VERSION ""

NS_ :

BS_:

BU_:  Inverter  Battery  Charger  Host

BO_ 2483290116 BATT_modStatus_4: 8 Battery
 SG_ BATT_modNumModsDataValid_4 : 60|4@1+ (1,0) [0|15] "" Battery,Host
 SG_ BATT_modNumModsOnNetwork_4 : 52|4@1+ (1,0) [0|15] "" Battery,Host
 SG_ BATT_modNumModsOnHvBus_4 : 56|4@1+ (1,0) [0|15] "" Battery,Host
 SG_ BATT_modNumModsConfigured_4 : 48|4@1+ (1,0) [0|15] "" Battery,Host
 SG_ BATT_ArbitrationComplete_4 : 15|1@1+ (1,0) [0|1] "" Battery,Host
 SG_ BATT_modStateRequested_4 : 46|2@1+ (1,0) [0|3] "" Battery,Host
 SG_ BATT_modDataValid_4 : 7|1@1+ (1,0) [0|1] "" Battery,Host
 SG_ BATT_prechargeState_4 : 43|3@1+ (1,0) [0|7] "" Battery,Host
 SG_ BATT_fetPchgCommand_4 : 42|1@1+ (1,0) [0|1] "" Battery,Host
 SG_ BATT_fetDsgCommand_4 : 40|1@1+ (1,0) [0|1] "" Battery,Host
 SG_ BATT_fetChgCommand_4 : 41|1@1+ (1,0) [0|1] "" Battery,Host
 SG_ BATT_fetDsgStatus_4 : 36|4@1+ (1,0) [0|15] "" Battery,Host
 SG_ BATT_fetChgStatus_4 : 32|4@1+ (1,0) [0|15] "" Battery,Host
 SG_ BATT_timeRampdown_4 : 24|6@1+ (1,0) [0|63] "seconds" Battery,Host
 SG_ BATT_inhRegen_4 : 31|1@1+ (1,0) [0|1] "" Battery,Host
 SG_ BATT_inhFullPower_4 : 23|1@1+ (1,0) [0|1] "" Battery,Host
 SG_ BATT_inhDriveEntry_4 : 22|1@1+ (1,0) [0|1] "" Battery,Host
 SG_ BATT_inhDrive_4 : 21|1@1+ (1,0) [0|1] "" Battery,Host
 SG_ BATT_inhContPower_4 : 30|1@1+ (1,0) [0|1] "" Battery,Host
 SG_ BATT_inhChargeEntry_4 : 19|1@1+ (1,0) [0|1] "" Battery,Host
 SG_ BATT_inhCharge_4 : 20|1@1+ (1,0) [0|1] "" Battery,Host
 SG_ BATT_modPackState_4 : 8|4@1+ (1,0) [0|15] "" Battery,Host
 SG_ BATT_modPchgChargeID_4 : 12|3@1+ (1,0) [0|7] "" Battery,Host
 SG_ BATT_modChildState_4 : 3|4@1+ (1,0) [0|15] "" Battery,Host
 SG_ BATT_modPchgDriveID_4 : 16|3@1+ (1,0) [0|7] "" Battery,Host
 SG_ BATT_modParentState_4 : 0|3@1+ (1,0) [0|4] "" Battery,Host

BO_ 2483290117 BATT_modStatus_5: 8 Battery
 SG_ BATT_modNumModsDataValid_5 : 60|4@1+ (1,0) [0|15] "" Battery,Host
 SG_ BATT_modNumModsOnNetwork_5 : 52|4@1+ (1,0) [0|15] "" Battery,Host
 SG_ BATT_modNumModsOnHvBus_5 : 56|4@1+ (1,0) [0|15] "" Battery,Host
 SG_ BATT_modNumModsConfigured_5 : 48|4@1+ (1,0) [0|15] "" Battery,Host
 SG_ BATT_ArbitrationComplete_5 : 15|1@1+ (1,0) [0|1] "" Battery,Host
 SG_ BATT_modStateRequested_5 : 46|2@1+ (1,0) [0|3] "" Battery,Host
 SG_ BATT_modDataValid_5 : 7|1@1+ (1,0) [0|1] "" Battery,Host
 SG_ BATT_prechargeState_5 : 43|3@1+ (1,0) [0|7] "" Battery,Host
 SG_ BATT_fetPchgCommand_5 : 42|1@1+ (1,0) [0|1] "" Battery,Host
 SG_ BATT_fetDsgCommand_5 : 40|1@1+ (1,0) [0|1] "" Battery,Host
 SG_ BATT_fetChgCommand_5 : 41|1@1+ (1,0) [0|1] "" Battery,Host
 SG_ BATT_fetDsgStatus_5 : 36|4@1+ (1,0) [0|15] "" Battery,Host
 SG_ BATT_fetChgStatus_5 : 32|4@1+ (1,0) [0|15] "" Battery,Host
 SG_ BATT_timeRampdown_5 : 24|6@1+ (1,0) [0|63] "seconds" Battery,Host
 SG_ BATT_inhRegen_5 : 31|1@1+ (1,0) [0|1] "" Battery,Host
 SG_ BATT_inhFullPower_5 : 23|1@1+ (1,0) [0|1] "" Battery,Host
 SG_ BATT_inhDriveEntry_5 : 22|1@1+ (1,0) [0|1] "" Battery,Host
 SG_ BATT_inhDrive_5 : 21|1@1+ (1,0) [0|1] "" Battery,Host
 SG_ BATT_inhContPower_5 : 30|1@1+ (1,0) [0|1] "" Battery,Host
 SG_ BATT_inhChargeEntry_5 : 19|1@1+ (1,0) [0|1] "" Battery,Host
 SG_ BATT_inhCharge_5 : 20|1@1+ (1,0) [0|1] "" Battery,Host
 SG_ BATT_modPackState_5 : 8|4@1+ (1,0) [0|15] "" Battery,Host
 SG_ BATT_modPchgChargeID_5 : 12|3@1+ (1,0) [0|7] "" Battery,Host
 SG_ BATT_modChildState_5 : 3|4@1+ (1,0) [0|15] "" Battery,Host
 SG_ BATT_modPchgDriveID_5 : 16|3@1+ (1,0) [0|7] "" Battery,Host
 SG_ BATT_modParentState_5 : 0|3@1+ (1,0) [0|4] "" Battery,Host

BO_ 2483290118 BATT_modStatus_6: 8 Battery
 SG_ BATT_modNumModsDataValid_6 : 60|4@1+ (1,0) [0|15] "" Battery,Host
 SG_ BATT_modNumModsOnNetwork_6 : 52|4@1+ (1,0) [0|15] "" Battery,Host
 SG_ BATT_modNumModsOnHvBus_6 : 56|4@1+ (1,0) [0|15] "" Battery,Host
 SG_ BATT_modNumModsConfigured_6 : 48|4@1+ (1,0) [0|15] "" Battery,Host
 SG_ BATT_ArbitrationComplete_6 : 15|1@1+ (1,0) [0|1] "" Battery,Host
 SG_ BATT_modStateRequested_6 : 46|2@1+ (1,0) [0|3] "" Battery,Host
 SG_ BATT_modDataValid_6 : 7|1@1+ (1,0) [0|1] "" Battery,Host
 SG_ BATT_prechargeState_6 : 43|3@1+ (1,0) [0|7] "" Battery,Host
 SG_ BATT_fetPchgCommand_6 : 42|1@1+ (1,0) [0|1] "" Battery,Host
 SG_ BATT_fetDsgCommand_6 : 40|1@1+ (1,0) [0|1] "" Battery,Host
 SG_ BATT_fetChgCommand_6 : 41|1@1+ (1,0) [0|1] "" Battery,Host
 SG_ BATT_fetDsgStatus_6 : 36|4@1+ (1,0) [0|15] "" Battery,Host
 SG_ BATT_fetChgStatus_6 : 32|4@1+ (1,0) [0|15] "" Battery,Host
 SG_ BATT_timeRampdown_6 : 24|6@1+ (1,0) [0|63] "seconds" Battery,Host
 SG_ BATT_inhRegen_6 : 31|1@1+ (1,0) [0|1] "" Battery,Host
 SG_ BATT_inhFullPower_6 : 23|1@1+ (1,0) [0|1] "" Battery,Host
 SG_ BATT_inhDriveEntry_6 : 22|1@1+ (1,0) [0|1] "" Battery,Host
 SG_ BATT_inhDrive_6 : 21|1@1+ (1,0) [0|1] "" Battery,Host
 SG_ BATT_inhContPower_6 : 30|1@1+ (1,0) [0|1] "" Battery,Host
 SG_ BATT_inhChargeEntry_6 : 19|1@1+ (1,0) [0|1] "" Battery,Host
 SG_ BATT_inhCharge_6 : 20|1@1+ (1,0) [0|1] "" Battery,Host
 SG_ BATT_modPackState_6 : 8|4@1+ (1,0) [0|15] "" Battery,Host
 SG_ BATT_modPchgChargeID_6 : 12|3@1+ (1,0) [0|7] "" Battery,Host
 SG_ BATT_modChildState_6 : 3|4@1+ (1,0) [0|15] "" Battery,Host
 SG_ BATT_modPchgDriveID_6 : 16|3@1+ (1,0) [0|7] "" Battery,Host
 SG_ BATT_modParentState_6 : 0|3@1+ (1,0) [0|4] "" Battery,Host

BO_ 2483290119 BATT_modStatus_7: 8 Battery
 SG_ BATT_modNumModsDataValid_7 : 60|4@1+ (1,0) [0|15] "" Battery,Host
 SG_ BATT_modNumModsOnNetwork_7 : 52|4@1+ (1,0) [0|15] "" Battery,Host
 SG_ BATT_modNumModsOnHvBus_7 : 56|4@1+ (1,0) [0|15] "" Battery,Host
 SG_ BATT_modNumModsConfigured_7 : 48|4@1+ (1,0) [0|15] "" Battery,Host
 SG_ BATT_ArbitrationComplete_7 : 15|1@1+ (1,0) [0|1] "" Battery,Host
 SG_ BATT_modStateRequested_7 : 46|2@1+ (1,0) [0|3] "" Battery,Host
 SG_ BATT_modDataValid_7 : 7|1@1+ (1,0) [0|1] "" Battery,Host
 SG_ BATT_prechargeState_7 : 43|3@1+ (1,0) [0|7] "" Battery,Host
 SG_ BATT_fetPchgCommand_7 : 42|1@1+ (1,0) [0|1] "" Battery,Host
 SG_ BATT_fetDsgCommand_7 : 40|1@1+ (1,0) [0|1] "" Battery,Host
 SG_ BATT_fetChgCommand_7 : 41|1@1+ (1,0) [0|1] "" Battery,Host
 SG_ BATT_fetDsgStatus_7 : 36|4@1+ (1,0) [0|15] "" Battery,Host
 SG_ BATT_fetChgStatus_7 : 32|4@1+ (1,0) [0|15] "" Battery,Host
 SG_ BATT_timeRampdown_7 : 24|6@1+ (1,0) [0|63] "seconds" Battery,Host
 SG_ BATT_inhRegen_7 : 31|1@1+ (1,0) [0|1] "" Battery,Host
 SG_ BATT_inhFullPower_7 : 23|1@1+ (1,0) [0|1] "" Battery,Host
 SG_ BATT_inhDriveEntry_7 : 22|1@1+ (1,0) [0|1] "" Battery,Host
 SG_ BATT_inhDrive_7 : 21|1@1+ (1,0) [0|1] "" Battery,Host
 SG_ BATT_inhContPower_7 : 30|1@1+ (1,0) [0|1] "" Battery,Host
 SG_ BATT_inhChargeEntry_7 : 19|1@1+ (1,0) [0|1] "" Battery,Host
 SG_ BATT_inhCharge_7 : 20|1@1+ (1,0) [0|1] "" Battery,Host
 SG_ BATT_modPackState_7 : 8|4@1+ (1,0) [0|15] "" Battery,Host
 SG_ BATT_modPchgChargeID_7 : 12|3@1+ (1,0) [0|7] "" Battery,Host
 SG_ BATT_modChildState_7 : 3|4@1+ (1,0) [0|15] "" Battery,Host
 SG_ BATT_modPchgDriveID_7 : 16|3@1+ (1,0) [0|7] "" Battery,Host
 SG_ BATT_modParentState_7 : 0|3@1+ (1,0) [0|4] "" Battery,Host

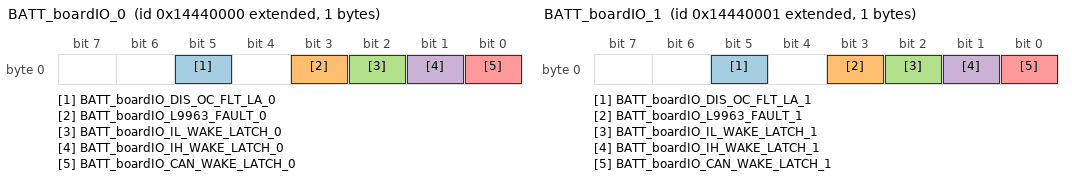
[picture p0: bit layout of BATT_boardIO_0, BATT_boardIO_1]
BO_ 2487484416 BATT_boardIO_0: 1 Battery
 SG_ BATT_boardIO_DIS_OC_FLT_LA_0 : 5|1@1+ (1,0) [0|1] "" Host
 SG_ BATT_boardIO_L9963_FAULT_0 : 3|1@1+ (1,0) [0|1] "" Host
 SG_ BATT_boardIO_IL_WAKE_LATCH_0 : 2|1@1+ (1,0) [0|1] "" Host
 SG_ BATT_boardIO_IH_WAKE_LATCH_0 : 1|1@1+ (1,0) [0|1] "" Host
 SG_ BATT_boardIO_CAN_WAKE_LATCH_0 : 0|1@1+ (1,0) [0|1] "" Host

BO_ 2487484417 BATT_boardIO_1: 1 Battery
 SG_ BATT_boardIO_DIS_OC_FLT_LA_1 : 5|1@1+ (1,0) [0|1] "" Host
 SG_ BATT_boardIO_L9963_FAULT_1 : 3|1@1+ (1,0) [0|1] "" Host
 SG_ BATT_boardIO_IL_WAKE_LATCH_1 : 2|1@1+ (1,0) [0|1] "" Host
 SG_ BATT_boardIO_IH_WAKE_LATCH_1 : 1|1@1+ (1,0) [0|1] "" Host
 SG_ BATT_boardIO_CAN_WAKE_LATCH_1 : 0|1@1+ (1,0) [0|1] "" Host

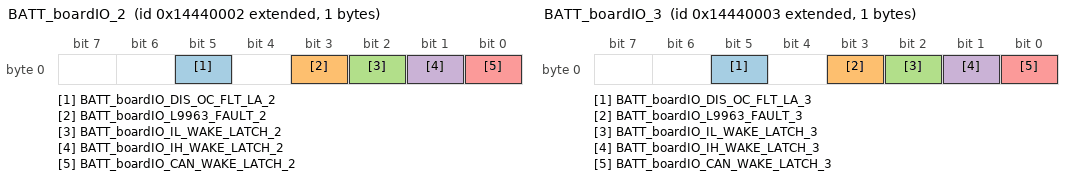
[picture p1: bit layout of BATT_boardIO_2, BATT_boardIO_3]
BO_ 2487484418 BATT_boardIO_2: 1 Battery
 SG_ BATT_boardIO_DIS_OC_FLT_LA_2 : 5|1@1+ (1,0) [0|1] "" Host
 SG_ BATT_boardIO_L9963_FAULT_2 : 3|1@1+ (1,0) [0|1] "" Host
 SG_ BATT_boardIO_IL_WAKE_LATCH_2 : 2|1@1+ (1,0) [0|1] "" Host
 SG_ BATT_boardIO_IH_WAKE_LATCH_2 : 1|1@1+ (1,0) [0|1] "" Host
 SG_ BATT_boardIO_CAN_WAKE_LATCH_2 : 0|1@1+ (1,0) [0|1] "" Host

BO_ 2487484419 BATT_boardIO_3: 1 Battery
 SG_ BATT_boardIO_DIS_OC_FLT_LA_3 : 5|1@1+ (1,0) [0|1] "" Host
 SG_ BATT_boardIO_L9963_FAULT_3 : 3|1@1+ (1,0) [0|1] "" Host
 SG_ BATT_boardIO_IL_WAKE_LATCH_3 : 2|1@1+ (1,0) [0|1] "" Host
 SG_ BATT_boardIO_IH_WAKE_LATCH_3 : 1|1@1+ (1,0) [0|1] "" Host
 SG_ BATT_boardIO_CAN_WAKE_LATCH_3 : 0|1@1+ (1,0) [0|1] "" Host

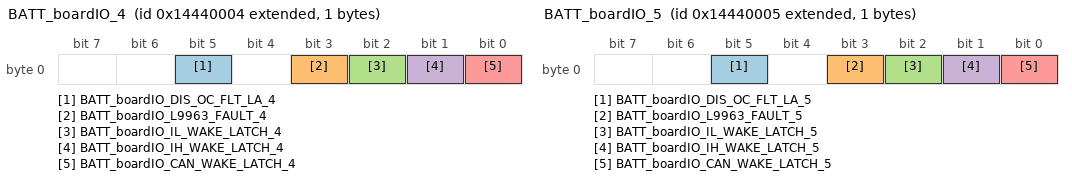
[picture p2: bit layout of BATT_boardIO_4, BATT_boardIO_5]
BO_ 2487484420 BATT_boardIO_4: 1 Battery
 SG_ BATT_boardIO_DIS_OC_FLT_LA_4 : 5|1@1+ (1,0) [0|1] "" Host
 SG_ BATT_boardIO_L9963_FAULT_4 : 3|1@1+ (1,0) [0|1] "" Host
 SG_ BATT_boardIO_IL_WAKE_LATCH_4 : 2|1@1+ (1,0) [0|1] "" Host
 SG_ BATT_boardIO_IH_WAKE_LATCH_4 : 1|1@1+ (1,0) [0|1] "" Host
 SG_ BATT_boardIO_CAN_WAKE_LATCH_4 : 0|1@1+ (1,0) [0|1] "" Host

BO_ 2487484421 BATT_boardIO_5: 1 Battery
 SG_ BATT_boardIO_DIS_OC_FLT_LA_5 : 5|1@1+ (1,0) [0|1] "" Host
 SG_ BATT_boardIO_L9963_FAULT_5 : 3|1@1+ (1,0) [0|1] "" Host
 SG_ BATT_boardIO_IL_WAKE_LATCH_5 : 2|1@1+ (1,0) [0|1] "" Host
 SG_ BATT_boardIO_IH_WAKE_LATCH_5 : 1|1@1+ (1,0) [0|1] "" Host
 SG_ BATT_boardIO_CAN_WAKE_LATCH_5 : 0|1@1+ (1,0) [0|1] "" Host

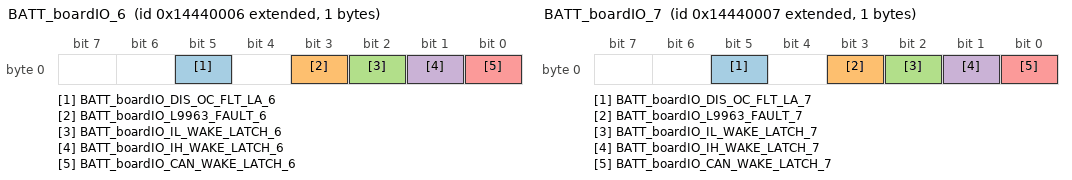
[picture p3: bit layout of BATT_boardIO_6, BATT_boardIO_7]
BO_ 2487484422 BATT_boardIO_6: 1 Battery
 SG_ BATT_boardIO_DIS_OC_FLT_LA_6 : 5|1@1+ (1,0) [0|1] "" Host
 SG_ BATT_boardIO_L9963_FAULT_6 : 3|1@1+ (1,0) [0|1] "" Host
 SG_ BATT_boardIO_IL_WAKE_LATCH_6 : 2|1@1+ (1,0) [0|1] "" Host
 SG_ BATT_boardIO_IH_WAKE_LATCH_6 : 1|1@1+ (1,0) [0|1] "" Host
 SG_ BATT_boardIO_CAN_WAKE_LATCH_6 : 0|1@1+ (1,0) [0|1] "" Host

BO_ 2487484423 BATT_boardIO_7: 1 Battery
 SG_ BATT_boardIO_DIS_OC_FLT_LA_7 : 5|1@1+ (1,0) [0|1] "" Host
 SG_ BATT_boardIO_L9963_FAULT_7 : 3|1@1+ (1,0) [0|1] "" Host
 SG_ BATT_boardIO_IL_WAKE_LATCH_7 : 2|1@1+ (1,0) [0|1] "" Host
 SG_ BATT_boardIO_IH_WAKE_LATCH_7 : 1|1@1+ (1,0) [0|1] "" Host
 SG_ BATT_boardIO_CAN_WAKE_LATCH_7 : 0|1@1+ (1,0) [0|1] "" Host

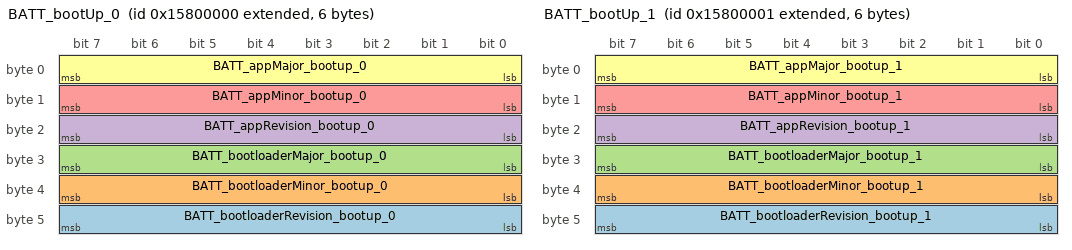
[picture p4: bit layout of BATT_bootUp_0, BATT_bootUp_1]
BO_ 2508193792 BATT_bootUp_0: 6 Battery
 SG_ BATT_bootloaderRevision_bootup_0 : 40|8@1+ (1,0) [0|255] "" Host
 SG_ BATT_bootloaderMinor_bootup_0 : 32|8@1+ (1,0) [0|255] "" Host
 SG_ BATT_bootloaderMajor_bootup_0 : 24|8@1+ (1,0) [0|255] "" Host
 SG_ BATT_appRevision_bootup_0 : 16|8@1+ (1,0) [0|255] "" Host
 SG_ BATT_appMinor_bootup_0 : 8|8@1+ (1,0) [0|255] "" Host
 SG_ BATT_appMajor_bootup_0 : 0|8@1+ (1,0) [0|255] "" Host

BO_ 2508193793 BATT_bootUp_1: 6 Battery
 SG_ BATT_bootloaderRevision_bootup_1 : 40|8@1+ (1,0) [0|255] "" Host
 SG_ BATT_bootloaderMinor_bootup_1 : 32|8@1+ (1,0) [0|255] "" Host
 SG_ BATT_bootloaderMajor_bootup_1 : 24|8@1+ (1,0) [0|255] "" Host
 SG_ BATT_appRevision_bootup_1 : 16|8@1+ (1,0) [0|255] "" Host
 SG_ BATT_appMinor_bootup_1 : 8|8@1+ (1,0) [0|255] "" Host
 SG_ BATT_appMajor_bootup_1 : 0|8@1+ (1,0) [0|255] "" Host

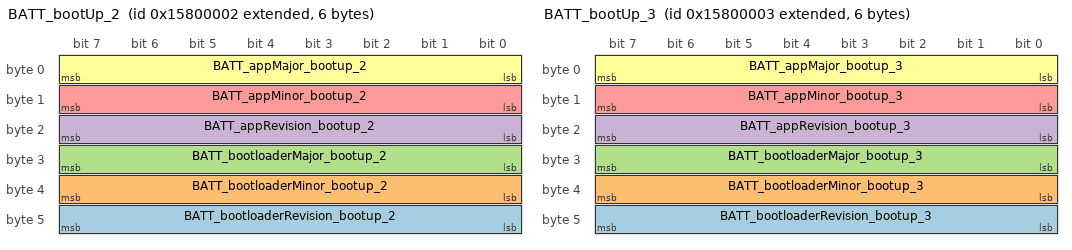
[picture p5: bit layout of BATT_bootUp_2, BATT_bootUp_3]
BO_ 2508193794 BATT_bootUp_2: 6 Battery
 SG_ BATT_bootloaderRevision_bootup_2 : 40|8@1+ (1,0) [0|255] "" Host
 SG_ BATT_bootloaderMinor_bootup_2 : 32|8@1+ (1,0) [0|255] "" Host
 SG_ BATT_bootloaderMajor_bootup_2 : 24|8@1+ (1,0) [0|255] "" Host
 SG_ BATT_appRevision_bootup_2 : 16|8@1+ (1,0) [0|255] "" Host
 SG_ BATT_appMinor_bootup_2 : 8|8@1+ (1,0) [0|255] "" Host
 SG_ BATT_appMajor_bootup_2 : 0|8@1+ (1,0) [0|255] "" Host

BO_ 2508193795 BATT_bootUp_3: 6 Battery
 SG_ BATT_bootloaderRevision_bootup_3 : 40|8@1+ (1,0) [0|255] "" Host
 SG_ BATT_bootloaderMinor_bootup_3 : 32|8@1+ (1,0) [0|255] "" Host
 SG_ BATT_bootloaderMajor_bootup_3 : 24|8@1+ (1,0) [0|255] "" Host
 SG_ BATT_appRevision_bootup_3 : 16|8@1+ (1,0) [0|255] "" Host
 SG_ BATT_appMinor_bootup_3 : 8|8@1+ (1,0) [0|255] "" Host
 SG_ BATT_appMajor_bootup_3 : 0|8@1+ (1,0) [0|255] "" Host

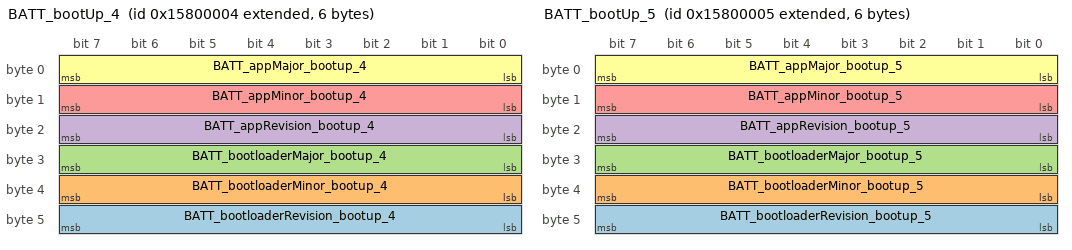
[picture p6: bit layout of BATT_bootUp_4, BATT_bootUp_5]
BO_ 2508193796 BATT_bootUp_4: 6 Battery
 SG_ BATT_bootloaderRevision_bootup_4 : 40|8@1+ (1,0) [0|255] "" Host
 SG_ BATT_bootloaderMinor_bootup_4 : 32|8@1+ (1,0) [0|255] "" Host
 SG_ BATT_bootloaderMajor_bootup_4 : 24|8@1+ (1,0) [0|255] "" Host
 SG_ BATT_appRevision_bootup_4 : 16|8@1+ (1,0) [0|255] "" Host
 SG_ BATT_appMinor_bootup_4 : 8|8@1+ (1,0) [0|255] "" Host
 SG_ BATT_appMajor_bootup_4 : 0|8@1+ (1,0) [0|255] "" Host

BO_ 2508193797 BATT_bootUp_5: 6 Battery
 SG_ BATT_bootloaderRevision_bootup_5 : 40|8@1+ (1,0) [0|255] "" Host
 SG_ BATT_bootloaderMinor_bootup_5 : 32|8@1+ (1,0) [0|255] "" Host
 SG_ BATT_bootloaderMajor_bootup_5 : 24|8@1+ (1,0) [0|255] "" Host
 SG_ BATT_appRevision_bootup_5 : 16|8@1+ (1,0) [0|255] "" Host
 SG_ BATT_appMinor_bootup_5 : 8|8@1+ (1,0) [0|255] "" Host
 SG_ BATT_appMajor_bootup_5 : 0|8@1+ (1,0) [0|255] "" Host

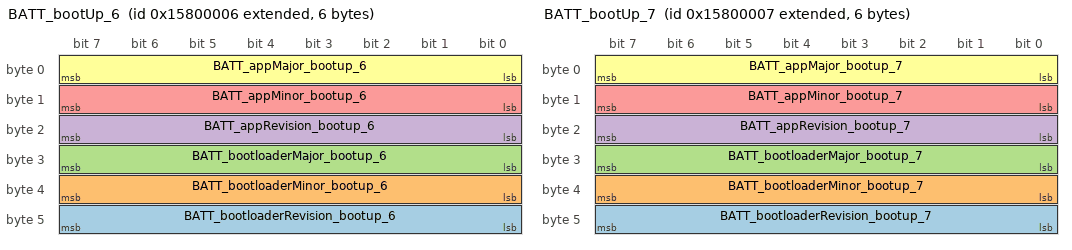
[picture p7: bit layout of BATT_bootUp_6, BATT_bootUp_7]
BO_ 2508193798 BATT_bootUp_6: 6 Battery
 SG_ BATT_bootloaderRevision_bootup_6 : 40|8@1+ (1,0) [0|255] "" Host
 SG_ BATT_bootloaderMinor_bootup_6 : 32|8@1+ (1,0) [0|255] "" Host
 SG_ BATT_bootloaderMajor_bootup_6 : 24|8@1+ (1,0) [0|255] "" Host
 SG_ BATT_appRevision_bootup_6 : 16|8@1+ (1,0) [0|255] "" Host
 SG_ BATT_appMinor_bootup_6 : 8|8@1+ (1,0) [0|255] "" Host
 SG_ BATT_appMajor_bootup_6 : 0|8@1+ (1,0) [0|255] "" Host

BO_ 2508193799 BATT_bootUp_7: 6 Battery
 SG_ BATT_bootloaderRevision_bootup_7 : 40|8@1+ (1,0) [0|255] "" Host
 SG_ BATT_bootloaderMinor_bootup_7 : 32|8@1+ (1,0) [0|255] "" Host
 SG_ BATT_bootloaderMajor_bootup_7 : 24|8@1+ (1,0) [0|255] "" Host
 SG_ BATT_appRevision_bootup_7 : 16|8@1+ (1,0) [0|255] "" Host
 SG_ BATT_appMinor_bootup_7 : 8|8@1+ (1,0) [0|255] "" Host
 SG_ BATT_appMajor_bootup_7 : 0|8@1+ (1,0) [0|255] "" Host

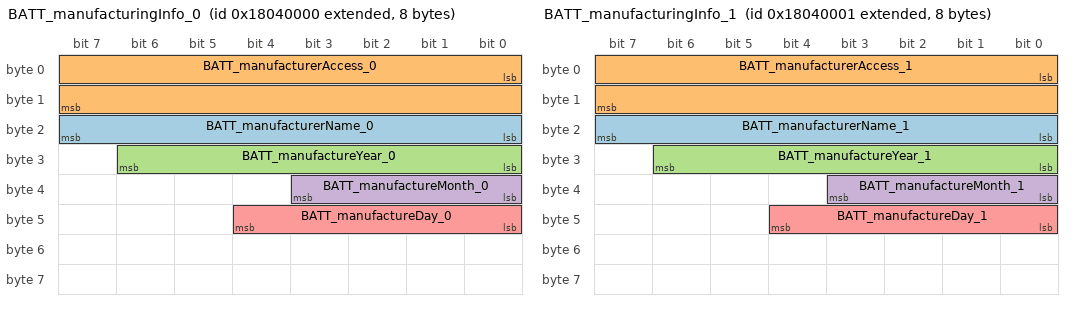
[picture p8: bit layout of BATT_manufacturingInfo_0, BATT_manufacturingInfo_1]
BO_ 2550398976 BATT_manufacturingInfo_0: 8 Battery
 SG_ BATT_manufacturerName_0 : 16|8@1+ (1,0) [0|255] "STRING" Host
 SG_ BATT_manufacturerAccess_0 : 0|16@1+ (1,0) [0|65535] "" Host
 SG_ BATT_manufactureYear_0 : 24|7@1+ (1,0) [0|127] "" Host
 SG_ BATT_manufactureMonth_0 : 32|4@1+ (1,0) [1|12] "" Host
 SG_ BATT_manufactureDay_0 : 40|5@1+ (1,0) [1|31] "" Host

BO_ 2550398977 BATT_manufacturingInfo_1: 8 Battery
 SG_ BATT_manufacturerName_1 : 16|8@1+ (1,0) [0|255] "STRING" Host
 SG_ BATT_manufacturerAccess_1 : 0|16@1+ (1,0) [0|65535] "" Host
 SG_ BATT_manufactureYear_1 : 24|7@1+ (1,0) [0|127] "" Host
 SG_ BATT_manufactureMonth_1 : 32|4@1+ (1,0) [1|12] "" Host
 SG_ BATT_manufactureDay_1 : 40|5@1+ (1,0) [1|31] "" Host

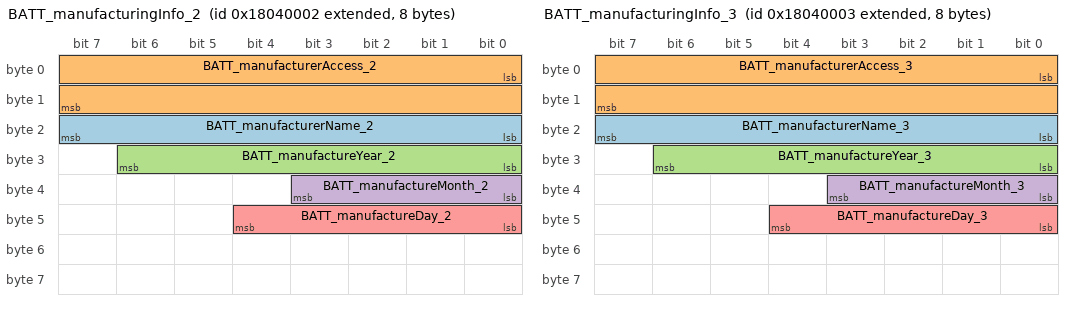
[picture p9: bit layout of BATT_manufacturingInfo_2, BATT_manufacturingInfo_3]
BO_ 2550398978 BATT_manufacturingInfo_2: 8 Battery
 SG_ BATT_manufacturerName_2 : 16|8@1+ (1,0) [0|255] "STRING" Host
 SG_ BATT_manufacturerAccess_2 : 0|16@1+ (1,0) [0|65535] "" Host
 SG_ BATT_manufactureYear_2 : 24|7@1+ (1,0) [0|127] "" Host
 SG_ BATT_manufactureMonth_2 : 32|4@1+ (1,0) [1|12] "" Host
 SG_ BATT_manufactureDay_2 : 40|5@1+ (1,0) [1|31] "" Host

BO_ 2550398979 BATT_manufacturingInfo_3: 8 Battery
 SG_ BATT_manufacturerName_3 : 16|8@1+ (1,0) [0|255] "STRING" Host
 SG_ BATT_manufacturerAccess_3 : 0|16@1+ (1,0) [0|65535] "" Host
 SG_ BATT_manufactureYear_3 : 24|7@1+ (1,0) [0|127] "" Host
 SG_ BATT_manufactureMonth_3 : 32|4@1+ (1,0) [1|12] "" Host
 SG_ BATT_manufactureDay_3 : 40|5@1+ (1,0) [1|31] "" Host

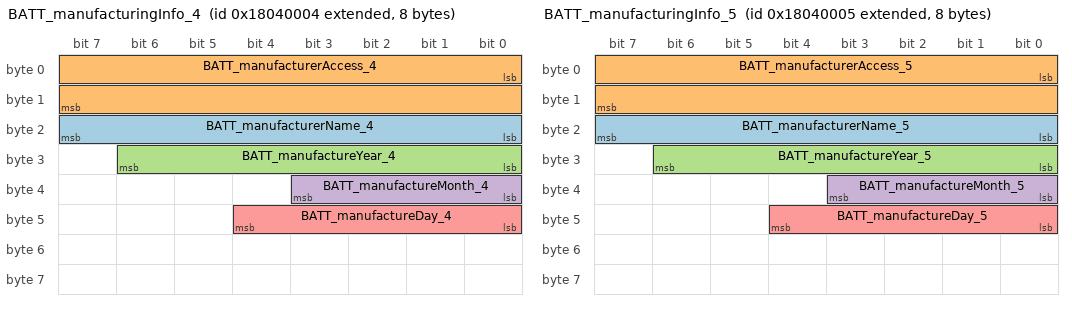
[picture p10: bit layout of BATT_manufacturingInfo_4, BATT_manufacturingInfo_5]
BO_ 2550398980 BATT_manufacturingInfo_4: 8 Battery
 SG_ BATT_manufacturerName_4 : 16|8@1+ (1,0) [0|255] "STRING" Host
 SG_ BATT_manufacturerAccess_4 : 0|16@1+ (1,0) [0|65535] "" Host
 SG_ BATT_manufactureYear_4 : 24|7@1+ (1,0) [0|127] "" Host
 SG_ BATT_manufactureMonth_4 : 32|4@1+ (1,0) [1|12] "" Host
 SG_ BATT_manufactureDay_4 : 40|5@1+ (1,0) [1|31] "" Host

BO_ 2550398981 BATT_manufacturingInfo_5: 8 Battery
 SG_ BATT_manufacturerName_5 : 16|8@1+ (1,0) [0|255] "STRING" Host
 SG_ BATT_manufacturerAccess_5 : 0|16@1+ (1,0) [0|65535] "" Host
 SG_ BATT_manufactureYear_5 : 24|7@1+ (1,0) [0|127] "" Host
 SG_ BATT_manufactureMonth_5 : 32|4@1+ (1,0) [1|12] "" Host
 SG_ BATT_manufactureDay_5 : 40|5@1+ (1,0) [1|31] "" Host

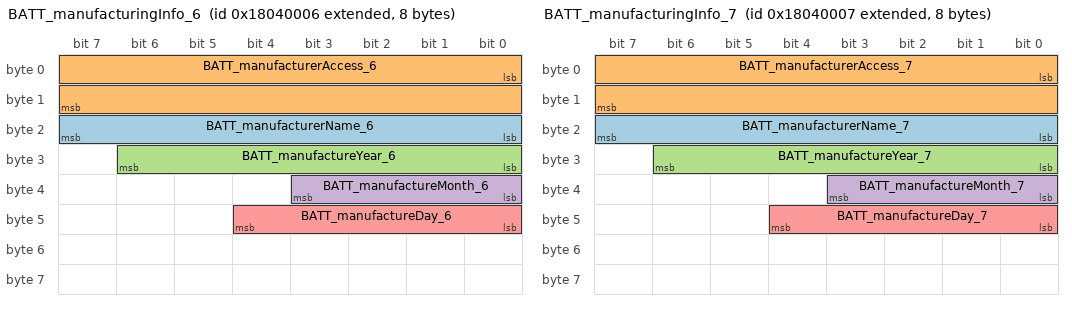
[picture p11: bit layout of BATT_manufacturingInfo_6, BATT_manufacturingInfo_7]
BO_ 2550398982 BATT_manufacturingInfo_6: 8 Battery
 SG_ BATT_manufacturerName_6 : 16|8@1+ (1,0) [0|255] "STRING" Host
 SG_ BATT_manufacturerAccess_6 : 0|16@1+ (1,0) [0|65535] "" Host
 SG_ BATT_manufactureYear_6 : 24|7@1+ (1,0) [0|127] "" Host
 SG_ BATT_manufactureMonth_6 : 32|4@1+ (1,0) [1|12] "" Host
 SG_ BATT_manufactureDay_6 : 40|5@1+ (1,0) [1|31] "" Host

BO_ 2550398983 BATT_manufacturingInfo_7: 8 Battery
 SG_ BATT_manufacturerName_7 : 16|8@1+ (1,0) [0|255] "STRING" Host
 SG_ BATT_manufacturerAccess_7 : 0|16@1+ (1,0) [0|65535] "" Host
 SG_ BATT_manufactureYear_7 : 24|7@1+ (1,0) [0|127] "" Host
 SG_ BATT_manufactureMonth_7 : 32|4@1+ (1,0) [1|12] "" Host
 SG_ BATT_manufactureDay_7 : 40|5@1+ (1,0) [1|31] "" Host

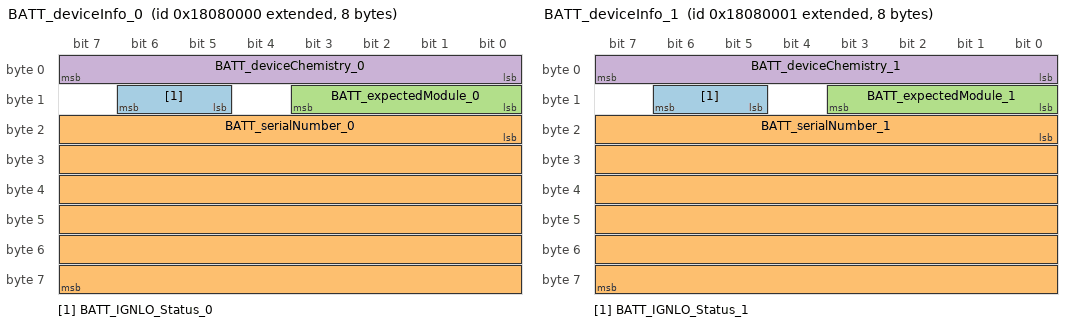
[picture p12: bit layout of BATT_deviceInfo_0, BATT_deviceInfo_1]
BO_ 2550661120 BATT_deviceInfo_0: 8 Battery
 SG_ BATT_IGNLO_Status_0 : 13|2@1+ (1,0) [0|3] "" Battery,Host
 SG_ BATT_serialNumber_0 : 16|48@1+ (1,0) [0|281474976710655] "" Battery,Host
 SG_ BATT_expectedModule_0 : 8|4@1+ (1,0) [0|15] "" Battery,Host
 SG_ BATT_deviceChemistry_0 : 0|8@1+ (1,0) [0|255] "" Battery,Host

BO_ 2550661121 BATT_deviceInfo_1: 8 Battery
 SG_ BATT_IGNLO_Status_1 : 13|2@1+ (1,0) [0|3] "" Battery,Host
 SG_ BATT_serialNumber_1 : 16|48@1+ (1,0) [0|281474976710655] "" Battery,Host
 SG_ BATT_expectedModule_1 : 8|4@1+ (1,0) [0|15] "" Battery,Host
 SG_ BATT_deviceChemistry_1 : 0|8@1+ (1,0) [0|255] "" Battery,Host

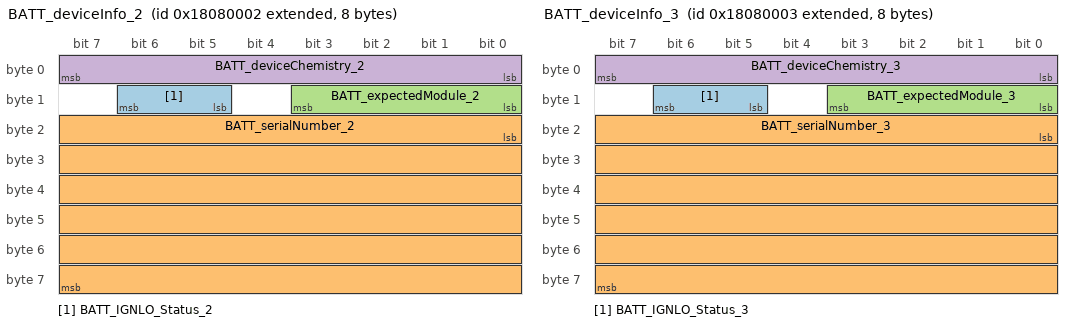
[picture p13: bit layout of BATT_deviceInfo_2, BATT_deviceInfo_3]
BO_ 2550661122 BATT_deviceInfo_2: 8 Battery
 SG_ BATT_IGNLO_Status_2 : 13|2@1+ (1,0) [0|3] "" Battery,Host
 SG_ BATT_serialNumber_2 : 16|48@1+ (1,0) [0|281474976710655] "" Battery,Host
 SG_ BATT_expectedModule_2 : 8|4@1+ (1,0) [0|15] "" Battery,Host
 SG_ BATT_deviceChemistry_2 : 0|8@1+ (1,0) [0|255] "" Battery,Host

BO_ 2550661123 BATT_deviceInfo_3: 8 Battery
 SG_ BATT_IGNLO_Status_3 : 13|2@1+ (1,0) [0|3] "" Battery,Host
 SG_ BATT_serialNumber_3 : 16|48@1+ (1,0) [0|281474976710655] "" Battery,Host
 SG_ BATT_expectedModule_3 : 8|4@1+ (1,0) [0|15] "" Battery,Host
 SG_ BATT_deviceChemistry_3 : 0|8@1+ (1,0) [0|255] "" Battery,Host

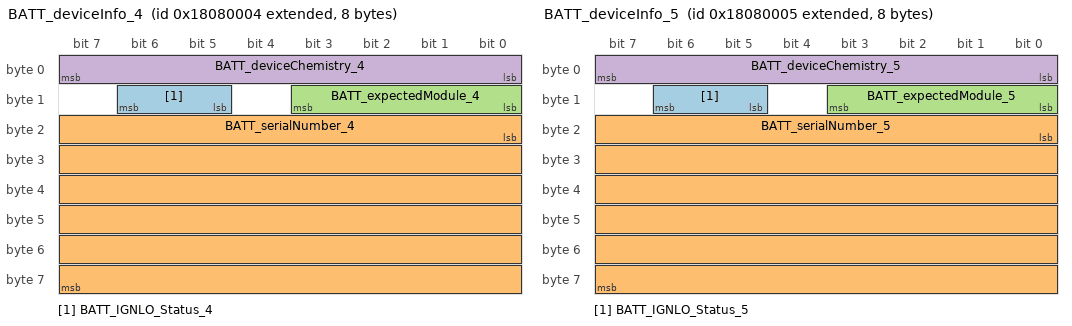
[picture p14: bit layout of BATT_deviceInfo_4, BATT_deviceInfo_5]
BO_ 2550661124 BATT_deviceInfo_4: 8 Battery
 SG_ BATT_IGNLO_Status_4 : 13|2@1+ (1,0) [0|3] "" Battery,Host
 SG_ BATT_serialNumber_4 : 16|48@1+ (1,0) [0|281474976710655] "" Battery,Host
 SG_ BATT_expectedModule_4 : 8|4@1+ (1,0) [0|15] "" Battery,Host
 SG_ BATT_deviceChemistry_4 : 0|8@1+ (1,0) [0|255] "" Battery,Host

BO_ 2550661125 BATT_deviceInfo_5: 8 Battery
 SG_ BATT_IGNLO_Status_5 : 13|2@1+ (1,0) [0|3] "" Battery,Host
 SG_ BATT_serialNumber_5 : 16|48@1+ (1,0) [0|281474976710655] "" Battery,Host
 SG_ BATT_expectedModule_5 : 8|4@1+ (1,0) [0|15] "" Battery,Host
 SG_ BATT_deviceChemistry_5 : 0|8@1+ (1,0) [0|255] "" Battery,Host

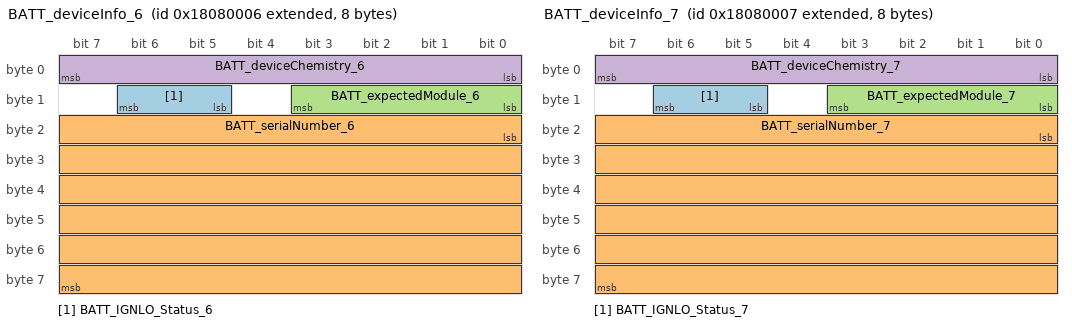
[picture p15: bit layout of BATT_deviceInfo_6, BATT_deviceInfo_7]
BO_ 2550661126 BATT_deviceInfo_6: 8 Battery
 SG_ BATT_IGNLO_Status_6 : 13|2@1+ (1,0) [0|3] "" Battery,Host
 SG_ BATT_serialNumber_6 : 16|48@1+ (1,0) [0|281474976710655] "" Battery,Host
 SG_ BATT_expectedModule_6 : 8|4@1+ (1,0) [0|15] "" Battery,Host
 SG_ BATT_deviceChemistry_6 : 0|8@1+ (1,0) [0|255] "" Battery,Host

BO_ 2550661127 BATT_deviceInfo_7: 8 Battery
 SG_ BATT_IGNLO_Status_7 : 13|2@1+ (1,0) [0|3] "" Battery,Host
 SG_ BATT_serialNumber_7 : 16|48@1+ (1,0) [0|281474976710655] "" Battery,Host
 SG_ BATT_expectedModule_7 : 8|4@1+ (1,0) [0|15] "" Battery,Host
 SG_ BATT_deviceChemistry_7 : 0|8@1+ (1,0) [0|255] "" Battery,Host

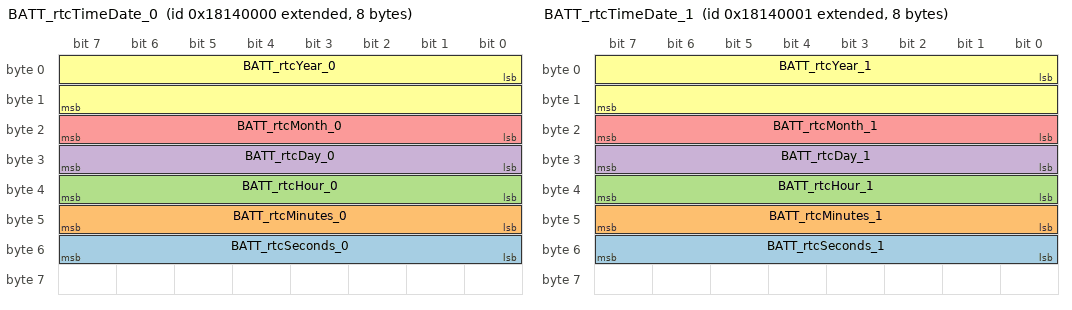
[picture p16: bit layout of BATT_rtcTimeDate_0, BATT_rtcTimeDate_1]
BO_ 2551447552 BATT_rtcTimeDate_0: 8 Battery
 SG_ BATT_rtcSeconds_0 : 48|8@1+ (1,0) [0|59] "" Host
 SG_ BATT_rtcMinutes_0 : 40|8@1+ (1,0) [0|59] "" Host
 SG_ BATT_rtcHour_0 : 32|8@1+ (1,0) [0|23] "" Host
 SG_ BATT_rtcDay_0 : 24|8@1+ (1,0) [1|31] "" Host
 SG_ BATT_rtcMonth_0 : 16|8@1+ (1,0) [1|12] "" Host
 SG_ BATT_rtcYear_0 : 0|16@1+ (1,0) [2016|2099] "" Host

BO_ 2551447553 BATT_rtcTimeDate_1: 8 Battery
 SG_ BATT_rtcSeconds_1 : 48|8@1+ (1,0) [0|59] "" Host
 SG_ BATT_rtcMinutes_1 : 40|8@1+ (1,0) [0|59] "" Host
 SG_ BATT_rtcHour_1 : 32|8@1+ (1,0) [0|23] "" Host
 SG_ BATT_rtcDay_1 : 24|8@1+ (1,0) [1|31] "" Host
 SG_ BATT_rtcMonth_1 : 16|8@1+ (1,0) [1|12] "" Host
 SG_ BATT_rtcYear_1 : 0|16@1+ (1,0) [2016|2099] "" Host

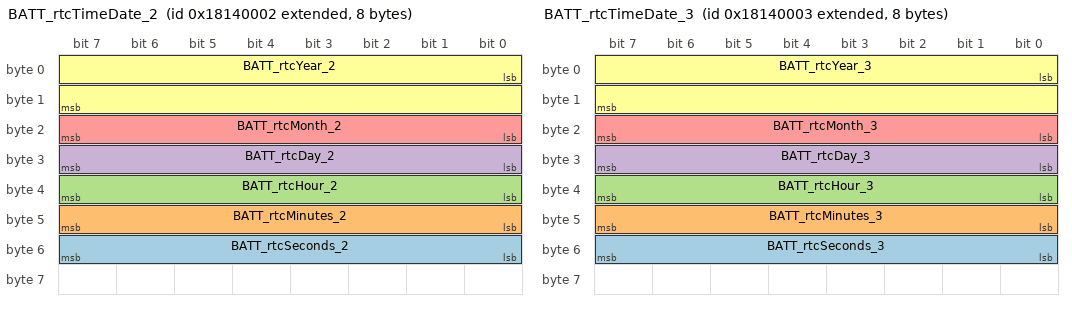
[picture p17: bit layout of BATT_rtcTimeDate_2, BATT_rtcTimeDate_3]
BO_ 2551447554 BATT_rtcTimeDate_2: 8 Battery
 SG_ BATT_rtcSeconds_2 : 48|8@1+ (1,0) [0|59] "" Host
 SG_ BATT_rtcMinutes_2 : 40|8@1+ (1,0) [0|59] "" Host
 SG_ BATT_rtcHour_2 : 32|8@1+ (1,0) [0|23] "" Host
 SG_ BATT_rtcDay_2 : 24|8@1+ (1,0) [1|31] "" Host
 SG_ BATT_rtcMonth_2 : 16|8@1+ (1,0) [1|12] "" Host
 SG_ BATT_rtcYear_2 : 0|16@1+ (1,0) [2016|2099] "" Host

BO_ 2551447555 BATT_rtcTimeDate_3: 8 Battery
 SG_ BATT_rtcSeconds_3 : 48|8@1+ (1,0) [0|59] "" Host
 SG_ BATT_rtcMinutes_3 : 40|8@1+ (1,0) [0|59] "" Host
 SG_ BATT_rtcHour_3 : 32|8@1+ (1,0) [0|23] "" Host
 SG_ BATT_rtcDay_3 : 24|8@1+ (1,0) [1|31] "" Host
 SG_ BATT_rtcMonth_3 : 16|8@1+ (1,0) [1|12] "" Host
 SG_ BATT_rtcYear_3 : 0|16@1+ (1,0) [2016|2099] "" Host

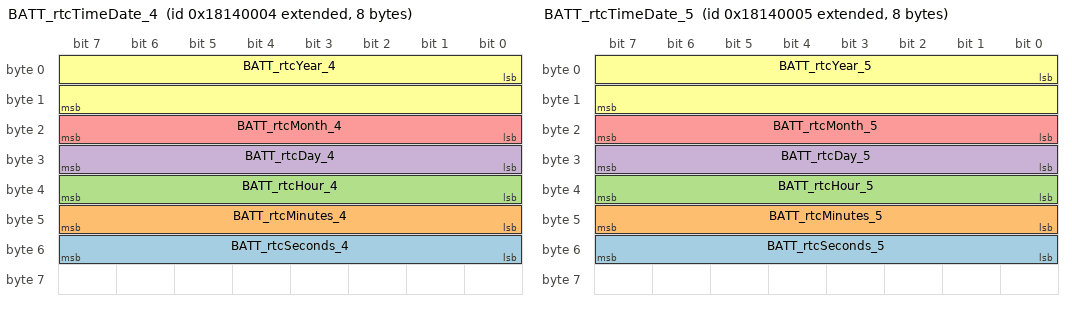
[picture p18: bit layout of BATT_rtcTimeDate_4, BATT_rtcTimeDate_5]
BO_ 2551447556 BATT_rtcTimeDate_4: 8 Battery
 SG_ BATT_rtcSeconds_4 : 48|8@1+ (1,0) [0|59] "" Host
 SG_ BATT_rtcMinutes_4 : 40|8@1+ (1,0) [0|59] "" Host
 SG_ BATT_rtcHour_4 : 32|8@1+ (1,0) [0|23] "" Host
 SG_ BATT_rtcDay_4 : 24|8@1+ (1,0) [1|31] "" Host
 SG_ BATT_rtcMonth_4 : 16|8@1+ (1,0) [1|12] "" Host
 SG_ BATT_rtcYear_4 : 0|16@1+ (1,0) [2016|2099] "" Host

BO_ 2551447557 BATT_rtcTimeDate_5: 8 Battery
 SG_ BATT_rtcSeconds_5 : 48|8@1+ (1,0) [0|59] "" Host
 SG_ BATT_rtcMinutes_5 : 40|8@1+ (1,0) [0|59] "" Host
 SG_ BATT_rtcHour_5 : 32|8@1+ (1,0) [0|23] "" Host
 SG_ BATT_rtcDay_5 : 24|8@1+ (1,0) [1|31] "" Host
 SG_ BATT_rtcMonth_5 : 16|8@1+ (1,0) [1|12] "" Host
 SG_ BATT_rtcYear_5 : 0|16@1+ (1,0) [2016|2099] "" Host

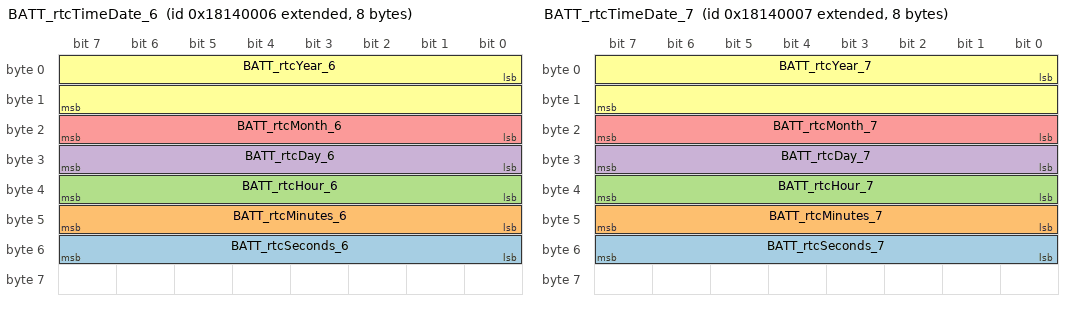
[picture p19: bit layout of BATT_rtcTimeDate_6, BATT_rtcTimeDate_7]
BO_ 2551447558 BATT_rtcTimeDate_6: 8 Battery
 SG_ BATT_rtcSeconds_6 : 48|8@1+ (1,0) [0|59] "" Host
 SG_ BATT_rtcMinutes_6 : 40|8@1+ (1,0) [0|59] "" Host
 SG_ BATT_rtcHour_6 : 32|8@1+ (1,0) [0|23] "" Host
 SG_ BATT_rtcDay_6 : 24|8@1+ (1,0) [1|31] "" Host
 SG_ BATT_rtcMonth_6 : 16|8@1+ (1,0) [1|12] "" Host
 SG_ BATT_rtcYear_6 : 0|16@1+ (1,0) [2016|2099] "" Host

BO_ 2551447559 BATT_rtcTimeDate_7: 8 Battery
 SG_ BATT_rtcSeconds_7 : 48|8@1+ (1,0) [0|59] "" Host
 SG_ BATT_rtcMinutes_7 : 40|8@1+ (1,0) [0|59] "" Host
 SG_ BATT_rtcHour_7 : 32|8@1+ (1,0) [0|23] "" Host
 SG_ BATT_rtcDay_7 : 24|8@1+ (1,0) [1|31] "" Host
 SG_ BATT_rtcMonth_7 : 16|8@1+ (1,0) [1|12] "" Host
 SG_ BATT_rtcYear_7 : 0|16@1+ (1,0) [2016|2099] "" Host

BO_ 2571108352 BATT_eventMatrix_A_0: 8 Battery
 SG_ BATT_packModIdFault_0 : 8|1@1+ (1,0) [0|1] "" Host
 SG_ BATT_packModExitedFromBus_0 : 16|1@1+ (1,0) [0|1] "" Host
 SG_ BATT_packFetChgWelded_0 : 35|1@1+ (1,0) [0|1] "" Host
 SG_ BATT_packFetDsgWelded_0 : 36|1@1+ (1,0) [0|1] "" Host
 SG_ BATT_fetDsgShortedAux_0 : 63|1@1+ (1,0) [0|1] "" Host
 SG_ BATT_fetChgShortedAux_0 : 25|1@1+ (1,0) [0|1] "" Host
 SG_ BATT_prechargeFetFail_0 : 39|1@1+ (1,0) [0|1] "" Host
 SG_ BATT_abnormalResetReason_0 : 31|1@1+ (1,0) [0|1] "" Host
 SG_ BATT_prechargeTooSlow_0 : 49|1@1+ (1,0) [0|1] "" Host
 SG_ BATT_prechargeTooFast_0 : 50|1@1+ (1,0) [0|1] "" Host
 SG_ BATT_prechargeTimeout_0 : 51|1@1+ (1,0) [0|1] "" Host
 SG_ BATT_fetChgShorted_0 : 23|1@1+ (1,0) [0|1] "" Host
 SG_ BATT_fetChgFailToClose_0 : 22|1@1+ (1,0) [0|1] "" Host
 SG_ BATT_packModSelectFault_0 : 21|1@1+ (1,0) [0|1] "" Host
 SG_ BATT_packModConnectFault_0 : 20|1@1+ (1,0) [0|1] "" Host
 SG_ BATT_packModMIA_0 : 19|1@1+ (1,0) [0|1] "" Host
 SG_ BATT_packModImbalance_0 : 18|1@1+ (1,0) [0|1] "" Host
 SG_ BATT_afeFault_0 : 17|1@1+ (1,0) [0|1] "" Host
 SG_ BATT_chargerMIA_0 : 60|1@1+ (1,0) [0|1] "" Host
 SG_ BATT_chargerError_0 : 59|1@1+ (1,0) [0|1] "" Host
 SG_ BATT_vBrickUnderWar_0 : 58|1@1+ (1,0) [0|1] "" Host
 SG_ BATT_vBrickUnderSev_0 : 57|1@1+ (1,0) [0|1] "" Host
 SG_ BATT_vBrickUnderMod_0 : 56|1@1+ (1,0) [0|1] "" Host
 SG_ BATT_vBrickOverWar_0 : 55|1@1+ (1,0) [0|1] "" Host
 SG_ BATT_vBrickOverSev_0 : 54|1@1+ (1,0) [0|1] "" Host
 SG_ BATT_vBrickOverMod_0 : 53|1@1+ (1,0) [0|1] "" Host
 SG_ BATT_vBrickImbalance_0 : 52|1@1+ (1,0) [0|1] "" Host
 SG_ BATT_loggerAlmostFull_0 : 61|1@1+ (1,0) [0|1] "" Host
 SG_ BATT_tempModuleUnderWar_0 : 48|1@1+ (1,0) [0|1] "" Host
 SG_ BATT_tempModuleUnderSev_0 : 47|1@1+ (1,0) [0|1] "" Host
 SG_ BATT_tempModuleUnderMod_0 : 46|1@1+ (1,0) [0|1] "" Host
 SG_ BATT_tempModuleOverWar_0 : 45|1@1+ (1,0) [0|1] "" Host
 SG_ BATT_tempModuleOverSev_0 : 44|1@1+ (1,0) [0|1] "" Host
 SG_ BATT_tempModuleOverMod_0 : 43|1@1+ (1,0) [0|1] "" Host
 SG_ BATT_tempBrickImbalance_0 : 42|1@1+ (1,0) [0|1] "" Host
 SG_ BATT_taskLockupError_0 : 41|1@1+ (1,0) [0|1] "" Host
 SG_ BATT_tempAmbientOverWar_0 : 40|1@1+ (1,0) [0|1] "" Host
 SG_ BATT_tempAmbientOverSev_0 : 38|1@1+ (1,0) [0|1] "" Host
 SG_ BATT_tempAmbientOverMod_0 : 37|1@1+ (1,0) [0|1] "" Host
 SG_ BATT_sensePackVoltError_0 : 34|1@1+ (1,0) [0|1] "" Host
 SG_ BATT_senseLoadVoltError_0 : 33|1@1+ (1,0) [0|1] "" Host
 SG_ BATT_loggerFull_0 : 62|1@1+ (1,0) [0|1] "" Host
 SG_ BATT_senseCurrentError_0 : 32|1@1+ (1,0) [0|1] "" Host
 SG_ BATT_senseBrickTempError_0 : 30|1@1+ (1,0) [0|1] "" Host
 SG_ BATT_resPackHigh_0 : 29|1@1+ (1,0) [0|1] "" Host
 SG_ BATT_ramOverUtilError_0 : 28|1@1+ (1,0) [0|1] "" Host
 SG_ BATT_powerPackInsufficient_0 : 27|1@1+ (1,0) [0|1] "" Host
 SG_ BATT_packCellSoftShort_0 : 26|1@1+ (1,0) [0|1] "" Host
 SG_ BATT_iOverHardware_0 : 24|1@1+ (1,0) [0|1] "" Host
 SG_ BATT_fetOverTemp_0 : 15|1@1+ (1,0) [0|1] "" Host
 SG_ BATT_iOverDischarge_0 : 14|1@1+ (1,0) [0|1] "" Host
 SG_ BATT_iOverCharge_0 : 13|1@1+ (1,0) [0|1] "" Host
 SG_ BATT_inverterDriveMIA_0 : 12|1@1+ (1,0) [0|1] "" Host
 SG_ BATT_iUnderCharge_0 : 11|1@1+ (1,0) [0|1] "" Host
 SG_ BATT_hostMIA_0 : 10|1@1+ (1,0) [0|1] "" Host
 SG_ BATT_fetDsgShorted_0 : 7|1@1+ (1,0) [0|1] "" Host
 SG_ BATT_fetDsgFailToClose_0 : 6|1@1+ (1,0) [0|1] "" Host
 SG_ BATT_capLow_0 : 5|1@1+ (1,0) [0|1] "" Host
 SG_ BATT_brickOverDischarge_0 : 4|1@1+ (1,0) [0|1] "" Host
 SG_ BATT_brickOverCharge_0 : 3|1@1+ (1,0) [0|1] "" Host
 SG_ BATT_bmsProcessorError_0 : 2|1@1+ (1,0) [0|1] "" Host
 SG_ BATT_bmsMemoryError_0 : 1|1@1+ (1,0) [0|1] "" Host
 SG_ BATT_afeError_0 : 0|1@1+ (1,0) [0|1] "" Host

BO_ 2571108353 BATT_eventMatrix_A_1: 8 Battery
 SG_ BATT_packModIdFault_1 : 8|1@1+ (1,0) [0|1] "" Host
 SG_ BATT_packModExitedFromBus_1 : 16|1@1+ (1,0) [0|1] "" Host
 SG_ BATT_packFetChgWelded_1 : 35|1@1+ (1,0) [0|1] "" Host
 SG_ BATT_packFetDsgWelded_1 : 36|1@1+ (1,0) [0|1] "" Host
 SG_ BATT_fetDsgShortedAux_1 : 63|1@1+ (1,0) [0|1] "" Host
 SG_ BATT_fetChgShortedAux_1 : 25|1@1+ (1,0) [0|1] "" Host
 SG_ BATT_prechargeFetFail_1 : 39|1@1+ (1,0) [0|1] "" Host
 SG_ BATT_abnormalResetReason_1 : 31|1@1+ (1,0) [0|1] "" Host
 SG_ BATT_prechargeTooSlow_1 : 49|1@1+ (1,0) [0|1] "" Host
 SG_ BATT_prechargeTooFast_1 : 50|1@1+ (1,0) [0|1] "" Host
 SG_ BATT_prechargeTimeout_1 : 51|1@1+ (1,0) [0|1] "" Host
 SG_ BATT_fetChgShorted_1 : 23|1@1+ (1,0) [0|1] "" Host
 SG_ BATT_fetChgFailToClose_1 : 22|1@1+ (1,0) [0|1] "" Host
 SG_ BATT_packModSelectFault_1 : 21|1@1+ (1,0) [0|1] "" Host
 SG_ BATT_packModConnectFault_1 : 20|1@1+ (1,0) [0|1] "" Host
 SG_ BATT_packModMIA_1 : 19|1@1+ (1,0) [0|1] "" Host
 SG_ BATT_packModImbalance_1 : 18|1@1+ (1,0) [0|1] "" Host
 SG_ BATT_afeFault_1 : 17|1@1+ (1,0) [0|1] "" Host
 SG_ BATT_chargerMIA_1 : 60|1@1+ (1,0) [0|1] "" Host
 SG_ BATT_chargerError_1 : 59|1@1+ (1,0) [0|1] "" Host
 SG_ BATT_vBrickUnderWar_1 : 58|1@1+ (1,0) [0|1] "" Host
 SG_ BATT_vBrickUnderSev_1 : 57|1@1+ (1,0) [0|1] "" Host
 SG_ BATT_vBrickUnderMod_1 : 56|1@1+ (1,0) [0|1] "" Host
 SG_ BATT_vBrickOverWar_1 : 55|1@1+ (1,0) [0|1] "" Host
 SG_ BATT_vBrickOverSev_1 : 54|1@1+ (1,0) [0|1] "" Host
 SG_ BATT_vBrickOverMod_1 : 53|1@1+ (1,0) [0|1] "" Host
 SG_ BATT_vBrickImbalance_1 : 52|1@1+ (1,0) [0|1] "" Host
 SG_ BATT_loggerAlmostFull_1 : 61|1@1+ (1,0) [0|1] "" Host
 SG_ BATT_tempModuleUnderWar_1 : 48|1@1+ (1,0) [0|1] "" Host
 SG_ BATT_tempModuleUnderSev_1 : 47|1@1+ (1,0) [0|1] "" Host
 SG_ BATT_tempModuleUnderMod_1 : 46|1@1+ (1,0) [0|1] "" Host
 SG_ BATT_tempModuleOverWar_1 : 45|1@1+ (1,0) [0|1] "" Host
 SG_ BATT_tempModuleOverSev_1 : 44|1@1+ (1,0) [0|1] "" Host
 SG_ BATT_tempModuleOverMod_1 : 43|1@1+ (1,0) [0|1] "" Host
 SG_ BATT_tempBrickImbalance_1 : 42|1@1+ (1,0) [0|1] "" Host
 SG_ BATT_taskLockupError_1 : 41|1@1+ (1,0) [0|1] "" Host
 SG_ BATT_tempAmbientOverWar_1 : 40|1@1+ (1,0) [0|1] "" Host
 SG_ BATT_tempAmbientOverSev_1 : 38|1@1+ (1,0) [0|1] "" Host
 SG_ BATT_tempAmbientOverMod_1 : 37|1@1+ (1,0) [0|1] "" Host
 SG_ BATT_sensePackVoltError_1 : 34|1@1+ (1,0) [0|1] "" Host
 SG_ BATT_senseLoadVoltError_1 : 33|1@1+ (1,0) [0|1] "" Host
 SG_ BATT_loggerFull_1 : 62|1@1+ (1,0) [0|1] "" Host
 SG_ BATT_senseCurrentError_1 : 32|1@1+ (1,0) [0|1] "" Host
 SG_ BATT_senseBrickTempError_1 : 30|1@1+ (1,0) [0|1] "" Host
 SG_ BATT_resPackHigh_1 : 29|1@1+ (1,0) [0|1] "" Host
 SG_ BATT_ramOverUtilError_1 : 28|1@1+ (1,0) [0|1] "" Host
 SG_ BATT_powerPackInsufficient_1 : 27|1@1+ (1,0) [0|1] "" Host
 SG_ BATT_packCellSoftShort_1 : 26|1@1+ (1,0) [0|1] "" Host
 SG_ BATT_iOverHardware_1 : 24|1@1+ (1,0) [0|1] "" Host
 SG_ BATT_fetOverTemp_1 : 15|1@1+ (1,0) [0|1] "" Host
 SG_ BATT_iOverDischarge_1 : 14|1@1+ (1,0) [0|1] "" Host
 SG_ BATT_iOverCharge_1 : 13|1@1+ (1,0) [0|1] "" Host
 SG_ BATT_inverterDriveMIA_1 : 12|1@1+ (1,0) [0|1] "" Host
 SG_ BATT_iUnderCharge_1 : 11|1@1+ (1,0) [0|1] "" Host
 SG_ BATT_hostMIA_1 : 10|1@1+ (1,0) [0|1] "" Host
 SG_ BATT_fetDsgShorted_1 : 7|1@1+ (1,0) [0|1] "" Host
 SG_ BATT_fetDsgFailToClose_1 : 6|1@1+ (1,0) [0|1] "" Host
 SG_ BATT_capLow_1 : 5|1@1+ (1,0) [0|1] "" Host
 SG_ BATT_brickOverDischarge_1 : 4|1@1+ (1,0) [0|1] "" Host
 SG_ BATT_brickOverCharge_1 : 3|1@1+ (1,0) [0|1] "" Host
 SG_ BATT_bmsProcessorError_1 : 2|1@1+ (1,0) [0|1] "" Host
 SG_ BATT_bmsMemoryError_1 : 1|1@1+ (1,0) [0|1] "" Host
 SG_ BATT_afeError_1 : 0|1@1+ (1,0) [0|1] "" Host

BO_ 2571108354 BATT_eventMatrix_A_2: 8 Battery
 SG_ BATT_packModIdFault_2 : 8|1@1+ (1,0) [0|1] "" Host
 SG_ BATT_packModExitedFromBus_2 : 16|1@1+ (1,0) [0|1] "" Host
 SG_ BATT_packFetChgWelded_2 : 35|1@1+ (1,0) [0|1] "" Host
 SG_ BATT_packFetDsgWelded_2 : 36|1@1+ (1,0) [0|1] "" Host
 SG_ BATT_fetDsgShortedAux_2 : 63|1@1+ (1,0) [0|1] "" Host
 SG_ BATT_fetChgShortedAux_2 : 25|1@1+ (1,0) [0|1] "" Host
 SG_ BATT_prechargeFetFail_2 : 39|1@1+ (1,0) [0|1] "" Host
 SG_ BATT_abnormalResetReason_2 : 31|1@1+ (1,0) [0|1] "" Host
 SG_ BATT_prechargeTooSlow_2 : 49|1@1+ (1,0) [0|1] "" Host
 SG_ BATT_prechargeTooFast_2 : 50|1@1+ (1,0) [0|1] "" Host
 SG_ BATT_prechargeTimeout_2 : 51|1@1+ (1,0) [0|1] "" Host
 SG_ BATT_fetChgShorted_2 : 23|1@1+ (1,0) [0|1] "" Host
 SG_ BATT_fetChgFailToClose_2 : 22|1@1+ (1,0) [0|1] "" Host
 SG_ BATT_packModSelectFault_2 : 21|1@1+ (1,0) [0|1] "" Host
 SG_ BATT_packModConnectFault_2 : 20|1@1+ (1,0) [0|1] "" Host
 SG_ BATT_packModMIA_2 : 19|1@1+ (1,0) [0|1] "" Host
 SG_ BATT_packModImbalance_2 : 18|1@1+ (1,0) [0|1] "" Host
 SG_ BATT_afeFault_2 : 17|1@1+ (1,0) [0|1] "" Host
 SG_ BATT_chargerMIA_2 : 60|1@1+ (1,0) [0|1] "" Host
 SG_ BATT_chargerError_2 : 59|1@1+ (1,0) [0|1] "" Host
 SG_ BATT_vBrickUnderWar_2 : 58|1@1+ (1,0) [0|1] "" Host
 SG_ BATT_vBrickUnderSev_2 : 57|1@1+ (1,0) [0|1] "" Host
 SG_ BATT_vBrickUnderMod_2 : 56|1@1+ (1,0) [0|1] "" Host
 SG_ BATT_vBrickOverWar_2 : 55|1@1+ (1,0) [0|1] "" Host
 SG_ BATT_vBrickOverSev_2 : 54|1@1+ (1,0) [0|1] "" Host
 SG_ BATT_vBrickOverMod_2 : 53|1@1+ (1,0) [0|1] "" Host
 SG_ BATT_vBrickImbalance_2 : 52|1@1+ (1,0) [0|1] "" Host
 SG_ BATT_loggerAlmostFull_2 : 61|1@1+ (1,0) [0|1] "" Host
 SG_ BATT_tempModuleUnderWar_2 : 48|1@1+ (1,0) [0|1] "" Host
 SG_ BATT_tempModuleUnderSev_2 : 47|1@1+ (1,0) [0|1] "" Host
 SG_ BATT_tempModuleUnderMod_2 : 46|1@1+ (1,0) [0|1] "" Host
 SG_ BATT_tempModuleOverWar_2 : 45|1@1+ (1,0) [0|1] "" Host
 SG_ BATT_tempModuleOverSev_2 : 44|1@1+ (1,0) [0|1] "" Host
 SG_ BATT_tempModuleOverMod_2 : 43|1@1+ (1,0) [0|1] "" Host
 SG_ BATT_tempBrickImbalance_2 : 42|1@1+ (1,0) [0|1] "" Host
 SG_ BATT_taskLockupError_2 : 41|1@1+ (1,0) [0|1] "" Host
 SG_ BATT_tempAmbientOverWar_2 : 40|1@1+ (1,0) [0|1] "" Host
 SG_ BATT_tempAmbientOverSev_2 : 38|1@1+ (1,0) [0|1] "" Host
 SG_ BATT_tempAmbientOverMod_2 : 37|1@1+ (1,0) [0|1] "" Host
 SG_ BATT_sensePackVoltError_2 : 34|1@1+ (1,0) [0|1] "" Host
 SG_ BATT_senseLoadVoltError_2 : 33|1@1+ (1,0) [0|1] "" Host
 SG_ BATT_loggerFull_2 : 62|1@1+ (1,0) [0|1] "" Host
 SG_ BATT_senseCurrentError_2 : 32|1@1+ (1,0) [0|1] "" Host
 SG_ BATT_senseBrickTempError_2 : 30|1@1+ (1,0) [0|1] "" Host
 SG_ BATT_resPackHigh_2 : 29|1@1+ (1,0) [0|1] "" Host
 SG_ BATT_ramOverUtilError_2 : 28|1@1+ (1,0) [0|1] "" Host
 SG_ BATT_powerPackInsufficient_2 : 27|1@1+ (1,0) [0|1] "" Host
 SG_ BATT_packCellSoftShort_2 : 26|1@1+ (1,0) [0|1] "" Host
 SG_ BATT_iOverHardware_2 : 24|1@1+ (1,0) [0|1] "" Host
 SG_ BATT_fetOverTemp_2 : 15|1@1+ (1,0) [0|1] "" Host
 SG_ BATT_iOverDischarge_2 : 14|1@1+ (1,0) [0|1] "" Host
 SG_ BATT_iOverCharge_2 : 13|1@1+ (1,0) [0|1] "" Host
 SG_ BATT_inverterDriveMIA_2 : 12|1@1+ (1,0) [0|1] "" Host
 SG_ BATT_iUnderCharge_2 : 11|1@1+ (1,0) [0|1] "" Host
 SG_ BATT_hostMIA_2 : 10|1@1+ (1,0) [0|1] "" Host
 SG_ BATT_fetDsgShorted_2 : 7|1@1+ (1,0) [0|1] "" Host
 SG_ BATT_fetDsgFailToClose_2 : 6|1@1+ (1,0) [0|1] "" Host
 SG_ BATT_capLow_2 : 5|1@1+ (1,0) [0|1] "" Host
 SG_ BATT_brickOverDischarge_2 : 4|1@1+ (1,0) [0|1] "" Host
 SG_ BATT_brickOverCharge_2 : 3|1@1+ (1,0) [0|1] "" Host
 SG_ BATT_bmsProcessorError_2 : 2|1@1+ (1,0) [0|1] "" Host
 SG_ BATT_bmsMemoryError_2 : 1|1@1+ (1,0) [0|1] "" Host
 SG_ BATT_afeError_2 : 0|1@1+ (1,0) [0|1] "" Host

BO_ 2571108355 BATT_eventMatrix_A_3: 8 Battery
 SG_ BATT_packModIdFault_3 : 8|1@1+ (1,0) [0|1] "" Host
 SG_ BATT_packModExitedFromBus_3 : 16|1@1+ (1,0) [0|1] "" Host
 SG_ BATT_packFetChgWelded_3 : 35|1@1+ (1,0) [0|1] "" Host
 SG_ BATT_packFetDsgWelded_3 : 36|1@1+ (1,0) [0|1] "" Host
 SG_ BATT_fetDsgShortedAux_3 : 63|1@1+ (1,0) [0|1] "" Host
 SG_ BATT_fetChgShortedAux_3 : 25|1@1+ (1,0) [0|1] "" Host
 SG_ BATT_prechargeFetFail_3 : 39|1@1+ (1,0) [0|1] "" Host
 SG_ BATT_abnormalResetReason_3 : 31|1@1+ (1,0) [0|1] "" Host
 SG_ BATT_prechargeTooSlow_3 : 49|1@1+ (1,0) [0|1] "" Host
 SG_ BATT_prechargeTooFast_3 : 50|1@1+ (1,0) [0|1] "" Host
 SG_ BATT_prechargeTimeout_3 : 51|1@1+ (1,0) [0|1] "" Host
 SG_ BATT_fetChgShorted_3 : 23|1@1+ (1,0) [0|1] "" Host
 SG_ BATT_fetChgFailToClose_3 : 22|1@1+ (1,0) [0|1] "" Host
 SG_ BATT_packModSelectFault_3 : 21|1@1+ (1,0) [0|1] "" Host
 SG_ BATT_packModConnectFault_3 : 20|1@1+ (1,0) [0|1] "" Host
 SG_ BATT_packModMIA_3 : 19|1@1+ (1,0) [0|1] "" Host
 SG_ BATT_packModImbalance_3 : 18|1@1+ (1,0) [0|1] "" Host
 SG_ BATT_afeFault_3 : 17|1@1+ (1,0) [0|1] "" Host
 SG_ BATT_chargerMIA_3 : 60|1@1+ (1,0) [0|1] "" Host
 SG_ BATT_chargerError_3 : 59|1@1+ (1,0) [0|1] "" Host
 SG_ BATT_vBrickUnderWar_3 : 58|1@1+ (1,0) [0|1] "" Host
 SG_ BATT_vBrickUnderSev_3 : 57|1@1+ (1,0) [0|1] "" Host
 SG_ BATT_vBrickUnderMod_3 : 56|1@1+ (1,0) [0|1] "" Host
 SG_ BATT_vBrickOverWar_3 : 55|1@1+ (1,0) [0|1] "" Host
 SG_ BATT_vBrickOverSev_3 : 54|1@1+ (1,0) [0|1] "" Host
 SG_ BATT_vBrickOverMod_3 : 53|1@1+ (1,0) [0|1] "" Host
 SG_ BATT_vBrickImbalance_3 : 52|1@1+ (1,0) [0|1] "" Host
 SG_ BATT_loggerAlmostFull_3 : 61|1@1+ (1,0) [0|1] "" Host
 SG_ BATT_tempModuleUnderWar_3 : 48|1@1+ (1,0) [0|1] "" Host
 SG_ BATT_tempModuleUnderSev_3 : 47|1@1+ (1,0) [0|1] "" Host
 SG_ BATT_tempModuleUnderMod_3 : 46|1@1+ (1,0) [0|1] "" Host
 SG_ BATT_tempModuleOverWar_3 : 45|1@1+ (1,0) [0|1] "" Host
 SG_ BATT_tempModuleOverSev_3 : 44|1@1+ (1,0) [0|1] "" Host
 SG_ BATT_tempModuleOverMod_3 : 43|1@1+ (1,0) [0|1] "" Host
 SG_ BATT_tempBrickImbalance_3 : 42|1@1+ (1,0) [0|1] "" Host
 SG_ BATT_taskLockupError_3 : 41|1@1+ (1,0) [0|1] "" Host
 SG_ BATT_tempAmbientOverWar_3 : 40|1@1+ (1,0) [0|1] "" Host
 SG_ BATT_tempAmbientOverSev_3 : 38|1@1+ (1,0) [0|1] "" Host
 SG_ BATT_tempAmbientOverMod_3 : 37|1@1+ (1,0) [0|1] "" Host
 SG_ BATT_sensePackVoltError_3 : 34|1@1+ (1,0) [0|1] "" Host
 SG_ BATT_senseLoadVoltError_3 : 33|1@1+ (1,0) [0|1] "" Host
 SG_ BATT_loggerFull_3 : 62|1@1+ (1,0) [0|1] "" Host
 SG_ BATT_senseCurrentError_3 : 32|1@1+ (1,0) [0|1] "" Host
 SG_ BATT_senseBrickTempError_3 : 30|1@1+ (1,0) [0|1] "" Host
 SG_ BATT_resPackHigh_3 : 29|1@1+ (1,0) [0|1] "" Host
 SG_ BATT_ramOverUtilError_3 : 28|1@1+ (1,0) [0|1] "" Host
 SG_ BATT_powerPackInsufficient_3 : 27|1@1+ (1,0) [0|1] "" Host
 SG_ BATT_packCellSoftShort_3 : 26|1@1+ (1,0) [0|1] "" Host
 SG_ BATT_iOverHardware_3 : 24|1@1+ (1,0) [0|1] "" Host
 SG_ BATT_fetOverTemp_3 : 15|1@1+ (1,0) [0|1] "" Host
 SG_ BATT_iOverDischarge_3 : 14|1@1+ (1,0) [0|1] "" Host
 SG_ BATT_iOverCharge_3 : 13|1@1+ (1,0) [0|1] "" Host
 SG_ BATT_inverterDriveMIA_3 : 12|1@1+ (1,0) [0|1] "" Host
 SG_ BATT_iUnderCharge_3 : 11|1@1+ (1,0) [0|1] "" Host
 SG_ BATT_hostMIA_3 : 10|1@1+ (1,0) [0|1] "" Host
 SG_ BATT_fetDsgShorted_3 : 7|1@1+ (1,0) [0|1] "" Host
 SG_ BATT_fetDsgFailToClose_3 : 6|1@1+ (1,0) [0|1] "" Host
 SG_ BATT_capLow_3 : 5|1@1+ (1,0) [0|1] "" Host
 SG_ BATT_brickOverDischarge_3 : 4|1@1+ (1,0) [0|1] "" Host
 SG_ BATT_brickOverCharge_3 : 3|1@1+ (1,0) [0|1] "" Host
 SG_ BATT_bmsProcessorError_3 : 2|1@1+ (1,0) [0|1] "" Host
 SG_ BATT_bmsMemoryError_3 : 1|1@1+ (1,0) [0|1] "" Host
 SG_ BATT_afeError_3 : 0|1@1+ (1,0) [0|1] "" Host

BO_ 2571108356 BATT_eventMatrix_A_4: 8 Battery
 SG_ BATT_packModIdFault_4 : 8|1@1+ (1,0) [0|1] "" Host
 SG_ BATT_packModExitedFromBus_4 : 16|1@1+ (1,0) [0|1] "" Host
 SG_ BATT_packFetChgWelded_4 : 35|1@1+ (1,0) [0|1] "" Host
 SG_ BATT_packFetDsgWelded_4 : 36|1@1+ (1,0) [0|1] "" Host
 SG_ BATT_fetDsgShortedAux_4 : 63|1@1+ (1,0) [0|1] "" Host
 SG_ BATT_fetChgShortedAux_4 : 25|1@1+ (1,0) [0|1] "" Host
 SG_ BATT_prechargeFetFail_4 : 39|1@1+ (1,0) [0|1] "" Host
 SG_ BATT_abnormalResetReason_4 : 31|1@1+ (1,0) [0|1] "" Host
 SG_ BATT_prechargeTooSlow_4 : 49|1@1+ (1,0) [0|1] "" Host
 SG_ BATT_prechargeTooFast_4 : 50|1@1+ (1,0) [0|1] "" Host
 SG_ BATT_prechargeTimeout_4 : 51|1@1+ (1,0) [0|1] "" Host
 SG_ BATT_fetChgShorted_4 : 23|1@1+ (1,0) [0|1] "" Host
 SG_ BATT_fetChgFailToClose_4 : 22|1@1+ (1,0) [0|1] "" Host
 SG_ BATT_packModSelectFault_4 : 21|1@1+ (1,0) [0|1] "" Host
 SG_ BATT_packModConnectFault_4 : 20|1@1+ (1,0) [0|1] "" Host
 SG_ BATT_packModMIA_4 : 19|1@1+ (1,0) [0|1] "" Host
 SG_ BATT_packModImbalance_4 : 18|1@1+ (1,0) [0|1] "" Host
 SG_ BATT_afeFault_4 : 17|1@1+ (1,0) [0|1] "" Host
 SG_ BATT_chargerMIA_4 : 60|1@1+ (1,0) [0|1] "" Host
 SG_ BATT_chargerError_4 : 59|1@1+ (1,0) [0|1] "" Host
 SG_ BATT_vBrickUnderWar_4 : 58|1@1+ (1,0) [0|1] "" Host
 SG_ BATT_vBrickUnderSev_4 : 57|1@1+ (1,0) [0|1] "" Host
 SG_ BATT_vBrickUnderMod_4 : 56|1@1+ (1,0) [0|1] "" Host
 SG_ BATT_vBrickOverWar_4 : 55|1@1+ (1,0) [0|1] "" Host
 SG_ BATT_vBrickOverSev_4 : 54|1@1+ (1,0) [0|1] "" Host
 SG_ BATT_vBrickOverMod_4 : 53|1@1+ (1,0) [0|1] "" Host
 SG_ BATT_vBrickImbalance_4 : 52|1@1+ (1,0) [0|1] "" Host
 SG_ BATT_loggerAlmostFull_4 : 61|1@1+ (1,0) [0|1] "" Host
 SG_ BATT_tempModuleUnderWar_4 : 48|1@1+ (1,0) [0|1] "" Host
 SG_ BATT_tempModuleUnderSev_4 : 47|1@1+ (1,0) [0|1] "" Host
 SG_ BATT_tempModuleUnderMod_4 : 46|1@1+ (1,0) [0|1] "" Host
 SG_ BATT_tempModuleOverWar_4 : 45|1@1+ (1,0) [0|1] "" Host
 SG_ BATT_tempModuleOverSev_4 : 44|1@1+ (1,0) [0|1] "" Host
 SG_ BATT_tempModuleOverMod_4 : 43|1@1+ (1,0) [0|1] "" Host
 SG_ BATT_tempBrickImbalance_4 : 42|1@1+ (1,0) [0|1] "" Host
 SG_ BATT_taskLockupError_4 : 41|1@1+ (1,0) [0|1] "" Host
 SG_ BATT_tempAmbientOverWar_4 : 40|1@1+ (1,0) [0|1] "" Host
 SG_ BATT_tempAmbientOverSev_4 : 38|1@1+ (1,0) [0|1] "" Host
 SG_ BATT_tempAmbientOverMod_4 : 37|1@1+ (1,0) [0|1] "" Host
 SG_ BATT_sensePackVoltError_4 : 34|1@1+ (1,0) [0|1] "" Host
 SG_ BATT_senseLoadVoltError_4 : 33|1@1+ (1,0) [0|1] "" Host
 SG_ BATT_loggerFull_4 : 62|1@1+ (1,0) [0|1] "" Host
 SG_ BATT_senseCurrentError_4 : 32|1@1+ (1,0) [0|1] "" Host
 SG_ BATT_senseBrickTempError_4 : 30|1@1+ (1,0) [0|1] "" Host
 SG_ BATT_resPackHigh_4 : 29|1@1+ (1,0) [0|1] "" Host
 SG_ BATT_ramOverUtilError_4 : 28|1@1+ (1,0) [0|1] "" Host
 SG_ BATT_powerPackInsufficient_4 : 27|1@1+ (1,0) [0|1] "" Host
 SG_ BATT_packCellSoftShort_4 : 26|1@1+ (1,0) [0|1] "" Host
 SG_ BATT_iOverHardware_4 : 24|1@1+ (1,0) [0|1] "" Host
 SG_ BATT_fetOverTemp_4 : 15|1@1+ (1,0) [0|1] "" Host
 SG_ BATT_iOverDischarge_4 : 14|1@1+ (1,0) [0|1] "" Host
 SG_ BATT_iOverCharge_4 : 13|1@1+ (1,0) [0|1] "" Host
 SG_ BATT_inverterDriveMIA_4 : 12|1@1+ (1,0) [0|1] "" Host
 SG_ BATT_iUnderCharge_4 : 11|1@1+ (1,0) [0|1] "" Host
 SG_ BATT_hostMIA_4 : 10|1@1+ (1,0) [0|1] "" Host
 SG_ BATT_fetDsgShorted_4 : 7|1@1+ (1,0) [0|1] "" Host
 SG_ BATT_fetDsgFailToClose_4 : 6|1@1+ (1,0) [0|1] "" Host
 SG_ BATT_capLow_4 : 5|1@1+ (1,0) [0|1] "" Host
 SG_ BATT_brickOverDischarge_4 : 4|1@1+ (1,0) [0|1] "" Host
 SG_ BATT_brickOverCharge_4 : 3|1@1+ (1,0) [0|1] "" Host
 SG_ BATT_bmsProcessorError_4 : 2|1@1+ (1,0) [0|1] "" Host
 SG_ BATT_bmsMemoryError_4 : 1|1@1+ (1,0) [0|1] "" Host
 SG_ BATT_afeError_4 : 0|1@1+ (1,0) [0|1] "" Host

BO_ 2571108357 BATT_eventMatrix_A_5: 8 Battery
 SG_ BATT_packModIdFault_5 : 8|1@1+ (1,0) [0|1] "" Host
 SG_ BATT_packModExitedFromBus_5 : 16|1@1+ (1,0) [0|1] "" Host
 SG_ BATT_packFetChgWelded_5 : 35|1@1+ (1,0) [0|1] "" Host
 SG_ BATT_packFetDsgWelded_5 : 36|1@1+ (1,0) [0|1] "" Host
 SG_ BATT_fetDsgShortedAux_5 : 63|1@1+ (1,0) [0|1] "" Host
 SG_ BATT_fetChgShortedAux_5 : 25|1@1+ (1,0) [0|1] "" Host
 SG_ BATT_prechargeFetFail_5 : 39|1@1+ (1,0) [0|1] "" Host
 SG_ BATT_abnormalResetReason_5 : 31|1@1+ (1,0) [0|1] "" Host
 SG_ BATT_prechargeTooSlow_5 : 49|1@1+ (1,0) [0|1] "" Host
 SG_ BATT_prechargeTooFast_5 : 50|1@1+ (1,0) [0|1] "" Host
 SG_ BATT_prechargeTimeout_5 : 51|1@1+ (1,0) [0|1] "" Host
 SG_ BATT_fetChgShorted_5 : 23|1@1+ (1,0) [0|1] "" Host
 SG_ BATT_fetChgFailToClose_5 : 22|1@1+ (1,0) [0|1] "" Host
 SG_ BATT_packModSelectFault_5 : 21|1@1+ (1,0) [0|1] "" Host
 SG_ BATT_packModConnectFault_5 : 20|1@1+ (1,0) [0|1] "" Host
 SG_ BATT_packModMIA_5 : 19|1@1+ (1,0) [0|1] "" Host
 SG_ BATT_packModImbalance_5 : 18|1@1+ (1,0) [0|1] "" Host
 SG_ BATT_afeFault_5 : 17|1@1+ (1,0) [0|1] "" Host
 SG_ BATT_chargerMIA_5 : 60|1@1+ (1,0) [0|1] "" Host
 SG_ BATT_chargerError_5 : 59|1@1+ (1,0) [0|1] "" Host
 SG_ BATT_vBrickUnderWar_5 : 58|1@1+ (1,0) [0|1] "" Host
 SG_ BATT_vBrickUnderSev_5 : 57|1@1+ (1,0) [0|1] "" Host
 SG_ BATT_vBrickUnderMod_5 : 56|1@1+ (1,0) [0|1] "" Host
 SG_ BATT_vBrickOverWar_5 : 55|1@1+ (1,0) [0|1] "" Host
 SG_ BATT_vBrickOverSev_5 : 54|1@1+ (1,0) [0|1] "" Host
 SG_ BATT_vBrickOverMod_5 : 53|1@1+ (1,0) [0|1] "" Host
 SG_ BATT_vBrickImbalance_5 : 52|1@1+ (1,0) [0|1] "" Host
 SG_ BATT_loggerAlmostFull_5 : 61|1@1+ (1,0) [0|1] "" Host
 SG_ BATT_tempModuleUnderWar_5 : 48|1@1+ (1,0) [0|1] "" Host
 SG_ BATT_tempModuleUnderSev_5 : 47|1@1+ (1,0) [0|1] "" Host
 SG_ BATT_tempModuleUnderMod_5 : 46|1@1+ (1,0) [0|1] "" Host
 SG_ BATT_tempModuleOverWar_5 : 45|1@1+ (1,0) [0|1] "" Host
 SG_ BATT_tempModuleOverSev_5 : 44|1@1+ (1,0) [0|1] "" Host
 SG_ BATT_tempModuleOverMod_5 : 43|1@1+ (1,0) [0|1] "" Host
 SG_ BATT_tempBrickImbalance_5 : 42|1@1+ (1,0) [0|1] "" Host
 SG_ BATT_taskLockupError_5 : 41|1@1+ (1,0) [0|1] "" Host
 SG_ BATT_tempAmbientOverWar_5 : 40|1@1+ (1,0) [0|1] "" Host
 SG_ BATT_tempAmbientOverSev_5 : 38|1@1+ (1,0) [0|1] "" Host
 SG_ BATT_tempAmbientOverMod_5 : 37|1@1+ (1,0) [0|1] "" Host
 SG_ BATT_sensePackVoltError_5 : 34|1@1+ (1,0) [0|1] "" Host
 SG_ BATT_senseLoadVoltError_5 : 33|1@1+ (1,0) [0|1] "" Host
 SG_ BATT_loggerFull_5 : 62|1@1+ (1,0) [0|1] "" Host
 SG_ BATT_senseCurrentError_5 : 32|1@1+ (1,0) [0|1] "" Host
 SG_ BATT_senseBrickTempError_5 : 30|1@1+ (1,0) [0|1] "" Host
 SG_ BATT_resPackHigh_5 : 29|1@1+ (1,0) [0|1] "" Host
 SG_ BATT_ramOverUtilError_5 : 28|1@1+ (1,0) [0|1] "" Host
 SG_ BATT_powerPackInsufficient_5 : 27|1@1+ (1,0) [0|1] "" Host
 SG_ BATT_packCellSoftShort_5 : 26|1@1+ (1,0) [0|1] "" Host
 SG_ BATT_iOverHardware_5 : 24|1@1+ (1,0) [0|1] "" Host
 SG_ BATT_fetOverTemp_5 : 15|1@1+ (1,0) [0|1] "" Host
 SG_ BATT_iOverDischarge_5 : 14|1@1+ (1,0) [0|1] "" Host
 SG_ BATT_iOverCharge_5 : 13|1@1+ (1,0) [0|1] "" Host
 SG_ BATT_inverterDriveMIA_5 : 12|1@1+ (1,0) [0|1] "" Host
 SG_ BATT_iUnderCharge_5 : 11|1@1+ (1,0) [0|1] "" Host
 SG_ BATT_hostMIA_5 : 10|1@1+ (1,0) [0|1] "" Host
 SG_ BATT_fetDsgShorted_5 : 7|1@1+ (1,0) [0|1] "" Host
 SG_ BATT_fetDsgFailToClose_5 : 6|1@1+ (1,0) [0|1] "" Host
 SG_ BATT_capLow_5 : 5|1@1+ (1,0) [0|1] "" Host
 SG_ BATT_brickOverDischarge_5 : 4|1@1+ (1,0) [0|1] "" Host
 SG_ BATT_brickOverCharge_5 : 3|1@1+ (1,0) [0|1] "" Host
 SG_ BATT_bmsProcessorError_5 : 2|1@1+ (1,0) [0|1] "" Host
 SG_ BATT_bmsMemoryError_5 : 1|1@1+ (1,0) [0|1] "" Host
 SG_ BATT_afeError_5 : 0|1@1+ (1,0) [0|1] "" Host

BO_ 2571108358 BATT_eventMatrix_A_6: 8 Battery
 SG_ BATT_packModIdFault_6 : 8|1@1+ (1,0) [0|1] "" Host
 SG_ BATT_packModExitedFromBus_6 : 16|1@1+ (1,0) [0|1] "" Host
 SG_ BATT_packFetChgWelded_6 : 35|1@1+ (1,0) [0|1] "" Host
 SG_ BATT_packFetDsgWelded_6 : 36|1@1+ (1,0) [0|1] "" Host
 SG_ BATT_fetDsgShortedAux_6 : 63|1@1+ (1,0) [0|1] "" Host
 SG_ BATT_fetChgShortedAux_6 : 25|1@1+ (1,0) [0|1] "" Host
 SG_ BATT_prechargeFetFail_6 : 39|1@1+ (1,0) [0|1] "" Host
 SG_ BATT_abnormalResetReason_6 : 31|1@1+ (1,0) [0|1] "" Host
 SG_ BATT_prechargeTooSlow_6 : 49|1@1+ (1,0) [0|1] "" Host
 SG_ BATT_prechargeTooFast_6 : 50|1@1+ (1,0) [0|1] "" Host
 SG_ BATT_prechargeTimeout_6 : 51|1@1+ (1,0) [0|1] "" Host
 SG_ BATT_fetChgShorted_6 : 23|1@1+ (1,0) [0|1] "" Host
 SG_ BATT_fetChgFailToClose_6 : 22|1@1+ (1,0) [0|1] "" Host
 SG_ BATT_packModSelectFault_6 : 21|1@1+ (1,0) [0|1] "" Host
 SG_ BATT_packModConnectFault_6 : 20|1@1+ (1,0) [0|1] "" Host
 SG_ BATT_packModMIA_6 : 19|1@1+ (1,0) [0|1] "" Host
 SG_ BATT_packModImbalance_6 : 18|1@1+ (1,0) [0|1] "" Host
 SG_ BATT_afeFault_6 : 17|1@1+ (1,0) [0|1] "" Host
 SG_ BATT_chargerMIA_6 : 60|1@1+ (1,0) [0|1] "" Host
 SG_ BATT_chargerError_6 : 59|1@1+ (1,0) [0|1] "" Host
 SG_ BATT_vBrickUnderWar_6 : 58|1@1+ (1,0) [0|1] "" Host
 SG_ BATT_vBrickUnderSev_6 : 57|1@1+ (1,0) [0|1] "" Host
 SG_ BATT_vBrickUnderMod_6 : 56|1@1+ (1,0) [0|1] "" Host
 SG_ BATT_vBrickOverWar_6 : 55|1@1+ (1,0) [0|1] "" Host
 SG_ BATT_vBrickOverSev_6 : 54|1@1+ (1,0) [0|1] "" Host
 SG_ BATT_vBrickOverMod_6 : 53|1@1+ (1,0) [0|1] "" Host
 SG_ BATT_vBrickImbalance_6 : 52|1@1+ (1,0) [0|1] "" Host
 SG_ BATT_loggerAlmostFull_6 : 61|1@1+ (1,0) [0|1] "" Host
 SG_ BATT_tempModuleUnderWar_6 : 48|1@1+ (1,0) [0|1] "" Host
 SG_ BATT_tempModuleUnderSev_6 : 47|1@1+ (1,0) [0|1] "" Host
 SG_ BATT_tempModuleUnderMod_6 : 46|1@1+ (1,0) [0|1] "" Host
 SG_ BATT_tempModuleOverWar_6 : 45|1@1+ (1,0) [0|1] "" Host
 SG_ BATT_tempModuleOverSev_6 : 44|1@1+ (1,0) [0|1] "" Host
 SG_ BATT_tempModuleOverMod_6 : 43|1@1+ (1,0) [0|1] "" Host
 SG_ BATT_tempBrickImbalance_6 : 42|1@1+ (1,0) [0|1] "" Host
 SG_ BATT_taskLockupError_6 : 41|1@1+ (1,0) [0|1] "" Host
 SG_ BATT_tempAmbientOverWar_6 : 40|1@1+ (1,0) [0|1] "" Host
 SG_ BATT_tempAmbientOverSev_6 : 38|1@1+ (1,0) [0|1] "" Host
 SG_ BATT_tempAmbientOverMod_6 : 37|1@1+ (1,0) [0|1] "" Host
 SG_ BATT_sensePackVoltError_6 : 34|1@1+ (1,0) [0|1] "" Host
 SG_ BATT_senseLoadVoltError_6 : 33|1@1+ (1,0) [0|1] "" Host
 SG_ BATT_loggerFull_6 : 62|1@1+ (1,0) [0|1] "" Host
 SG_ BATT_senseCurrentError_6 : 32|1@1+ (1,0) [0|1] "" Host
 SG_ BATT_senseBrickTempError_6 : 30|1@1+ (1,0) [0|1] "" Host
 SG_ BATT_resPackHigh_6 : 29|1@1+ (1,0) [0|1] "" Host
 SG_ BATT_ramOverUtilError_6 : 28|1@1+ (1,0) [0|1] "" Host
 SG_ BATT_powerPackInsufficient_6 : 27|1@1+ (1,0) [0|1] "" Host
 SG_ BATT_packCellSoftShort_6 : 26|1@1+ (1,0) [0|1] "" Host
 SG_ BATT_iOverHardware_6 : 24|1@1+ (1,0) [0|1] "" Host
 SG_ BATT_fetOverTemp_6 : 15|1@1+ (1,0) [0|1] "" Host
 SG_ BATT_iOverDischarge_6 : 14|1@1+ (1,0) [0|1] "" Host
 SG_ BATT_iOverCharge_6 : 13|1@1+ (1,0) [0|1] "" Host
 SG_ BATT_inverterDriveMIA_6 : 12|1@1+ (1,0) [0|1] "" Host
 SG_ BATT_iUnderCharge_6 : 11|1@1+ (1,0) [0|1] "" Host
 SG_ BATT_hostMIA_6 : 10|1@1+ (1,0) [0|1] "" Host
 SG_ BATT_fetDsgShorted_6 : 7|1@1+ (1,0) [0|1] "" Host
 SG_ BATT_fetDsgFailToClose_6 : 6|1@1+ (1,0) [0|1] "" Host
 SG_ BATT_capLow_6 : 5|1@1+ (1,0) [0|1] "" Host
 SG_ BATT_brickOverDischarge_6 : 4|1@1+ (1,0) [0|1] "" Host
 SG_ BATT_brickOverCharge_6 : 3|1@1+ (1,0) [0|1] "" Host
 SG_ BATT_bmsProcessorError_6 : 2|1@1+ (1,0) [0|1] "" Host
 SG_ BATT_bmsMemoryError_6 : 1|1@1+ (1,0) [0|1] "" Host
 SG_ BATT_afeError_6 : 0|1@1+ (1,0) [0|1] "" Host

CM_ BO_ 2483290116 "Battery status";
CM_ SG_ 2483290116 BATT_modNumModsDataValid_4 "Number of parallel modules with valid data";
CM_ SG_ 2483290116 BATT_modNumModsOnNetwork_4 "Number of modules on the network";
CM_ SG_ 2483290116 BATT_modNumModsOnHvBus_4 "Number of modules on the HV bus";
CM_ SG_ 2483290116 BATT_modNumModsConfigured_4 "Number of parallel modules configured for the Module";
CM_ SG_ 2483290116 BATT_ArbitrationComplete_4 "1 - Node ID Arbitration Completed (default)
0 - Node ID Arbitration Active";
CM_ SG_ 2483290116 BATT_modStateRequested_4 "Reports the requested battery state ";
CM_ SG_ 2483290116 BATT_modDataValid_4 "Module data valid";
CM_ SG_ 2483290116 BATT_prechargeState_4 "Precharge state";
CM_ SG_ 2483290116 BATT_fetPchgCommand_4 "PCHG FET commanded state";
CM_ SG_ 2483290116 BATT_fetDsgCommand_4 "DSG FETs commanded state";
CM_ SG_ 2483290116 BATT_fetChgCommand_4 "CHG FETs commanded state";
CM_ SG_ 2483290116 BATT_fetDsgStatus_4 "DSG FETs status";
CM_ SG_ 2483290116 BATT_fetChgStatus_4 "CHG FETs status";
CM_ SG_ 2483290116 BATT_timeRampdown_4 "Ramp down time";
CM_ SG_ 2483290116 BATT_inhRegen_4 "Inhibit Regen";
CM_ SG_ 2483290116 BATT_inhFullPower_4 "Inhibit Full Power";
CM_ SG_ 2483290116 BATT_inhDriveEntry_4 "Inhibit Drive Entry";
CM_ SG_ 2483290116 BATT_inhDrive_4 "Inhibit Drive";
CM_ SG_ 2483290116 BATT_inhContPower_4 "Inhibit Continuous Power";
CM_ SG_ 2483290116 BATT_inhChargeEntry_4 "Inhibit Charge Entry";
CM_ SG_ 2483290116 BATT_inhCharge_4 "Inhibit Charge";
CM_ SG_ 2483290116 BATT_modPackState_4 "Module reported pack state";
CM_ SG_ 2483290116 BATT_modPchgChargeID_4 "ID of module calculated to do pre-charge";
CM_ SG_ 2483290116 BATT_modChildState_4 "Reports the current state of the battery";
CM_ SG_ 2483290116 BATT_modPchgDriveID_4 "ID of module calculated to do pre-charge";
CM_ SG_ 2483290116 BATT_modParentState_4 "Reports the current state of the battery";
CM_ BO_ 2483290117 "Battery status";
CM_ SG_ 2483290117 BATT_modNumModsDataValid_5 "Number of parallel modules with valid data";
CM_ SG_ 2483290117 BATT_modNumModsOnNetwork_5 "Number of modules on the network";
CM_ SG_ 2483290117 BATT_modNumModsOnHvBus_5 "Number of modules on the HV bus";
CM_ SG_ 2483290117 BATT_modNumModsConfigured_5 "Number of parallel modules configured for the Module";
CM_ SG_ 2483290117 BATT_ArbitrationComplete_5 "1 - Node ID Arbitration Completed (default)
0 - Node ID Arbitration Active";
CM_ SG_ 2483290117 BATT_modStateRequested_5 "Reports the requested battery state ";
CM_ SG_ 2483290117 BATT_modDataValid_5 "Module data valid";
CM_ SG_ 2483290117 BATT_prechargeState_5 "Precharge state";
CM_ SG_ 2483290117 BATT_fetPchgCommand_5 "PCHG FET commanded state";
CM_ SG_ 2483290117 BATT_fetDsgCommand_5 "DSG FETs commanded state";
CM_ SG_ 2483290117 BATT_fetChgCommand_5 "CHG FETs commanded state";
CM_ SG_ 2483290117 BATT_fetDsgStatus_5 "DSG FETs status";
CM_ SG_ 2483290117 BATT_fetChgStatus_5 "CHG FETs status";
CM_ SG_ 2483290117 BATT_timeRampdown_5 "Ramp down time";
CM_ SG_ 2483290117 BATT_inhRegen_5 "Inhibit Regen";
CM_ SG_ 2483290117 BATT_inhFullPower_5 "Inhibit Full Power";
CM_ SG_ 2483290117 BATT_inhDriveEntry_5 "Inhibit Drive Entry";
CM_ SG_ 2483290117 BATT_inhDrive_5 "Inhibit Drive";
CM_ SG_ 2483290117 BATT_inhContPower_5 "Inhibit Continuous Power";
CM_ SG_ 2483290117 BATT_inhChargeEntry_5 "Inhibit Charge Entry";
CM_ SG_ 2483290117 BATT_inhCharge_5 "Inhibit Charge";
CM_ SG_ 2483290117 BATT_modPackState_5 "Module reported pack state";
CM_ SG_ 2483290117 BATT_modPchgChargeID_5 "ID of module calculated to do pre-charge";
CM_ SG_ 2483290117 BATT_modChildState_5 "Reports the current state of the battery";
CM_ SG_ 2483290117 BATT_modPchgDriveID_5 "ID of module calculated to do pre-charge";
CM_ SG_ 2483290117 BATT_modParentState_5 "Reports the current state of the battery";
CM_ BO_ 2483290118 "Battery status";
CM_ SG_ 2483290118 BATT_modNumModsDataValid_6 "Number of parallel modules with valid data";
CM_ SG_ 2483290118 BATT_modNumModsOnNetwork_6 "Number of modules on the network";
CM_ SG_ 2483290118 BATT_modNumModsOnHvBus_6 "Number of modules on the HV bus";
CM_ SG_ 2483290118 BATT_modNumModsConfigured_6 "Number of parallel modules configured for the Module";
CM_ SG_ 2483290118 BATT_ArbitrationComplete_6 "1 - Node ID Arbitration Completed (default)
0 - Node ID Arbitration Active";
CM_ SG_ 2483290118 BATT_modStateRequested_6 "Reports the requested battery state ";
CM_ SG_ 2483290118 BATT_modDataValid_6 "Module data valid";
CM_ SG_ 2483290118 BATT_prechargeState_6 "Precharge state";
CM_ SG_ 2483290118 BATT_fetPchgCommand_6 "PCHG FET commanded state";
CM_ SG_ 2483290118 BATT_fetDsgCommand_6 "DSG FETs commanded state";
CM_ SG_ 2483290118 BATT_fetChgCommand_6 "CHG FETs commanded state";
CM_ SG_ 2483290118 BATT_fetDsgStatus_6 "DSG FETs status";
CM_ SG_ 2483290118 BATT_fetChgStatus_6 "CHG FETs status";
CM_ SG_ 2483290118 BATT_timeRampdown_6 "Ramp down time";
CM_ SG_ 2483290118 BATT_inhRegen_6 "Inhibit Regen";
CM_ SG_ 2483290118 BATT_inhFullPower_6 "Inhibit Full Power";
CM_ SG_ 2483290118 BATT_inhDriveEntry_6 "Inhibit Drive Entry";
CM_ SG_ 2483290118 BATT_inhDrive_6 "Inhibit Drive";
CM_ SG_ 2483290118 BATT_inhContPower_6 "Inhibit Continuous Power";
CM_ SG_ 2483290118 BATT_inhChargeEntry_6 "Inhibit Charge Entry";
CM_ SG_ 2483290118 BATT_inhCharge_6 "Inhibit Charge";
CM_ SG_ 2483290118 BATT_modPackState_6 "Module reported pack state";
CM_ SG_ 2483290118 BATT_modPchgChargeID_6 "ID of module calculated to do pre-charge";
CM_ SG_ 2483290118 BATT_modChildState_6 "Reports the current state of the battery";
CM_ SG_ 2483290118 BATT_modPchgDriveID_6 "ID of module calculated to do pre-charge";
CM_ SG_ 2483290118 BATT_modParentState_6 "Reports the current state of the battery";
CM_ BO_ 2483290119 "Battery status";
CM_ SG_ 2483290119 BATT_modNumModsDataValid_7 "Number of parallel modules with valid data";
CM_ SG_ 2483290119 BATT_modNumModsOnNetwork_7 "Number of modules on the network";
CM_ SG_ 2483290119 BATT_modNumModsOnHvBus_7 "Number of modules on the HV bus";
CM_ SG_ 2483290119 BATT_modNumModsConfigured_7 "Number of parallel modules configured for the Module";
CM_ SG_ 2483290119 BATT_ArbitrationComplete_7 "1 - Node ID Arbitration Completed (default)
0 - Node ID Arbitration Active";
CM_ SG_ 2483290119 BATT_modStateRequested_7 "Reports the requested battery state ";
CM_ SG_ 2483290119 BATT_modDataValid_7 "Module data valid";
CM_ SG_ 2483290119 BATT_prechargeState_7 "Precharge state";
CM_ SG_ 2483290119 BATT_fetPchgCommand_7 "PCHG FET commanded state";
CM_ SG_ 2483290119 BATT_fetDsgCommand_7 "DSG FETs commanded state";
CM_ SG_ 2483290119 BATT_fetChgCommand_7 "CHG FETs commanded state";
CM_ SG_ 2483290119 BATT_fetDsgStatus_7 "DSG FETs status";
CM_ SG_ 2483290119 BATT_fetChgStatus_7 "CHG FETs status";
CM_ SG_ 2483290119 BATT_timeRampdown_7 "Ramp down time";
CM_ SG_ 2483290119 BATT_inhRegen_7 "Inhibit Regen";
CM_ SG_ 2483290119 BATT_inhFullPower_7 "Inhibit Full Power";
CM_ SG_ 2483290119 BATT_inhDriveEntry_7 "Inhibit Drive Entry";
CM_ SG_ 2483290119 BATT_inhDrive_7 "Inhibit Drive";
CM_ SG_ 2483290119 BATT_inhContPower_7 "Inhibit Continuous Power";
CM_ SG_ 2483290119 BATT_inhChargeEntry_7 "Inhibit Charge Entry";
CM_ SG_ 2483290119 BATT_inhCharge_7 "Inhibit Charge";
CM_ SG_ 2483290119 BATT_modPackState_7 "Module reported pack state";
CM_ SG_ 2483290119 BATT_modPchgChargeID_7 "ID of module calculated to do pre-charge";
CM_ SG_ 2483290119 BATT_modChildState_7 "Reports the current state of the battery";
CM_ SG_ 2483290119 BATT_modPchgDriveID_7 "ID of module calculated to do pre-charge";
CM_ SG_ 2483290119 BATT_modParentState_7 "Reports the current state of the battery";
CM_ SG_ 2487484416 BATT_boardIO_DIS_OC_FLT_LA_0 "DIS_OC_FLT_LA input signal status";
CM_ SG_ 2487484416 BATT_boardIO_L9963_FAULT_0 "L9963_FAULT input signal status";
CM_ SG_ 2487484416 BATT_boardIO_IL_WAKE_LATCH_0 "IL_WAKE_LATCH input signal status";
CM_ SG_ 2487484416 BATT_boardIO_IH_WAKE_LATCH_0 "IH_WAKE_LATCH input signal status";
CM_ SG_ 2487484416 BATT_boardIO_CAN_WAKE_LATCH_0 "CAN_WAKE_LATCH input signal status";
CM_ SG_ 2487484417 BATT_boardIO_DIS_OC_FLT_LA_1 "DIS_OC_FLT_LA input signal status";
CM_ SG_ 2487484417 BATT_boardIO_L9963_FAULT_1 "L9963_FAULT input signal status";
CM_ SG_ 2487484417 BATT_boardIO_IL_WAKE_LATCH_1 "IL_WAKE_LATCH input signal status";
CM_ SG_ 2487484417 BATT_boardIO_IH_WAKE_LATCH_1 "IH_WAKE_LATCH input signal status";
CM_ SG_ 2487484417 BATT_boardIO_CAN_WAKE_LATCH_1 "CAN_WAKE_LATCH input signal status";
CM_ SG_ 2487484418 BATT_boardIO_DIS_OC_FLT_LA_2 "DIS_OC_FLT_LA input signal status";
CM_ SG_ 2487484418 BATT_boardIO_L9963_FAULT_2 "L9963_FAULT input signal status";
CM_ SG_ 2487484418 BATT_boardIO_IL_WAKE_LATCH_2 "IL_WAKE_LATCH input signal status";
CM_ SG_ 2487484418 BATT_boardIO_IH_WAKE_LATCH_2 "IH_WAKE_LATCH input signal status";
CM_ SG_ 2487484418 BATT_boardIO_CAN_WAKE_LATCH_2 "CAN_WAKE_LATCH input signal status";
CM_ SG_ 2487484419 BATT_boardIO_DIS_OC_FLT_LA_3 "DIS_OC_FLT_LA input signal status";
CM_ SG_ 2487484419 BATT_boardIO_L9963_FAULT_3 "L9963_FAULT input signal status";
CM_ SG_ 2487484419 BATT_boardIO_IL_WAKE_LATCH_3 "IL_WAKE_LATCH input signal status";
CM_ SG_ 2487484419 BATT_boardIO_IH_WAKE_LATCH_3 "IH_WAKE_LATCH input signal status";
CM_ SG_ 2487484419 BATT_boardIO_CAN_WAKE_LATCH_3 "CAN_WAKE_LATCH input signal status";
CM_ SG_ 2487484420 BATT_boardIO_DIS_OC_FLT_LA_4 "DIS_OC_FLT_LA input signal status";
CM_ SG_ 2487484420 BATT_boardIO_L9963_FAULT_4 "L9963_FAULT input signal status";
CM_ SG_ 2487484420 BATT_boardIO_IL_WAKE_LATCH_4 "IL_WAKE_LATCH input signal status";
CM_ SG_ 2487484420 BATT_boardIO_IH_WAKE_LATCH_4 "IH_WAKE_LATCH input signal status";
CM_ SG_ 2487484420 BATT_boardIO_CAN_WAKE_LATCH_4 "CAN_WAKE_LATCH input signal status";
CM_ SG_ 2487484421 BATT_boardIO_DIS_OC_FLT_LA_5 "DIS_OC_FLT_LA input signal status";
CM_ SG_ 2487484421 BATT_boardIO_L9963_FAULT_5 "L9963_FAULT input signal status";
CM_ SG_ 2487484421 BATT_boardIO_IL_WAKE_LATCH_5 "IL_WAKE_LATCH input signal status";
CM_ SG_ 2487484421 BATT_boardIO_IH_WAKE_LATCH_5 "IH_WAKE_LATCH input signal status";
CM_ SG_ 2487484421 BATT_boardIO_CAN_WAKE_LATCH_5 "CAN_WAKE_LATCH input signal status";
CM_ SG_ 2487484422 BATT_boardIO_DIS_OC_FLT_LA_6 "DIS_OC_FLT_LA input signal status";
CM_ SG_ 2487484422 BATT_boardIO_L9963_FAULT_6 "L9963_FAULT input signal status";
CM_ SG_ 2487484422 BATT_boardIO_IL_WAKE_LATCH_6 "IL_WAKE_LATCH input signal status";
CM_ SG_ 2487484422 BATT_boardIO_IH_WAKE_LATCH_6 "IH_WAKE_LATCH input signal status";
CM_ SG_ 2487484422 BATT_boardIO_CAN_WAKE_LATCH_6 "CAN_WAKE_LATCH input signal status";
CM_ SG_ 2487484423 BATT_boardIO_DIS_OC_FLT_LA_7 "DIS_OC_FLT_LA input signal status";
CM_ SG_ 2487484423 BATT_boardIO_L9963_FAULT_7 "L9963_FAULT input signal status";
CM_ SG_ 2487484423 BATT_boardIO_IL_WAKE_LATCH_7 "IL_WAKE_LATCH input signal status";
CM_ SG_ 2487484423 BATT_boardIO_IH_WAKE_LATCH_7 "IH_WAKE_LATCH input signal status";
CM_ SG_ 2487484423 BATT_boardIO_CAN_WAKE_LATCH_7 "CAN_WAKE_LATCH input signal status";
CM_ BO_ 2508193792 "Bootloader and BMS application firmware versions";
CM_ SG_ 2508193792 BATT_bootloaderRevision_bootup_0 "Revision bootloader version for BMS";
CM_ SG_ 2508193792 BATT_bootloaderMinor_bootup_0 "Minor bootloader version for BMS";
CM_ SG_ 2508193792 BATT_bootloaderMajor_bootup_0 "Major bootloader version for BMS";
CM_ SG_ 2508193792 BATT_appRevision_bootup_0 "Revision app version for BMS";
CM_ SG_ 2508193792 BATT_appMinor_bootup_0 "Minor app version for BMS";
CM_ SG_ 2508193792 BATT_appMajor_bootup_0 "Major app version for BMS";
CM_ BO_ 2508193793 "Bootloader and BMS application firmware versions";
CM_ SG_ 2508193793 BATT_bootloaderRevision_bootup_1 "Revision bootloader version for BMS";
CM_ SG_ 2508193793 BATT_bootloaderMinor_bootup_1 "Minor bootloader version for BMS";
CM_ SG_ 2508193793 BATT_bootloaderMajor_bootup_1 "Major bootloader version for BMS";
CM_ SG_ 2508193793 BATT_appRevision_bootup_1 "Revision app version for BMS";
CM_ SG_ 2508193793 BATT_appMinor_bootup_1 "Minor app version for BMS";
CM_ SG_ 2508193793 BATT_appMajor_bootup_1 "Major app version for BMS";
CM_ BO_ 2508193794 "Bootloader and BMS application firmware versions";
CM_ SG_ 2508193794 BATT_bootloaderRevision_bootup_2 "Revision bootloader version for BMS";
CM_ SG_ 2508193794 BATT_bootloaderMinor_bootup_2 "Minor bootloader version for BMS";
CM_ SG_ 2508193794 BATT_bootloaderMajor_bootup_2 "Major bootloader version for BMS";
CM_ SG_ 2508193794 BATT_appRevision_bootup_2 "Revision app version for BMS";
CM_ SG_ 2508193794 BATT_appMinor_bootup_2 "Minor app version for BMS";
CM_ SG_ 2508193794 BATT_appMajor_bootup_2 "Major app version for BMS";
CM_ BO_ 2508193795 "Bootloader and BMS application firmware versions";
CM_ SG_ 2508193795 BATT_bootloaderRevision_bootup_3 "Revision bootloader version for BMS";
CM_ SG_ 2508193795 BATT_bootloaderMinor_bootup_3 "Minor bootloader version for BMS";
CM_ SG_ 2508193795 BATT_bootloaderMajor_bootup_3 "Major bootloader version for BMS";
CM_ SG_ 2508193795 BATT_appRevision_bootup_3 "Revision app version for BMS";
CM_ SG_ 2508193795 BATT_appMinor_bootup_3 "Minor app version for BMS";
CM_ SG_ 2508193795 BATT_appMajor_bootup_3 "Major app version for BMS";
CM_ BO_ 2508193796 "Bootloader and BMS application firmware versions";
CM_ SG_ 2508193796 BATT_bootloaderRevision_bootup_4 "Revision bootloader version for BMS";
CM_ SG_ 2508193796 BATT_bootloaderMinor_bootup_4 "Minor bootloader version for BMS";
CM_ SG_ 2508193796 BATT_bootloaderMajor_bootup_4 "Major bootloader version for BMS";
CM_ SG_ 2508193796 BATT_appRevision_bootup_4 "Revision app version for BMS";
CM_ SG_ 2508193796 BATT_appMinor_bootup_4 "Minor app version for BMS";
CM_ SG_ 2508193796 BATT_appMajor_bootup_4 "Major app version for BMS";
CM_ BO_ 2508193797 "Bootloader and BMS application firmware versions";
CM_ SG_ 2508193797 BATT_bootloaderRevision_bootup_5 "Revision bootloader version for BMS";
CM_ SG_ 2508193797 BATT_bootloaderMinor_bootup_5 "Minor bootloader version for BMS";
CM_ SG_ 2508193797 BATT_bootloaderMajor_bootup_5 "Major bootloader version for BMS";
CM_ SG_ 2508193797 BATT_appRevision_bootup_5 "Revision app version for BMS";
CM_ SG_ 2508193797 BATT_appMinor_bootup_5 "Minor app version for BMS";
CM_ SG_ 2508193797 BATT_appMajor_bootup_5 "Major app version for BMS";
CM_ BO_ 2508193798 "Bootloader and BMS application firmware versions";
CM_ SG_ 2508193798 BATT_bootloaderRevision_bootup_6 "Revision bootloader version for BMS";
CM_ SG_ 2508193798 BATT_bootloaderMinor_bootup_6 "Minor bootloader version for BMS";
CM_ SG_ 2508193798 BATT_bootloaderMajor_bootup_6 "Major bootloader version for BMS";
CM_ SG_ 2508193798 BATT_appRevision_bootup_6 "Revision app version for BMS";
CM_ SG_ 2508193798 BATT_appMinor_bootup_6 "Minor app version for BMS";
CM_ SG_ 2508193798 BATT_appMajor_bootup_6 "Major app version for BMS";
CM_ BO_ 2508193799 "Bootloader and BMS application firmware versions";
CM_ SG_ 2508193799 BATT_bootloaderRevision_bootup_7 "Revision bootloader version for BMS";
CM_ SG_ 2508193799 BATT_bootloaderMinor_bootup_7 "Minor bootloader version for BMS";
CM_ SG_ 2508193799 BATT_bootloaderMajor_bootup_7 "Major bootloader version for BMS";
CM_ SG_ 2508193799 BATT_appRevision_bootup_7 "Revision app version for BMS";
CM_ SG_ 2508193799 BATT_appMinor_bootup_7 "Minor app version for BMS";
CM_ SG_ 2508193799 BATT_appMajor_bootup_7 "Major app version for BMS";
CM_ SG_ 2550398976 BATT_manufacturerName_0 "Manufacturer name string. Length prefixed strings will work for strict SMBus and SPI, how to handle for CAN?";
CM_ SG_ 2550398976 BATT_manufacturerAccess_0 "Content determined by the Smart Battery's manufacturer";
CM_ SG_ 2550398976 BATT_manufactureYear_0 "Manufacture year biased by 1980";
CM_ SG_ 2550398976 BATT_manufactureMonth_0 "Manufacture month";
CM_ SG_ 2550398976 BATT_manufactureDay_0 "Manufacture day";
CM_ SG_ 2550398977 BATT_manufacturerName_1 "Manufacturer name string. Length prefixed strings will work for strict SMBus and SPI, how to handle for CAN?";
CM_ SG_ 2550398977 BATT_manufacturerAccess_1 "Content determined by the Smart Battery's manufacturer";
CM_ SG_ 2550398977 BATT_manufactureYear_1 "Manufacture year biased by 1980";
CM_ SG_ 2550398977 BATT_manufactureMonth_1 "Manufacture month";
CM_ SG_ 2550398977 BATT_manufactureDay_1 "Manufacture day";
CM_ SG_ 2550398978 BATT_manufacturerName_2 "Manufacturer name string. Length prefixed strings will work for strict SMBus and SPI, how to handle for CAN?";
CM_ SG_ 2550398978 BATT_manufacturerAccess_2 "Content determined by the Smart Battery's manufacturer";
CM_ SG_ 2550398978 BATT_manufactureYear_2 "Manufacture year biased by 1980";
CM_ SG_ 2550398978 BATT_manufactureMonth_2 "Manufacture month";
CM_ SG_ 2550398978 BATT_manufactureDay_2 "Manufacture day";
CM_ SG_ 2550398979 BATT_manufacturerName_3 "Manufacturer name string. Length prefixed strings will work for strict SMBus and SPI, how to handle for CAN?";
CM_ SG_ 2550398979 BATT_manufacturerAccess_3 "Content determined by the Smart Battery's manufacturer";
CM_ SG_ 2550398979 BATT_manufactureYear_3 "Manufacture year biased by 1980";
CM_ SG_ 2550398979 BATT_manufactureMonth_3 "Manufacture month";
CM_ SG_ 2550398979 BATT_manufactureDay_3 "Manufacture day";
CM_ SG_ 2550398980 BATT_manufacturerName_4 "Manufacturer name string. Length prefixed strings will work for strict SMBus and SPI, how to handle for CAN?";
CM_ SG_ 2550398980 BATT_manufacturerAccess_4 "Content determined by the Smart Battery's manufacturer";
CM_ SG_ 2550398980 BATT_manufactureYear_4 "Manufacture year biased by 1980";
CM_ SG_ 2550398980 BATT_manufactureMonth_4 "Manufacture month";
CM_ SG_ 2550398980 BATT_manufactureDay_4 "Manufacture day";
CM_ SG_ 2550398981 BATT_manufacturerName_5 "Manufacturer name string. Length prefixed strings will work for strict SMBus and SPI, how to handle for CAN?";
CM_ SG_ 2550398981 BATT_manufacturerAccess_5 "Content determined by the Smart Battery's manufacturer";
CM_ SG_ 2550398981 BATT_manufactureYear_5 "Manufacture year biased by 1980";
CM_ SG_ 2550398981 BATT_manufactureMonth_5 "Manufacture month";
CM_ SG_ 2550398981 BATT_manufactureDay_5 "Manufacture day";
CM_ SG_ 2550398982 BATT_manufacturerName_6 "Manufacturer name string. Length prefixed strings will work for strict SMBus and SPI, how to handle for CAN?";
CM_ SG_ 2550398982 BATT_manufacturerAccess_6 "Content determined by the Smart Battery's manufacturer";
CM_ SG_ 2550398982 BATT_manufactureYear_6 "Manufacture year biased by 1980";
CM_ SG_ 2550398982 BATT_manufactureMonth_6 "Manufacture month";
CM_ SG_ 2550398982 BATT_manufactureDay_6 "Manufacture day";
CM_ SG_ 2550398983 BATT_manufacturerName_7 "Manufacturer name string. Length prefixed strings will work for strict SMBus and SPI, how to handle for CAN?";
CM_ SG_ 2550398983 BATT_manufacturerAccess_7 "Content determined by the Smart Battery's manufacturer";
CM_ SG_ 2550398983 BATT_manufactureYear_7 "Manufacture year biased by 1980";
CM_ SG_ 2550398983 BATT_manufactureMonth_7 "Manufacture month";
CM_ SG_ 2550398983 BATT_manufactureDay_7 "Manufacture day";
CM_ SG_ 2550661120 BATT_IGNLO_Status_0 "0 - Unkown
1 - Standby
2 - Drive
3 - Arbitration
";
CM_ SG_ 2550661120 BATT_serialNumber_0 "Unique serial number";
CM_ SG_ 2550661120 BATT_expectedModule_0 "Expected number of modules";
CM_ SG_ 2550661120 BATT_deviceChemistry_0 "Device chemistry.  Note strict SMBus handles this with a character string";
CM_ SG_ 2550661121 BATT_IGNLO_Status_1 "0 - Unkown
1 - Standby
2 - Drive
3 - Arbitration
";
CM_ SG_ 2550661121 BATT_serialNumber_1 "Unique serial number";
CM_ SG_ 2550661121 BATT_expectedModule_1 "Expected number of modules";
CM_ SG_ 2550661121 BATT_deviceChemistry_1 "Device chemistry.  Note strict SMBus handles this with a character string";
CM_ SG_ 2550661122 BATT_IGNLO_Status_2 "0 - Unkown
1 - Standby
2 - Drive
3 - Arbitration
";
CM_ SG_ 2550661122 BATT_serialNumber_2 "Unique serial number";
CM_ SG_ 2550661122 BATT_expectedModule_2 "Expected number of modules";
CM_ SG_ 2550661122 BATT_deviceChemistry_2 "Device chemistry.  Note strict SMBus handles this with a character string";
CM_ SG_ 2550661123 BATT_IGNLO_Status_3 "0 - Unkown
1 - Standby
2 - Drive
3 - Arbitration
";
CM_ SG_ 2550661123 BATT_serialNumber_3 "Unique serial number";
CM_ SG_ 2550661123 BATT_expectedModule_3 "Expected number of modules";
CM_ SG_ 2550661123 BATT_deviceChemistry_3 "Device chemistry.  Note strict SMBus handles this with a character string";
CM_ SG_ 2550661124 BATT_IGNLO_Status_4 "0 - Unkown
1 - Standby
2 - Drive
3 - Arbitration
";
CM_ SG_ 2550661124 BATT_serialNumber_4 "Unique serial number";
CM_ SG_ 2550661124 BATT_expectedModule_4 "Expected number of modules";
CM_ SG_ 2550661124 BATT_deviceChemistry_4 "Device chemistry.  Note strict SMBus handles this with a character string";
CM_ SG_ 2550661125 BATT_IGNLO_Status_5 "0 - Unkown
1 - Standby
2 - Drive
3 - Arbitration
";
CM_ SG_ 2550661125 BATT_serialNumber_5 "Unique serial number";
CM_ SG_ 2550661125 BATT_expectedModule_5 "Expected number of modules";
CM_ SG_ 2550661125 BATT_deviceChemistry_5 "Device chemistry.  Note strict SMBus handles this with a character string";
CM_ SG_ 2550661126 BATT_IGNLO_Status_6 "0 - Unkown
1 - Standby
2 - Drive
3 - Arbitration
";
CM_ SG_ 2550661126 BATT_serialNumber_6 "Unique serial number";
CM_ SG_ 2550661126 BATT_expectedModule_6 "Expected number of modules";
CM_ SG_ 2550661126 BATT_deviceChemistry_6 "Device chemistry.  Note strict SMBus handles this with a character string";
CM_ SG_ 2550661127 BATT_IGNLO_Status_7 "0 - Unkown
1 - Standby
2 - Drive
3 - Arbitration
";
CM_ SG_ 2550661127 BATT_serialNumber_7 "Unique serial number";
CM_ SG_ 2550661127 BATT_expectedModule_7 "Expected number of modules";
CM_ SG_ 2550661127 BATT_deviceChemistry_7 "Device chemistry.  Note strict SMBus handles this with a character string";
CM_ BO_ 2571108352 "Message with flags from event matrix";
CM_ SG_ 2571108352 BATT_packModIdFault_0 "0 - Battery pack module ID okay (default)
1 - Battery pack module ID fault";
CM_ SG_ 2571108352 BATT_packModExitedFromBus_0 "0 - Battery pack modules OK (default)
1 - Battery pack module(s) exited from the bus during charge or drive";
CM_ SG_ 2571108352 BATT_packFetChgWelded_0 "0 - Battery pack module CHG FETs not welded (default)
1 - Battery pack module CHG FETs welded ";
CM_ SG_ 2571108352 BATT_packFetDsgWelded_0 "0 - Battery pack module DSG FETs not welded (default)
1 - Battery pack module DSG FETs welded ";
CM_ SG_ 2571108352 BATT_fetDsgShortedAux_0 "0 - FETs are operational (default)
1 - FET is shorted detected by auxiliary diagnostic";
CM_ SG_ 2571108352 BATT_fetChgShortedAux_0 "0 - FETs are operational (default)
1 - FET is shorted detected by auxiliary diagnostic";
CM_ SG_ 2571108352 BATT_prechargeFetFail_0 "0 - Precharge FET okay (default)
1 - Precharge FET failed";
CM_ SG_ 2571108352 BATT_abnormalResetReason_0 "0 - Reset reason okay (default)
1 - Abnormal reset reason";
CM_ SG_ 2571108352 BATT_prechargeTooSlow_0 "0 - Precharge okay (default)
1 - Precharge too slow";
CM_ SG_ 2571108352 BATT_prechargeTooFast_0 "0 - Precharge okay (default)
1 - Precharge too fast";
CM_ SG_ 2571108352 BATT_prechargeTimeout_0 "0 - Precharge okay (default)
1 - Precharge timeout";
CM_ SG_ 2571108352 BATT_fetChgShorted_0 "0 - FETs are operational (default)
1 - FET is shorted";
CM_ SG_ 2571108352 BATT_fetChgFailToClose_0 "0 - FETs are operational (default)
1 -  FET fail to close";
CM_ SG_ 2571108352 BATT_packModSelectFault_0 "0 - Battery pack module selection okay (default)
1 - Battery pack module selection fault";
CM_ SG_ 2571108352 BATT_packModConnectFault_0 "0 - Battery pack module connection okay (default)
1 - Battery pack module connection fault";
CM_ SG_ 2571108352 BATT_packModMIA_0 "0 - Battery pack modules not MIA (default)
1 - Battery pack module MIA";
CM_ SG_ 2571108352 BATT_packModImbalance_0 "0 - Battery pack modules balanced (default)
1 - Battery pack module imblance present";
CM_ SG_ 2571108352 BATT_afeFault_0 "0 - BMS AFE okay (default)
1 - BMS AFE fault";
CM_ SG_ 2571108352 BATT_chargerMIA_0 "0 - Charger communications okay (default)
1 - Charger MIA";
CM_ SG_ 2571108352 BATT_chargerError_0 "0 - Charger working as intended (default)
1 - Charger error";
CM_ SG_ 2571108352 BATT_vBrickUnderWar_0 "0 - Brick voltage okay (default)
1 - Brick undervoltage warning";
CM_ SG_ 2571108352 BATT_vBrickUnderSev_0 "0 - Brick voltage okay (default)
1 - Brick undervoltage severe";
CM_ SG_ 2571108352 BATT_vBrickUnderMod_0 "0 - Brick voltage okay (default)
1 - Brick undervoltage moderate";
CM_ SG_ 2571108352 BATT_vBrickOverWar_0 "0 - Brick voltage okay (default)
1 - Brick overvoltage warning";
CM_ SG_ 2571108352 BATT_vBrickOverSev_0 "0 - Brick voltage okay (default)
1 - Brick overvoltage severe";
CM_ SG_ 2571108352 BATT_vBrickOverMod_0 "0 - Brick voltage okay (default)
1 - Brick overvoltage moderate";
CM_ SG_ 2571108352 BATT_vBrickImbalance_0 "0 - Battery brick voltage okay (default)
1 - Battery brick voltage imbalance";
CM_ SG_ 2571108352 BATT_loggerAlmostFull_0 "0 - Logger not almost full (default)
1 - Logger almost full (section >= 80%) ";
CM_ SG_ 2571108352 BATT_tempModuleUnderWar_0 "0 - Battery temperature okay (default)
1 - Battery under temperature warning";
CM_ SG_ 2571108352 BATT_tempModuleUnderSev_0 "0 - Battery temperature okay (default)
1 - Battery under temperature severe";
CM_ SG_ 2571108352 BATT_tempModuleUnderMod_0 "0 - Battery temperature okay (default)
1 - Battery under temperature moderate";
CM_ SG_ 2571108352 BATT_tempModuleOverWar_0 "0 - Battery temperature okay (default)
1 - Battery over temperature warning";
CM_ SG_ 2571108352 BATT_tempModuleOverSev_0 "0 - Battery temperature okay (default)
1 - Battery over temperature severe";
CM_ SG_ 2571108352 BATT_tempModuleOverMod_0 "0 - Battery temperature okay (default)
1 - Battery over temperature moderate";
CM_ SG_ 2571108352 BATT_tempBrickImbalance_0 "0 - Brick temperatures are balanced (default)
1 - Brick temperatures are imbalanced";
CM_ SG_ 2571108352 BATT_taskLockupError_0 "0 - Tasks okay (default)
1 - Task lockup error";
CM_ SG_ 2571108352 BATT_tempAmbientOverWar_0 "0 - Ambient temperature okay (default)
1 - Ambient over temperature warning";
CM_ SG_ 2571108352 BATT_tempAmbientOverSev_0 "0 - Temperature okay (default)
1 - Ambient over temperature severe";
CM_ SG_ 2571108352 BATT_tempAmbientOverMod_0 "0 - Ambient temperature okay (default)
1 - Ambient over temparature moderate";
CM_ SG_ 2571108352 BATT_sensePackVoltError_0 "0 - Sensor okay (default)
1 - Sensor for pack voltage error";
CM_ SG_ 2571108352 BATT_senseLoadVoltError_0 "0 - Sensor okay (default)
1 - Sensor for load voltage error";
CM_ SG_ 2571108352 BATT_loggerFull_0 "0 - Logger not full (default)
1 - Logger full ";
CM_ SG_ 2571108352 BATT_senseCurrentError_0 "0 - Sensor okay (default)
1 - Sensor for current error";
CM_ SG_ 2571108352 BATT_senseBrickTempError_0 "0 - Sensor okay (default)
1 - Brick temperature sensor error";
CM_ SG_ 2571108352 BATT_resPackHigh_0 "0 - Battery pack resistance okay (default)
1 - Battery pack resistance high (High SOH-R)";
CM_ SG_ 2571108352 BATT_ramOverUtilError_0 "0 - RAM okay (default)
1 - RAM over utilization";
CM_ SG_ 2571108352 BATT_powerPackInsufficient_0 "0 - Battery pack power okay (default)
1 - Battery pack power insufficient";
CM_ SG_ 2571108352 BATT_packCellSoftShort_0 "0 - Battery back cells are okay (default)
1 - Battery pack cell soft short";
CM_ SG_ 2571108352 BATT_iOverHardware_0 "0 - Hardware current okay (default)
1 - Overcurrent in hardware";
CM_ SG_ 2571108352 BATT_fetOverTemp_0 "0 - FET temperature okay (default)
1 - Overtemp at FETs";
CM_ SG_ 2571108352 BATT_iOverDischarge_0 "0 - Discharge okay (default)
1 - Overcurrent during discharge";
CM_ SG_ 2571108352 BATT_iOverCharge_0 "0 - Charging okay (default)
1 - Overcurrent during charging";
CM_ SG_ 2571108352 BATT_inverterDriveMIA_0 "0 - Inverter drive present (default)
1 - Inverter drive MIA";
CM_ SG_ 2571108352 BATT_iUnderCharge_0 "0 - Normal charging (default)
1 -  Charging undercurrent (discharging)";
CM_ SG_ 2571108352 BATT_hostMIA_0 "0 - host communication open (default)
1 - host MIA";
CM_ SG_ 2571108352 BATT_fetDsgShorted_0 "0 - FETs are operational (default)
1 - FET is shorted";
CM_ SG_ 2571108352 BATT_fetDsgFailToClose_0 "0 - FETs are operational (default)
1 -  FET fail to close";
CM_ SG_ 2571108352 BATT_capLow_0 "0 - Battery capacity normal (SOH-C) (default)
1 - Low battery capacity (Low SOH-C)";
CM_ SG_ 2571108352 BATT_brickOverDischarge_0 "0 - Battery brick charge is normal (default)
1 - Battery brick is overdischarged";
CM_ SG_ 2571108352 BATT_brickOverCharge_0 "0 - Battery brick charge is normal (default)
1 - Battery brick is overcharged";
CM_ SG_ 2571108352 BATT_bmsProcessorError_0 "0 - No BMS processor failure (default)
1 - BMS processor failure";
CM_ SG_ 2571108352 BATT_bmsMemoryError_0 "0 - No BMS memory error
1 - BMS memory error";
CM_ SG_ 2571108352 BATT_afeError_0 "0 - No BMS AFE error (default)
1 - BMS AFE error";
CM_ BO_ 2571108353 "Message with flags from event matrix";
CM_ SG_ 2571108353 BATT_packModIdFault_1 "0 - Battery pack module ID okay (default)
1 - Battery pack module ID fault";
CM_ SG_ 2571108353 BATT_packModExitedFromBus_1 "0 - Battery pack modules OK (default)
1 - Battery pack module(s) exited from the bus during charge or drive";
CM_ SG_ 2571108353 BATT_packFetChgWelded_1 "0 - Battery pack module CHG FETs not welded (default)
1 - Battery pack module CHG FETs welded ";
CM_ SG_ 2571108353 BATT_packFetDsgWelded_1 "0 - Battery pack module DSG FETs not welded (default)
1 - Battery pack module DSG FETs welded ";
CM_ SG_ 2571108353 BATT_fetDsgShortedAux_1 "0 - FETs are operational (default)
1 - FET is shorted detected by auxiliary diagnostic";
CM_ SG_ 2571108353 BATT_fetChgShortedAux_1 "0 - FETs are operational (default)
1 - FET is shorted detected by auxiliary diagnostic";
CM_ SG_ 2571108353 BATT_prechargeFetFail_1 "0 - Precharge FET okay (default)
1 - Precharge FET failed";
CM_ SG_ 2571108353 BATT_abnormalResetReason_1 "0 - Reset reason okay (default)
1 - Abnormal reset reason";
CM_ SG_ 2571108353 BATT_prechargeTooSlow_1 "0 - Precharge okay (default)
1 - Precharge too slow";
CM_ SG_ 2571108353 BATT_prechargeTooFast_1 "0 - Precharge okay (default)
1 - Precharge too fast";
CM_ SG_ 2571108353 BATT_prechargeTimeout_1 "0 - Precharge okay (default)
1 - Precharge timeout";
CM_ SG_ 2571108353 BATT_fetChgShorted_1 "0 - FETs are operational (default)
1 - FET is shorted";
CM_ SG_ 2571108353 BATT_fetChgFailToClose_1 "0 - FETs are operational (default)
1 -  FET fail to close";
CM_ SG_ 2571108353 BATT_packModSelectFault_1 "0 - Battery pack module selection okay (default)
1 - Battery pack module selection fault";
CM_ SG_ 2571108353 BATT_packModConnectFault_1 "0 - Battery pack module connection okay (default)
1 - Battery pack module connection fault";
CM_ SG_ 2571108353 BATT_packModMIA_1 "0 - Battery pack modules not MIA (default)
1 - Battery pack module MIA";
CM_ SG_ 2571108353 BATT_packModImbalance_1 "0 - Battery pack modules balanced (default)
1 - Battery pack module imblance present";
CM_ SG_ 2571108353 BATT_afeFault_1 "0 - BMS AFE okay (default)
1 - BMS AFE fault";
CM_ SG_ 2571108353 BATT_chargerMIA_1 "0 - Charger communications okay (default)
1 - Charger MIA";
CM_ SG_ 2571108353 BATT_chargerError_1 "0 - Charger working as intended (default)
1 - Charger error";
CM_ SG_ 2571108353 BATT_vBrickUnderWar_1 "0 - Brick voltage okay (default)
1 - Brick undervoltage warning";
CM_ SG_ 2571108353 BATT_vBrickUnderSev_1 "0 - Brick voltage okay (default)
1 - Brick undervoltage severe";
CM_ SG_ 2571108353 BATT_vBrickUnderMod_1 "0 - Brick voltage okay (default)
1 - Brick undervoltage moderate";
CM_ SG_ 2571108353 BATT_vBrickOverWar_1 "0 - Brick voltage okay (default)
1 - Brick overvoltage warning";
CM_ SG_ 2571108353 BATT_vBrickOverSev_1 "0 - Brick voltage okay (default)
1 - Brick overvoltage severe";
CM_ SG_ 2571108353 BATT_vBrickOverMod_1 "0 - Brick voltage okay (default)
1 - Brick overvoltage moderate";
CM_ SG_ 2571108353 BATT_vBrickImbalance_1 "0 - Battery brick voltage okay (default)
1 - Battery brick voltage imbalance";
CM_ SG_ 2571108353 BATT_loggerAlmostFull_1 "0 - Logger not almost full (default)
1 - Logger almost full (section >= 80%) ";
CM_ SG_ 2571108353 BATT_tempModuleUnderWar_1 "0 - Battery temperature okay (default)
1 - Battery under temperature warning";
CM_ SG_ 2571108353 BATT_tempModuleUnderSev_1 "0 - Battery temperature okay (default)
1 - Battery under temperature severe";
CM_ SG_ 2571108353 BATT_tempModuleUnderMod_1 "0 - Battery temperature okay (default)
1 - Battery under temperature moderate";
CM_ SG_ 2571108353 BATT_tempModuleOverWar_1 "0 - Battery temperature okay (default)
1 - Battery over temperature warning";
CM_ SG_ 2571108353 BATT_tempModuleOverSev_1 "0 - Battery temperature okay (default)
1 - Battery over temperature severe";
CM_ SG_ 2571108353 BATT_tempModuleOverMod_1 "0 - Battery temperature okay (default)
1 - Battery over temperature moderate";
CM_ SG_ 2571108353 BATT_tempBrickImbalance_1 "0 - Brick temperatures are balanced (default)
1 - Brick temperatures are imbalanced";
CM_ SG_ 2571108353 BATT_taskLockupError_1 "0 - Tasks okay (default)
1 - Task lockup error";
CM_ SG_ 2571108353 BATT_tempAmbientOverWar_1 "0 - Ambient temperature okay (default)
1 - Ambient over temperature warning";
CM_ SG_ 2571108353 BATT_tempAmbientOverSev_1 "0 - Temperature okay (default)
1 - Ambient over temperature severe";
CM_ SG_ 2571108353 BATT_tempAmbientOverMod_1 "0 - Ambient temperature okay (default)
1 - Ambient over temparature moderate";
CM_ SG_ 2571108353 BATT_sensePackVoltError_1 "0 - Sensor okay (default)
1 - Sensor for pack voltage error";
CM_ SG_ 2571108353 BATT_senseLoadVoltError_1 "0 - Sensor okay (default)
1 - Sensor for load voltage error";
CM_ SG_ 2571108353 BATT_loggerFull_1 "0 - Logger not full (default)
1 - Logger full ";
CM_ SG_ 2571108353 BATT_senseCurrentError_1 "0 - Sensor okay (default)
1 - Sensor for current error";
CM_ SG_ 2571108353 BATT_senseBrickTempError_1 "0 - Sensor okay (default)
1 - Brick temperature sensor error";
CM_ SG_ 2571108353 BATT_resPackHigh_1 "0 - Battery pack resistance okay (default)
1 - Battery pack resistance high (High SOH-R)";
CM_ SG_ 2571108353 BATT_ramOverUtilError_1 "0 - RAM okay (default)
1 - RAM over utilization";
CM_ SG_ 2571108353 BATT_powerPackInsufficient_1 "0 - Battery pack power okay (default)
1 - Battery pack power insufficient";
CM_ SG_ 2571108353 BATT_packCellSoftShort_1 "0 - Battery back cells are okay (default)
1 - Battery pack cell soft short";
CM_ SG_ 2571108353 BATT_iOverHardware_1 "0 - Hardware current okay (default)
1 - Overcurrent in hardware";
CM_ SG_ 2571108353 BATT_fetOverTemp_1 "0 - FET temperature okay (default)
1 - Overtemp at FETs";
CM_ SG_ 2571108353 BATT_iOverDischarge_1 "0 - Discharge okay (default)
1 - Overcurrent during discharge";
CM_ SG_ 2571108353 BATT_iOverCharge_1 "0 - Charging okay (default)
1 - Overcurrent during charging";
CM_ SG_ 2571108353 BATT_inverterDriveMIA_1 "0 - Inverter drive present (default)
1 - Inverter drive MIA";
CM_ SG_ 2571108353 BATT_iUnderCharge_1 "0 - Normal charging (default)
1 -  Charging undercurrent (discharging)";
CM_ SG_ 2571108353 BATT_hostMIA_1 "0 - host communication open (default)
1 - host MIA";
CM_ SG_ 2571108353 BATT_fetDsgShorted_1 "0 - FETs are operational (default)
1 - FET is shorted";
CM_ SG_ 2571108353 BATT_fetDsgFailToClose_1 "0 - FETs are operational (default)
1 -  FET fail to close";
CM_ SG_ 2571108353 BATT_capLow_1 "0 - Battery capacity normal (SOH-C) (default)
1 - Low battery capacity (Low SOH-C)";
CM_ SG_ 2571108353 BATT_brickOverDischarge_1 "0 - Battery brick charge is normal (default)
1 - Battery brick is overdischarged";
CM_ SG_ 2571108353 BATT_brickOverCharge_1 "0 - Battery brick charge is normal (default)
1 - Battery brick is overcharged";
CM_ SG_ 2571108353 BATT_bmsProcessorError_1 "0 - No BMS processor failure (default)
1 - BMS processor failure";
CM_ SG_ 2571108353 BATT_bmsMemoryError_1 "0 - No BMS memory error
1 - BMS memory error";
CM_ SG_ 2571108353 BATT_afeError_1 "0 - No BMS AFE error (default)
1 - BMS AFE error";
CM_ BO_ 2571108354 "Message with flags from event matrix";
CM_ SG_ 2571108354 BATT_packModIdFault_2 "0 - Battery pack module ID okay (default)
1 - Battery pack module ID fault";
CM_ SG_ 2571108354 BATT_packModExitedFromBus_2 "0 - Battery pack modules OK (default)
1 - Battery pack module(s) exited from the bus during charge or drive";
CM_ SG_ 2571108354 BATT_packFetChgWelded_2 "0 - Battery pack module CHG FETs not welded (default)
1 - Battery pack module CHG FETs welded ";
CM_ SG_ 2571108354 BATT_packFetDsgWelded_2 "0 - Battery pack module DSG FETs not welded (default)
1 - Battery pack module DSG FETs welded ";
CM_ SG_ 2571108354 BATT_fetDsgShortedAux_2 "0 - FETs are operational (default)
1 - FET is shorted detected by auxiliary diagnostic";
CM_ SG_ 2571108354 BATT_fetChgShortedAux_2 "0 - FETs are operational (default)
1 - FET is shorted detected by auxiliary diagnostic";
CM_ SG_ 2571108354 BATT_prechargeFetFail_2 "0 - Precharge FET okay (default)
1 - Precharge FET failed";
CM_ SG_ 2571108354 BATT_abnormalResetReason_2 "0 - Reset reason okay (default)
1 - Abnormal reset reason";
CM_ SG_ 2571108354 BATT_prechargeTooSlow_2 "0 - Precharge okay (default)
1 - Precharge too slow";
CM_ SG_ 2571108354 BATT_prechargeTooFast_2 "0 - Precharge okay (default)
1 - Precharge too fast";
CM_ SG_ 2571108354 BATT_prechargeTimeout_2 "0 - Precharge okay (default)
1 - Precharge timeout";
CM_ SG_ 2571108354 BATT_fetChgShorted_2 "0 - FETs are operational (default)
1 - FET is shorted";
CM_ SG_ 2571108354 BATT_fetChgFailToClose_2 "0 - FETs are operational (default)
1 -  FET fail to close";
CM_ SG_ 2571108354 BATT_packModSelectFault_2 "0 - Battery pack module selection okay (default)
1 - Battery pack module selection fault";
CM_ SG_ 2571108354 BATT_packModConnectFault_2 "0 - Battery pack module connection okay (default)
1 - Battery pack module connection fault";
CM_ SG_ 2571108354 BATT_packModMIA_2 "0 - Battery pack modules not MIA (default)
1 - Battery pack module MIA";
CM_ SG_ 2571108354 BATT_packModImbalance_2 "0 - Battery pack modules balanced (default)
1 - Battery pack module imblance present";
CM_ SG_ 2571108354 BATT_afeFault_2 "0 - BMS AFE okay (default)
1 - BMS AFE fault";
CM_ SG_ 2571108354 BATT_chargerMIA_2 "0 - Charger communications okay (default)
1 - Charger MIA";
CM_ SG_ 2571108354 BATT_chargerError_2 "0 - Charger working as intended (default)
1 - Charger error";
CM_ SG_ 2571108354 BATT_vBrickUnderWar_2 "0 - Brick voltage okay (default)
1 - Brick undervoltage warning";
CM_ SG_ 2571108354 BATT_vBrickUnderSev_2 "0 - Brick voltage okay (default)
1 - Brick undervoltage severe";
CM_ SG_ 2571108354 BATT_vBrickUnderMod_2 "0 - Brick voltage okay (default)
1 - Brick undervoltage moderate";
CM_ SG_ 2571108354 BATT_vBrickOverWar_2 "0 - Brick voltage okay (default)
1 - Brick overvoltage warning";
CM_ SG_ 2571108354 BATT_vBrickOverSev_2 "0 - Brick voltage okay (default)
1 - Brick overvoltage severe";
CM_ SG_ 2571108354 BATT_vBrickOverMod_2 "0 - Brick voltage okay (default)
1 - Brick overvoltage moderate";
CM_ SG_ 2571108354 BATT_vBrickImbalance_2 "0 - Battery brick voltage okay (default)
1 - Battery brick voltage imbalance";
CM_ SG_ 2571108354 BATT_loggerAlmostFull_2 "0 - Logger not almost full (default)
1 - Logger almost full (section >= 80%) ";
CM_ SG_ 2571108354 BATT_tempModuleUnderWar_2 "0 - Battery temperature okay (default)
1 - Battery under temperature warning";
CM_ SG_ 2571108354 BATT_tempModuleUnderSev_2 "0 - Battery temperature okay (default)
1 - Battery under temperature severe";
CM_ SG_ 2571108354 BATT_tempModuleUnderMod_2 "0 - Battery temperature okay (default)
1 - Battery under temperature moderate";
CM_ SG_ 2571108354 BATT_tempModuleOverWar_2 "0 - Battery temperature okay (default)
1 - Battery over temperature warning";
CM_ SG_ 2571108354 BATT_tempModuleOverSev_2 "0 - Battery temperature okay (default)
1 - Battery over temperature severe";
CM_ SG_ 2571108354 BATT_tempModuleOverMod_2 "0 - Battery temperature okay (default)
1 - Battery over temperature moderate";
CM_ SG_ 2571108354 BATT_tempBrickImbalance_2 "0 - Brick temperatures are balanced (default)
1 - Brick temperatures are imbalanced";
CM_ SG_ 2571108354 BATT_taskLockupError_2 "0 - Tasks okay (default)
1 - Task lockup error";
CM_ SG_ 2571108354 BATT_tempAmbientOverWar_2 "0 - Ambient temperature okay (default)
1 - Ambient over temperature warning";
CM_ SG_ 2571108354 BATT_tempAmbientOverSev_2 "0 - Temperature okay (default)
1 - Ambient over temperature severe";
CM_ SG_ 2571108354 BATT_tempAmbientOverMod_2 "0 - Ambient temperature okay (default)
1 - Ambient over temparature moderate";
CM_ SG_ 2571108354 BATT_sensePackVoltError_2 "0 - Sensor okay (default)
1 - Sensor for pack voltage error";
CM_ SG_ 2571108354 BATT_senseLoadVoltError_2 "0 - Sensor okay (default)
1 - Sensor for load voltage error";
CM_ SG_ 2571108354 BATT_loggerFull_2 "0 - Logger not full (default)
1 - Logger full ";
CM_ SG_ 2571108354 BATT_senseCurrentError_2 "0 - Sensor okay (default)
1 - Sensor for current error";
CM_ SG_ 2571108354 BATT_senseBrickTempError_2 "0 - Sensor okay (default)
1 - Brick temperature sensor error";
CM_ SG_ 2571108354 BATT_resPackHigh_2 "0 - Battery pack resistance okay (default)
1 - Battery pack resistance high (High SOH-R)";
CM_ SG_ 2571108354 BATT_ramOverUtilError_2 "0 - RAM okay (default)
1 - RAM over utilization";
CM_ SG_ 2571108354 BATT_powerPackInsufficient_2 "0 - Battery pack power okay (default)
1 - Battery pack power insufficient";
CM_ SG_ 2571108354 BATT_packCellSoftShort_2 "0 - Battery back cells are okay (default)
1 - Battery pack cell soft short";
CM_ SG_ 2571108354 BATT_iOverHardware_2 "0 - Hardware current okay (default)
1 - Overcurrent in hardware";
CM_ SG_ 2571108354 BATT_fetOverTemp_2 "0 - FET temperature okay (default)
1 - Overtemp at FETs";
CM_ SG_ 2571108354 BATT_iOverDischarge_2 "0 - Discharge okay (default)
1 - Overcurrent during discharge";
CM_ SG_ 2571108354 BATT_iOverCharge_2 "0 - Charging okay (default)
1 - Overcurrent during charging";
CM_ SG_ 2571108354 BATT_inverterDriveMIA_2 "0 - Inverter drive present (default)
1 - Inverter drive MIA";
CM_ SG_ 2571108354 BATT_iUnderCharge_2 "0 - Normal charging (default)
1 -  Charging undercurrent (discharging)";
CM_ SG_ 2571108354 BATT_hostMIA_2 "0 - host communication open (default)
1 - host MIA";
CM_ SG_ 2571108354 BATT_fetDsgShorted_2 "0 - FETs are operational (default)
1 - FET is shorted";
CM_ SG_ 2571108354 BATT_fetDsgFailToClose_2 "0 - FETs are operational (default)
1 -  FET fail to close";
CM_ SG_ 2571108354 BATT_capLow_2 "0 - Battery capacity normal (SOH-C) (default)
1 - Low battery capacity (Low SOH-C)";
CM_ SG_ 2571108354 BATT_brickOverDischarge_2 "0 - Battery brick charge is normal (default)
1 - Battery brick is overdischarged";
CM_ SG_ 2571108354 BATT_brickOverCharge_2 "0 - Battery brick charge is normal (default)
1 - Battery brick is overcharged";
CM_ SG_ 2571108354 BATT_bmsProcessorError_2 "0 - No BMS processor failure (default)
1 - BMS processor failure";
CM_ SG_ 2571108354 BATT_bmsMemoryError_2 "0 - No BMS memory error
1 - BMS memory error";
CM_ SG_ 2571108354 BATT_afeError_2 "0 - No BMS AFE error (default)
1 - BMS AFE error";
CM_ BO_ 2571108355 "Message with flags from event matrix";
CM_ SG_ 2571108355 BATT_packModIdFault_3 "0 - Battery pack module ID okay (default)
1 - Battery pack module ID fault";
CM_ SG_ 2571108355 BATT_packModExitedFromBus_3 "0 - Battery pack modules OK (default)
1 - Battery pack module(s) exited from the bus during charge or drive";
CM_ SG_ 2571108355 BATT_packFetChgWelded_3 "0 - Battery pack module CHG FETs not welded (default)
1 - Battery pack module CHG FETs welded ";
CM_ SG_ 2571108355 BATT_packFetDsgWelded_3 "0 - Battery pack module DSG FETs not welded (default)
1 - Battery pack module DSG FETs welded ";
CM_ SG_ 2571108355 BATT_fetDsgShortedAux_3 "0 - FETs are operational (default)
1 - FET is shorted detected by auxiliary diagnostic";
CM_ SG_ 2571108355 BATT_fetChgShortedAux_3 "0 - FETs are operational (default)
1 - FET is shorted detected by auxiliary diagnostic";
CM_ SG_ 2571108355 BATT_prechargeFetFail_3 "0 - Precharge FET okay (default)
1 - Precharge FET failed";
CM_ SG_ 2571108355 BATT_abnormalResetReason_3 "0 - Reset reason okay (default)
1 - Abnormal reset reason";
CM_ SG_ 2571108355 BATT_prechargeTooSlow_3 "0 - Precharge okay (default)
1 - Precharge too slow";
CM_ SG_ 2571108355 BATT_prechargeTooFast_3 "0 - Precharge okay (default)
1 - Precharge too fast";
CM_ SG_ 2571108355 BATT_prechargeTimeout_3 "0 - Precharge okay (default)
1 - Precharge timeout";
CM_ SG_ 2571108355 BATT_fetChgShorted_3 "0 - FETs are operational (default)
1 - FET is shorted";
CM_ SG_ 2571108355 BATT_fetChgFailToClose_3 "0 - FETs are operational (default)
1 -  FET fail to close";
CM_ SG_ 2571108355 BATT_packModSelectFault_3 "0 - Battery pack module selection okay (default)
1 - Battery pack module selection fault";
CM_ SG_ 2571108355 BATT_packModConnectFault_3 "0 - Battery pack module connection okay (default)
1 - Battery pack module connection fault";
CM_ SG_ 2571108355 BATT_packModMIA_3 "0 - Battery pack modules not MIA (default)
1 - Battery pack module MIA";
CM_ SG_ 2571108355 BATT_packModImbalance_3 "0 - Battery pack modules balanced (default)
1 - Battery pack module imblance present";
CM_ SG_ 2571108355 BATT_afeFault_3 "0 - BMS AFE okay (default)
1 - BMS AFE fault";
CM_ SG_ 2571108355 BATT_chargerMIA_3 "0 - Charger communications okay (default)
1 - Charger MIA";
CM_ SG_ 2571108355 BATT_chargerError_3 "0 - Charger working as intended (default)
1 - Charger error";
CM_ SG_ 2571108355 BATT_vBrickUnderWar_3 "0 - Brick voltage okay (default)
1 - Brick undervoltage warning";
CM_ SG_ 2571108355 BATT_vBrickUnderSev_3 "0 - Brick voltage okay (default)
1 - Brick undervoltage severe";
CM_ SG_ 2571108355 BATT_vBrickUnderMod_3 "0 - Brick voltage okay (default)
1 - Brick undervoltage moderate";
CM_ SG_ 2571108355 BATT_vBrickOverWar_3 "0 - Brick voltage okay (default)
1 - Brick overvoltage warning";
CM_ SG_ 2571108355 BATT_vBrickOverSev_3 "0 - Brick voltage okay (default)
1 - Brick overvoltage severe";
CM_ SG_ 2571108355 BATT_vBrickOverMod_3 "0 - Brick voltage okay (default)
1 - Brick overvoltage moderate";
CM_ SG_ 2571108355 BATT_vBrickImbalance_3 "0 - Battery brick voltage okay (default)
1 - Battery brick voltage imbalance";
CM_ SG_ 2571108355 BATT_loggerAlmostFull_3 "0 - Logger not almost full (default)
1 - Logger almost full (section >= 80%) ";
CM_ SG_ 2571108355 BATT_tempModuleUnderWar_3 "0 - Battery temperature okay (default)
1 - Battery under temperature warning";
CM_ SG_ 2571108355 BATT_tempModuleUnderSev_3 "0 - Battery temperature okay (default)
1 - Battery under temperature severe";
CM_ SG_ 2571108355 BATT_tempModuleUnderMod_3 "0 - Battery temperature okay (default)
1 - Battery under temperature moderate";
CM_ SG_ 2571108355 BATT_tempModuleOverWar_3 "0 - Battery temperature okay (default)
1 - Battery over temperature warning";
CM_ SG_ 2571108355 BATT_tempModuleOverSev_3 "0 - Battery temperature okay (default)
1 - Battery over temperature severe";
CM_ SG_ 2571108355 BATT_tempModuleOverMod_3 "0 - Battery temperature okay (default)
1 - Battery over temperature moderate";
CM_ SG_ 2571108355 BATT_tempBrickImbalance_3 "0 - Brick temperatures are balanced (default)
1 - Brick temperatures are imbalanced";
CM_ SG_ 2571108355 BATT_taskLockupError_3 "0 - Tasks okay (default)
1 - Task lockup error";
CM_ SG_ 2571108355 BATT_tempAmbientOverWar_3 "0 - Ambient temperature okay (default)
1 - Ambient over temperature warning";
CM_ SG_ 2571108355 BATT_tempAmbientOverSev_3 "0 - Temperature okay (default)
1 - Ambient over temperature severe";
CM_ SG_ 2571108355 BATT_tempAmbientOverMod_3 "0 - Ambient temperature okay (default)
1 - Ambient over temparature moderate";
CM_ SG_ 2571108355 BATT_sensePackVoltError_3 "0 - Sensor okay (default)
1 - Sensor for pack voltage error";
CM_ SG_ 2571108355 BATT_senseLoadVoltError_3 "0 - Sensor okay (default)
1 - Sensor for load voltage error";
CM_ SG_ 2571108355 BATT_loggerFull_3 "0 - Logger not full (default)
1 - Logger full ";
CM_ SG_ 2571108355 BATT_senseCurrentError_3 "0 - Sensor okay (default)
1 - Sensor for current error";
CM_ SG_ 2571108355 BATT_senseBrickTempError_3 "0 - Sensor okay (default)
1 - Brick temperature sensor error";
CM_ SG_ 2571108355 BATT_resPackHigh_3 "0 - Battery pack resistance okay (default)
1 - Battery pack resistance high (High SOH-R)";
CM_ SG_ 2571108355 BATT_ramOverUtilError_3 "0 - RAM okay (default)
1 - RAM over utilization";
CM_ SG_ 2571108355 BATT_powerPackInsufficient_3 "0 - Battery pack power okay (default)
1 - Battery pack power insufficient";
CM_ SG_ 2571108355 BATT_packCellSoftShort_3 "0 - Battery back cells are okay (default)
1 - Battery pack cell soft short";
CM_ SG_ 2571108355 BATT_iOverHardware_3 "0 - Hardware current okay (default)
1 - Overcurrent in hardware";
CM_ SG_ 2571108355 BATT_fetOverTemp_3 "0 - FET temperature okay (default)
1 - Overtemp at FETs";
CM_ SG_ 2571108355 BATT_iOverDischarge_3 "0 - Discharge okay (default)
1 - Overcurrent during discharge";
CM_ SG_ 2571108355 BATT_iOverCharge_3 "0 - Charging okay (default)
1 - Overcurrent during charging";
CM_ SG_ 2571108355 BATT_inverterDriveMIA_3 "0 - Inverter drive present (default)
1 - Inverter drive MIA";
CM_ SG_ 2571108355 BATT_iUnderCharge_3 "0 - Normal charging (default)
1 -  Charging undercurrent (discharging)";
CM_ SG_ 2571108355 BATT_hostMIA_3 "0 - host communication open (default)
1 - host MIA";
CM_ SG_ 2571108355 BATT_fetDsgShorted_3 "0 - FETs are operational (default)
1 - FET is shorted";
CM_ SG_ 2571108355 BATT_fetDsgFailToClose_3 "0 - FETs are operational (default)
1 -  FET fail to close";
CM_ SG_ 2571108355 BATT_capLow_3 "0 - Battery capacity normal (SOH-C) (default)
1 - Low battery capacity (Low SOH-C)";
CM_ SG_ 2571108355 BATT_brickOverDischarge_3 "0 - Battery brick charge is normal (default)
1 - Battery brick is overdischarged";
CM_ SG_ 2571108355 BATT_brickOverCharge_3 "0 - Battery brick charge is normal (default)
1 - Battery brick is overcharged";
CM_ SG_ 2571108355 BATT_bmsProcessorError_3 "0 - No BMS processor failure (default)
1 - BMS processor failure";
CM_ SG_ 2571108355 BATT_bmsMemoryError_3 "0 - No BMS memory error
1 - BMS memory error";
CM_ SG_ 2571108355 BATT_afeError_3 "0 - No BMS AFE error (default)
1 - BMS AFE error";
CM_ BO_ 2571108356 "Message with flags from event matrix";
CM_ SG_ 2571108356 BATT_packModIdFault_4 "0 - Battery pack module ID okay (default)
1 - Battery pack module ID fault";
CM_ SG_ 2571108356 BATT_packModExitedFromBus_4 "0 - Battery pack modules OK (default)
1 - Battery pack module(s) exited from the bus during charge or drive";
CM_ SG_ 2571108356 BATT_packFetChgWelded_4 "0 - Battery pack module CHG FETs not welded (default)
1 - Battery pack module CHG FETs welded ";
CM_ SG_ 2571108356 BATT_packFetDsgWelded_4 "0 - Battery pack module DSG FETs not welded (default)
1 - Battery pack module DSG FETs welded ";
CM_ SG_ 2571108356 BATT_fetDsgShortedAux_4 "0 - FETs are operational (default)
1 - FET is shorted detected by auxiliary diagnostic";
CM_ SG_ 2571108356 BATT_fetChgShortedAux_4 "0 - FETs are operational (default)
1 - FET is shorted detected by auxiliary diagnostic";
CM_ SG_ 2571108356 BATT_prechargeFetFail_4 "0 - Precharge FET okay (default)
1 - Precharge FET failed";
CM_ SG_ 2571108356 BATT_abnormalResetReason_4 "0 - Reset reason okay (default)
1 - Abnormal reset reason";
CM_ SG_ 2571108356 BATT_prechargeTooSlow_4 "0 - Precharge okay (default)
1 - Precharge too slow";
CM_ SG_ 2571108356 BATT_prechargeTooFast_4 "0 - Precharge okay (default)
1 - Precharge too fast";
CM_ SG_ 2571108356 BATT_prechargeTimeout_4 "0 - Precharge okay (default)
1 - Precharge timeout";
CM_ SG_ 2571108356 BATT_fetChgShorted_4 "0 - FETs are operational (default)
1 - FET is shorted";
CM_ SG_ 2571108356 BATT_fetChgFailToClose_4 "0 - FETs are operational (default)
1 -  FET fail to close";
CM_ SG_ 2571108356 BATT_packModSelectFault_4 "0 - Battery pack module selection okay (default)
1 - Battery pack module selection fault";
CM_ SG_ 2571108356 BATT_packModConnectFault_4 "0 - Battery pack module connection okay (default)
1 - Battery pack module connection fault";
CM_ SG_ 2571108356 BATT_packModMIA_4 "0 - Battery pack modules not MIA (default)
1 - Battery pack module MIA";
CM_ SG_ 2571108356 BATT_packModImbalance_4 "0 - Battery pack modules balanced (default)
1 - Battery pack module imblance present";
CM_ SG_ 2571108356 BATT_afeFault_4 "0 - BMS AFE okay (default)
1 - BMS AFE fault";
CM_ SG_ 2571108356 BATT_chargerMIA_4 "0 - Charger communications okay (default)
1 - Charger MIA";
CM_ SG_ 2571108356 BATT_chargerError_4 "0 - Charger working as intended (default)
1 - Charger error";
CM_ SG_ 2571108356 BATT_vBrickUnderWar_4 "0 - Brick voltage okay (default)
1 - Brick undervoltage warning";
CM_ SG_ 2571108356 BATT_vBrickUnderSev_4 "0 - Brick voltage okay (default)
1 - Brick undervoltage severe";
CM_ SG_ 2571108356 BATT_vBrickUnderMod_4 "0 - Brick voltage okay (default)
1 - Brick undervoltage moderate";
CM_ SG_ 2571108356 BATT_vBrickOverWar_4 "0 - Brick voltage okay (default)
1 - Brick overvoltage warning";
CM_ SG_ 2571108356 BATT_vBrickOverSev_4 "0 - Brick voltage okay (default)
1 - Brick overvoltage severe";
CM_ SG_ 2571108356 BATT_vBrickOverMod_4 "0 - Brick voltage okay (default)
1 - Brick overvoltage moderate";
CM_ SG_ 2571108356 BATT_vBrickImbalance_4 "0 - Battery brick voltage okay (default)
1 - Battery brick voltage imbalance";
CM_ SG_ 2571108356 BATT_loggerAlmostFull_4 "0 - Logger not almost full (default)
1 - Logger almost full (section >= 80%) ";
CM_ SG_ 2571108356 BATT_tempModuleUnderWar_4 "0 - Battery temperature okay (default)
1 - Battery under temperature warning";
CM_ SG_ 2571108356 BATT_tempModuleUnderSev_4 "0 - Battery temperature okay (default)
1 - Battery under temperature severe";
CM_ SG_ 2571108356 BATT_tempModuleUnderMod_4 "0 - Battery temperature okay (default)
1 - Battery under temperature moderate";
CM_ SG_ 2571108356 BATT_tempModuleOverWar_4 "0 - Battery temperature okay (default)
1 - Battery over temperature warning";
CM_ SG_ 2571108356 BATT_tempModuleOverSev_4 "0 - Battery temperature okay (default)
1 - Battery over temperature severe";
CM_ SG_ 2571108356 BATT_tempModuleOverMod_4 "0 - Battery temperature okay (default)
1 - Battery over temperature moderate";
CM_ SG_ 2571108356 BATT_tempBrickImbalance_4 "0 - Brick temperatures are balanced (default)
1 - Brick temperatures are imbalanced";
CM_ SG_ 2571108356 BATT_taskLockupError_4 "0 - Tasks okay (default)
1 - Task lockup error";
CM_ SG_ 2571108356 BATT_tempAmbientOverWar_4 "0 - Ambient temperature okay (default)
1 - Ambient over temperature warning";
CM_ SG_ 2571108356 BATT_tempAmbientOverSev_4 "0 - Temperature okay (default)
1 - Ambient over temperature severe";
CM_ SG_ 2571108356 BATT_tempAmbientOverMod_4 "0 - Ambient temperature okay (default)
1 - Ambient over temparature moderate";
CM_ SG_ 2571108356 BATT_sensePackVoltError_4 "0 - Sensor okay (default)
1 - Sensor for pack voltage error";
CM_ SG_ 2571108356 BATT_senseLoadVoltError_4 "0 - Sensor okay (default)
1 - Sensor for load voltage error";
CM_ SG_ 2571108356 BATT_loggerFull_4 "0 - Logger not full (default)
1 - Logger full ";
CM_ SG_ 2571108356 BATT_senseCurrentError_4 "0 - Sensor okay (default)
1 - Sensor for current error";
CM_ SG_ 2571108356 BATT_senseBrickTempError_4 "0 - Sensor okay (default)
1 - Brick temperature sensor error";
CM_ SG_ 2571108356 BATT_resPackHigh_4 "0 - Battery pack resistance okay (default)
1 - Battery pack resistance high (High SOH-R)";
CM_ SG_ 2571108356 BATT_ramOverUtilError_4 "0 - RAM okay (default)
1 - RAM over utilization";
CM_ SG_ 2571108356 BATT_powerPackInsufficient_4 "0 - Battery pack power okay (default)
1 - Battery pack power insufficient";
CM_ SG_ 2571108356 BATT_packCellSoftShort_4 "0 - Battery back cells are okay (default)
1 - Battery pack cell soft short";
CM_ SG_ 2571108356 BATT_iOverHardware_4 "0 - Hardware current okay (default)
1 - Overcurrent in hardware";
CM_ SG_ 2571108356 BATT_fetOverTemp_4 "0 - FET temperature okay (default)
1 - Overtemp at FETs";
CM_ SG_ 2571108356 BATT_iOverDischarge_4 "0 - Discharge okay (default)
1 - Overcurrent during discharge";
CM_ SG_ 2571108356 BATT_iOverCharge_4 "0 - Charging okay (default)
1 - Overcurrent during charging";
CM_ SG_ 2571108356 BATT_inverterDriveMIA_4 "0 - Inverter drive present (default)
1 - Inverter drive MIA";
CM_ SG_ 2571108356 BATT_iUnderCharge_4 "0 - Normal charging (default)
1 -  Charging undercurrent (discharging)";
CM_ SG_ 2571108356 BATT_hostMIA_4 "0 - host communication open (default)
1 - host MIA";
CM_ SG_ 2571108356 BATT_fetDsgShorted_4 "0 - FETs are operational (default)
1 - FET is shorted";
CM_ SG_ 2571108356 BATT_fetDsgFailToClose_4 "0 - FETs are operational (default)
1 -  FET fail to close";
CM_ SG_ 2571108356 BATT_capLow_4 "0 - Battery capacity normal (SOH-C) (default)
1 - Low battery capacity (Low SOH-C)";
CM_ SG_ 2571108356 BATT_brickOverDischarge_4 "0 - Battery brick charge is normal (default)
1 - Battery brick is overdischarged";
CM_ SG_ 2571108356 BATT_brickOverCharge_4 "0 - Battery brick charge is normal (default)
1 - Battery brick is overcharged";
CM_ SG_ 2571108356 BATT_bmsProcessorError_4 "0 - No BMS processor failure (default)
1 - BMS processor failure";
CM_ SG_ 2571108356 BATT_bmsMemoryError_4 "0 - No BMS memory error
1 - BMS memory error";
CM_ SG_ 2571108356 BATT_afeError_4 "0 - No BMS AFE error (default)
1 - BMS AFE error";
CM_ BO_ 2571108357 "Message with flags from event matrix";
CM_ SG_ 2571108357 BATT_packModIdFault_5 "0 - Battery pack module ID okay (default)
1 - Battery pack module ID fault";
CM_ SG_ 2571108357 BATT_packModExitedFromBus_5 "0 - Battery pack modules OK (default)
1 - Battery pack module(s) exited from the bus during charge or drive";
CM_ SG_ 2571108357 BATT_packFetChgWelded_5 "0 - Battery pack module CHG FETs not welded (default)
1 - Battery pack module CHG FETs welded ";
CM_ SG_ 2571108357 BATT_packFetDsgWelded_5 "0 - Battery pack module DSG FETs not welded (default)
1 - Battery pack module DSG FETs welded ";
CM_ SG_ 2571108357 BATT_fetDsgShortedAux_5 "0 - FETs are operational (default)
1 - FET is shorted detected by auxiliary diagnostic";
CM_ SG_ 2571108357 BATT_fetChgShortedAux_5 "0 - FETs are operational (default)
1 - FET is shorted detected by auxiliary diagnostic";
CM_ SG_ 2571108357 BATT_prechargeFetFail_5 "0 - Precharge FET okay (default)
1 - Precharge FET failed";
CM_ SG_ 2571108357 BATT_abnormalResetReason_5 "0 - Reset reason okay (default)
1 - Abnormal reset reason";
CM_ SG_ 2571108357 BATT_prechargeTooSlow_5 "0 - Precharge okay (default)
1 - Precharge too slow";
CM_ SG_ 2571108357 BATT_prechargeTooFast_5 "0 - Precharge okay (default)
1 - Precharge too fast";
CM_ SG_ 2571108357 BATT_prechargeTimeout_5 "0 - Precharge okay (default)
1 - Precharge timeout";
CM_ SG_ 2571108357 BATT_fetChgShorted_5 "0 - FETs are operational (default)
1 - FET is shorted";
CM_ SG_ 2571108357 BATT_fetChgFailToClose_5 "0 - FETs are operational (default)
1 -  FET fail to close";
CM_ SG_ 2571108357 BATT_packModSelectFault_5 "0 - Battery pack module selection okay (default)
1 - Battery pack module selection fault";
CM_ SG_ 2571108357 BATT_packModConnectFault_5 "0 - Battery pack module connection okay (default)
1 - Battery pack module connection fault";
CM_ SG_ 2571108357 BATT_packModMIA_5 "0 - Battery pack modules not MIA (default)
1 - Battery pack module MIA";
CM_ SG_ 2571108357 BATT_packModImbalance_5 "0 - Battery pack modules balanced (default)
1 - Battery pack module imblance present";
CM_ SG_ 2571108357 BATT_afeFault_5 "0 - BMS AFE okay (default)
1 - BMS AFE fault";
CM_ SG_ 2571108357 BATT_chargerMIA_5 "0 - Charger communications okay (default)
1 - Charger MIA";
CM_ SG_ 2571108357 BATT_chargerError_5 "0 - Charger working as intended (default)
1 - Charger error";
CM_ SG_ 2571108357 BATT_vBrickUnderWar_5 "0 - Brick voltage okay (default)
1 - Brick undervoltage warning";
CM_ SG_ 2571108357 BATT_vBrickUnderSev_5 "0 - Brick voltage okay (default)
1 - Brick undervoltage severe";
CM_ SG_ 2571108357 BATT_vBrickUnderMod_5 "0 - Brick voltage okay (default)
1 - Brick undervoltage moderate";
CM_ SG_ 2571108357 BATT_vBrickOverWar_5 "0 - Brick voltage okay (default)
1 - Brick overvoltage warning";
CM_ SG_ 2571108357 BATT_vBrickOverSev_5 "0 - Brick voltage okay (default)
1 - Brick overvoltage severe";
CM_ SG_ 2571108357 BATT_vBrickOverMod_5 "0 - Brick voltage okay (default)
1 - Brick overvoltage moderate";
CM_ SG_ 2571108357 BATT_vBrickImbalance_5 "0 - Battery brick voltage okay (default)
1 - Battery brick voltage imbalance";
CM_ SG_ 2571108357 BATT_loggerAlmostFull_5 "0 - Logger not almost full (default)
1 - Logger almost full (section >= 80%) ";
CM_ SG_ 2571108357 BATT_tempModuleUnderWar_5 "0 - Battery temperature okay (default)
1 - Battery under temperature warning";
CM_ SG_ 2571108357 BATT_tempModuleUnderSev_5 "0 - Battery temperature okay (default)
1 - Battery under temperature severe";
CM_ SG_ 2571108357 BATT_tempModuleUnderMod_5 "0 - Battery temperature okay (default)
1 - Battery under temperature moderate";
CM_ SG_ 2571108357 BATT_tempModuleOverWar_5 "0 - Battery temperature okay (default)
1 - Battery over temperature warning";
CM_ SG_ 2571108357 BATT_tempModuleOverSev_5 "0 - Battery temperature okay (default)
1 - Battery over temperature severe";
CM_ SG_ 2571108357 BATT_tempModuleOverMod_5 "0 - Battery temperature okay (default)
1 - Battery over temperature moderate";
CM_ SG_ 2571108357 BATT_tempBrickImbalance_5 "0 - Brick temperatures are balanced (default)
1 - Brick temperatures are imbalanced";
CM_ SG_ 2571108357 BATT_taskLockupError_5 "0 - Tasks okay (default)
1 - Task lockup error";
CM_ SG_ 2571108357 BATT_tempAmbientOverWar_5 "0 - Ambient temperature okay (default)
1 - Ambient over temperature warning";
CM_ SG_ 2571108357 BATT_tempAmbientOverSev_5 "0 - Temperature okay (default)
1 - Ambient over temperature severe";
CM_ SG_ 2571108357 BATT_tempAmbientOverMod_5 "0 - Ambient temperature okay (default)
1 - Ambient over temparature moderate";
CM_ SG_ 2571108357 BATT_sensePackVoltError_5 "0 - Sensor okay (default)
1 - Sensor for pack voltage error";
CM_ SG_ 2571108357 BATT_senseLoadVoltError_5 "0 - Sensor okay (default)
1 - Sensor for load voltage error";
CM_ SG_ 2571108357 BATT_loggerFull_5 "0 - Logger not full (default)
1 - Logger full ";
CM_ SG_ 2571108357 BATT_senseCurrentError_5 "0 - Sensor okay (default)
1 - Sensor for current error";
CM_ SG_ 2571108357 BATT_senseBrickTempError_5 "0 - Sensor okay (default)
1 - Brick temperature sensor error";
CM_ SG_ 2571108357 BATT_resPackHigh_5 "0 - Battery pack resistance okay (default)
1 - Battery pack resistance high (High SOH-R)";
CM_ SG_ 2571108357 BATT_ramOverUtilError_5 "0 - RAM okay (default)
1 - RAM over utilization";
CM_ SG_ 2571108357 BATT_powerPackInsufficient_5 "0 - Battery pack power okay (default)
1 - Battery pack power insufficient";
CM_ SG_ 2571108357 BATT_packCellSoftShort_5 "0 - Battery back cells are okay (default)
1 - Battery pack cell soft short";
CM_ SG_ 2571108357 BATT_iOverHardware_5 "0 - Hardware current okay (default)
1 - Overcurrent in hardware";
CM_ SG_ 2571108357 BATT_fetOverTemp_5 "0 - FET temperature okay (default)
1 - Overtemp at FETs";
CM_ SG_ 2571108357 BATT_iOverDischarge_5 "0 - Discharge okay (default)
1 - Overcurrent during discharge";
CM_ SG_ 2571108357 BATT_iOverCharge_5 "0 - Charging okay (default)
1 - Overcurrent during charging";
CM_ SG_ 2571108357 BATT_inverterDriveMIA_5 "0 - Inverter drive present (default)
1 - Inverter drive MIA";
CM_ SG_ 2571108357 BATT_iUnderCharge_5 "0 - Normal charging (default)
1 -  Charging undercurrent (discharging)";
CM_ SG_ 2571108357 BATT_hostMIA_5 "0 - host communication open (default)
1 - host MIA";
CM_ SG_ 2571108357 BATT_fetDsgShorted_5 "0 - FETs are operational (default)
1 - FET is shorted";
CM_ SG_ 2571108357 BATT_fetDsgFailToClose_5 "0 - FETs are operational (default)
1 -  FET fail to close";
CM_ SG_ 2571108357 BATT_capLow_5 "0 - Battery capacity normal (SOH-C) (default)
1 - Low battery capacity (Low SOH-C)";
CM_ SG_ 2571108357 BATT_brickOverDischarge_5 "0 - Battery brick charge is normal (default)
1 - Battery brick is overdischarged";
CM_ SG_ 2571108357 BATT_brickOverCharge_5 "0 - Battery brick charge is normal (default)
1 - Battery brick is overcharged";
CM_ SG_ 2571108357 BATT_bmsProcessorError_5 "0 - No BMS processor failure (default)
1 - BMS processor failure";
CM_ SG_ 2571108357 BATT_bmsMemoryError_5 "0 - No BMS memory error
1 - BMS memory error";
CM_ SG_ 2571108357 BATT_afeError_5 "0 - No BMS AFE error (default)
1 - BMS AFE error";
CM_ BO_ 2571108358 "Message with flags from event matrix";
CM_ SG_ 2571108358 BATT_packModIdFault_6 "0 - Battery pack module ID okay (default)
1 - Battery pack module ID fault";
CM_ SG_ 2571108358 BATT_packModExitedFromBus_6 "0 - Battery pack modules OK (default)
1 - Battery pack module(s) exited from the bus during charge or drive";
CM_ SG_ 2571108358 BATT_packFetChgWelded_6 "0 - Battery pack module CHG FETs not welded (default)
1 - Battery pack module CHG FETs welded ";
CM_ SG_ 2571108358 BATT_packFetDsgWelded_6 "0 - Battery pack module DSG FETs not welded (default)
1 - Battery pack module DSG FETs welded ";
CM_ SG_ 2571108358 BATT_fetDsgShortedAux_6 "0 - FETs are operational (default)
1 - FET is shorted detected by auxiliary diagnostic";
CM_ SG_ 2571108358 BATT_fetChgShortedAux_6 "0 - FETs are operational (default)
1 - FET is shorted detected by auxiliary diagnostic";
CM_ SG_ 2571108358 BATT_prechargeFetFail_6 "0 - Precharge FET okay (default)
1 - Precharge FET failed";
CM_ SG_ 2571108358 BATT_abnormalResetReason_6 "0 - Reset reason okay (default)
1 - Abnormal reset reason";
CM_ SG_ 2571108358 BATT_prechargeTooSlow_6 "0 - Precharge okay (default)
1 - Precharge too slow";
CM_ SG_ 2571108358 BATT_prechargeTooFast_6 "0 - Precharge okay (default)
1 - Precharge too fast";
CM_ SG_ 2571108358 BATT_prechargeTimeout_6 "0 - Precharge okay (default)
1 - Precharge timeout";
CM_ SG_ 2571108358 BATT_fetChgShorted_6 "0 - FETs are operational (default)
1 - FET is shorted";
CM_ SG_ 2571108358 BATT_fetChgFailToClose_6 "0 - FETs are operational (default)
1 -  FET fail to close";
CM_ SG_ 2571108358 BATT_packModSelectFault_6 "0 - Battery pack module selection okay (default)
1 - Battery pack module selection fault";
CM_ SG_ 2571108358 BATT_packModConnectFault_6 "0 - Battery pack module connection okay (default)
1 - Battery pack module connection fault";
CM_ SG_ 2571108358 BATT_packModMIA_6 "0 - Battery pack modules not MIA (default)
1 - Battery pack module MIA";
CM_ SG_ 2571108358 BATT_packModImbalance_6 "0 - Battery pack modules balanced (default)
1 - Battery pack module imblance present";
CM_ SG_ 2571108358 BATT_afeFault_6 "0 - BMS AFE okay (default)
1 - BMS AFE fault";
CM_ SG_ 2571108358 BATT_chargerMIA_6 "0 - Charger communications okay (default)
1 - Charger MIA";
CM_ SG_ 2571108358 BATT_chargerError_6 "0 - Charger working as intended (default)
1 - Charger error";
CM_ SG_ 2571108358 BATT_vBrickUnderWar_6 "0 - Brick voltage okay (default)
1 - Brick undervoltage warning";
CM_ SG_ 2571108358 BATT_vBrickUnderSev_6 "0 - Brick voltage okay (default)
1 - Brick undervoltage severe";
CM_ SG_ 2571108358 BATT_vBrickUnderMod_6 "0 - Brick voltage okay (default)
1 - Brick undervoltage moderate";
CM_ SG_ 2571108358 BATT_vBrickOverWar_6 "0 - Brick voltage okay (default)
1 - Brick overvoltage warning";
CM_ SG_ 2571108358 BATT_vBrickOverSev_6 "0 - Brick voltage okay (default)
1 - Brick overvoltage severe";
CM_ SG_ 2571108358 BATT_vBrickOverMod_6 "0 - Brick voltage okay (default)
1 - Brick overvoltage moderate";
CM_ SG_ 2571108358 BATT_vBrickImbalance_6 "0 - Battery brick voltage okay (default)
1 - Battery brick voltage imbalance";
CM_ SG_ 2571108358 BATT_loggerAlmostFull_6 "0 - Logger not almost full (default)
1 - Logger almost full (section >= 80%) ";
CM_ SG_ 2571108358 BATT_tempModuleUnderWar_6 "0 - Battery temperature okay (default)
1 - Battery under temperature warning";
CM_ SG_ 2571108358 BATT_tempModuleUnderSev_6 "0 - Battery temperature okay (default)
1 - Battery under temperature severe";
CM_ SG_ 2571108358 BATT_tempModuleUnderMod_6 "0 - Battery temperature okay (default)
1 - Battery under temperature moderate";
CM_ SG_ 2571108358 BATT_tempModuleOverWar_6 "0 - Battery temperature okay (default)
1 - Battery over temperature warning";
CM_ SG_ 2571108358 BATT_tempModuleOverSev_6 "0 - Battery temperature okay (default)
1 - Battery over temperature severe";
CM_ SG_ 2571108358 BATT_tempModuleOverMod_6 "0 - Battery temperature okay (default)
1 - Battery over temperature moderate";
CM_ SG_ 2571108358 BATT_tempBrickImbalance_6 "0 - Brick temperatures are balanced (default)
1 - Brick temperatures are imbalanced";
CM_ SG_ 2571108358 BATT_taskLockupError_6 "0 - Tasks okay (default)
1 - Task lockup error";
CM_ SG_ 2571108358 BATT_tempAmbientOverWar_6 "0 - Ambient temperature okay (default)
1 - Ambient over temperature warning";
CM_ SG_ 2571108358 BATT_tempAmbientOverSev_6 "0 - Temperature okay (default)
1 - Ambient over temperature severe";
CM_ SG_ 2571108358 BATT_tempAmbientOverMod_6 "0 - Ambient temperature okay (default)
1 - Ambient over temparature moderate";
CM_ SG_ 2571108358 BATT_sensePackVoltError_6 "0 - Sensor okay (default)
1 - Sensor for pack voltage error";
CM_ SG_ 2571108358 BATT_senseLoadVoltError_6 "0 - Sensor okay (default)
1 - Sensor for load voltage error";
CM_ SG_ 2571108358 BATT_loggerFull_6 "0 - Logger not full (default)
1 - Logger full ";
CM_ SG_ 2571108358 BATT_senseCurrentError_6 "0 - Sensor okay (default)
1 - Sensor for current error";
CM_ SG_ 2571108358 BATT_senseBrickTempError_6 "0 - Sensor okay (default)
1 - Brick temperature sensor error";
CM_ SG_ 2571108358 BATT_resPackHigh_6 "0 - Battery pack resistance okay (default)
1 - Battery pack resistance high (High SOH-R)";
CM_ SG_ 2571108358 BATT_ramOverUtilError_6 "0 - RAM okay (default)
1 - RAM over utilization";
CM_ SG_ 2571108358 BATT_powerPackInsufficient_6 "0 - Battery pack power okay (default)
1 - Battery pack power insufficient";
CM_ SG_ 2571108358 BATT_packCellSoftShort_6 "0 - Battery back cells are okay (default)
1 - Battery pack cell soft short";
CM_ SG_ 2571108358 BATT_iOverHardware_6 "0 - Hardware current okay (default)
1 - Overcurrent in hardware";
CM_ SG_ 2571108358 BATT_fetOverTemp_6 "0 - FET temperature okay (default)
1 - Overtemp at FETs";
CM_ SG_ 2571108358 BATT_iOverDischarge_6 "0 - Discharge okay (default)
1 - Overcurrent during discharge";
CM_ SG_ 2571108358 BATT_iOverCharge_6 "0 - Charging okay (default)
1 - Overcurrent during charging";
CM_ SG_ 2571108358 BATT_inverterDriveMIA_6 "0 - Inverter drive present (default)
1 - Inverter drive MIA";
CM_ SG_ 2571108358 BATT_iUnderCharge_6 "0 - Normal charging (default)
1 -  Charging undercurrent (discharging)";
CM_ SG_ 2571108358 BATT_hostMIA_6 "0 - host communication open (default)
1 - host MIA";
CM_ SG_ 2571108358 BATT_fetDsgShorted_6 "0 - FETs are operational (default)
1 - FET is shorted";
CM_ SG_ 2571108358 BATT_fetDsgFailToClose_6 "0 - FETs are operational (default)
1 -  FET fail to close";
CM_ SG_ 2571108358 BATT_capLow_6 "0 - Battery capacity normal (SOH-C) (default)
1 - Low battery capacity (Low SOH-C)";
CM_ SG_ 2571108358 BATT_brickOverDischarge_6 "0 - Battery brick charge is normal (default)
1 - Battery brick is overdischarged";
CM_ SG_ 2571108358 BATT_brickOverCharge_6 "0 - Battery brick charge is normal (default)
1 - Battery brick is overcharged";
CM_ SG_ 2571108358 BATT_bmsProcessorError_6 "0 - No BMS processor failure (default)
1 - BMS processor failure";
CM_ SG_ 2571108358 BATT_bmsMemoryError_6 "0 - No BMS memory error
1 - BMS memory error";
CM_ SG_ 2571108358 BATT_afeError_6 "0 - No BMS AFE error (default)
1 - BMS AFE error";

BA_DEF_ BO_  "GenMsgDiag" ENUM "No","Yes";
BA_DEF_ BO_  "GenMsgInstanced" STRING ;
BA_DEF_ SG_  "GenSigType" ENUM "Extended","Diagnostic","Standard","Modified";
BA_DEF_ BO_  "GenMsgCycleTime" INT 0 0;
BA_DEF_ SG_  "GenSigSNA" INT 0 65535;
BA_DEF_ SG_  "Access" ENUM "r","rw";
BA_DEF_DEF_  "GenMsgDiag" "No";
BA_DEF_DEF_  "GenMsgInstanced" "No";
BA_DEF_DEF_  "GenSigType" "Standard";
BA_DEF_DEF_  "GenMsgCycleTime" 0;
BA_DEF_DEF_  "GenSigSNA" 0;
BA_DEF_DEF_  "Access" "r";
BA_ "GenMsgDiag" BO_ 2550398976 1;
BA_ "GenMsgDiag" BO_ 2550398977 1;
BA_ "GenMsgDiag" BO_ 2550398978 1;
BA_ "GenMsgDiag" BO_ 2550398979 1;
BA_ "GenMsgDiag" BO_ 2550398980 1;
BA_ "GenMsgDiag" BO_ 2550398981 1;
BA_ "GenMsgDiag" BO_ 2550398982 1;
BA_ "GenMsgDiag" BO_ 2550398983 1;
BA_ "GenMsgInstanced" BO_ 2483290116 "False";
BA_ "GenMsgInstanced" BO_ 2483290117 "False";
BA_ "GenMsgInstanced" BO_ 2483290118 "False";
BA_ "GenMsgInstanced" BO_ 2483290119 "False";
BA_ "GenMsgInstanced" BO_ 2487484416 "False";
BA_ "GenMsgInstanced" BO_ 2487484417 "False";
BA_ "GenMsgInstanced" BO_ 2487484418 "False";
BA_ "GenMsgInstanced" BO_ 2487484419 "False";
BA_ "GenMsgInstanced" BO_ 2487484420 "False";
BA_ "GenMsgInstanced" BO_ 2487484421 "False";
BA_ "GenMsgInstanced" BO_ 2487484422 "False";
BA_ "GenMsgInstanced" BO_ 2487484423 "False";
BA_ "GenMsgInstanced" BO_ 2508193792 "False";
BA_ "GenMsgInstanced" BO_ 2508193793 "False";
BA_ "GenMsgInstanced" BO_ 2508193794 "False";
BA_ "GenMsgInstanced" BO_ 2508193795 "False";
BA_ "GenMsgInstanced" BO_ 2508193796 "False";
BA_ "GenMsgInstanced" BO_ 2508193797 "False";
BA_ "GenMsgInstanced" BO_ 2508193798 "False";
BA_ "GenMsgInstanced" BO_ 2508193799 "False";
BA_ "GenMsgInstanced" BO_ 2550398976 "False";
BA_ "GenMsgInstanced" BO_ 2550398977 "False";
BA_ "GenMsgInstanced" BO_ 2550398978 "False";
BA_ "GenMsgInstanced" BO_ 2550398979 "False";
BA_ "GenMsgInstanced" BO_ 2550398980 "False";
BA_ "GenMsgInstanced" BO_ 2550398981 "False";
BA_ "GenMsgInstanced" BO_ 2550398982 "False";
BA_ "GenMsgInstanced" BO_ 2550398983 "False";
BA_ "GenMsgInstanced" BO_ 2550661120 "False";
BA_ "GenMsgInstanced" BO_ 2550661121 "False";
BA_ "GenMsgInstanced" BO_ 2550661122 "False";
BA_ "GenMsgInstanced" BO_ 2550661123 "False";
BA_ "GenMsgInstanced" BO_ 2550661124 "False";
BA_ "GenMsgInstanced" BO_ 2550661125 "False";
BA_ "GenMsgInstanced" BO_ 2550661126 "False";
BA_ "GenMsgInstanced" BO_ 2550661127 "False";
BA_ "GenMsgInstanced" BO_ 2551447552 "False";
BA_ "GenMsgInstanced" BO_ 2551447553 "False";
BA_ "GenMsgInstanced" BO_ 2551447554 "False";
BA_ "GenMsgInstanced" BO_ 2551447555 "False";
BA_ "GenMsgInstanced" BO_ 2551447556 "False";
BA_ "GenMsgInstanced" BO_ 2551447557 "False";
BA_ "GenMsgInstanced" BO_ 2551447558 "False";
BA_ "GenMsgInstanced" BO_ 2551447559 "False";
BA_ "GenMsgInstanced" BO_ 2571108352 "False";
BA_ "GenMsgInstanced" BO_ 2571108353 "False";
BA_ "GenMsgInstanced" BO_ 2571108354 "False";
BA_ "GenMsgInstanced" BO_ 2571108355 "False";
BA_ "GenMsgInstanced" BO_ 2571108356 "False";
BA_ "GenMsgInstanced" BO_ 2571108357 "False";
BA_ "GenMsgInstanced" BO_ 2571108358 "False";
BA_ "GenMsgCycleTime" BO_ 2483290116 100;
BA_ "GenMsgCycleTime" BO_ 2483290117 100;
BA_ "GenMsgCycleTime" BO_ 2483290118 100;
BA_ "GenMsgCycleTime" BO_ 2483290119 100;
BA_ "GenSigType" SG_ 2483290116 BATT_ArbitrationComplete_4 1;
BA_ "GenSigType" SG_ 2483290116 BATT_modStateRequested_4 0;
BA_ "GenSigType" SG_ 2483290116 BATT_prechargeState_4 0;
BA_ "GenSigType" SG_ 2483290116 BATT_fetPchgCommand_4 0;
BA_ "GenSigType" SG_ 2483290116 BATT_fetDsgCommand_4 0;
BA_ "GenSigType" SG_ 2483290116 BATT_fetChgCommand_4 0;
BA_ "GenSigType" SG_ 2483290116 BATT_fetDsgStatus_4 0;
BA_ "GenSigType" SG_ 2483290116 BATT_fetChgStatus_4 0;
BA_ "GenSigType" SG_ 2483290116 BATT_inhRegen_4 1;
BA_ "GenSigType" SG_ 2483290116 BATT_inhFullPower_4 1;
BA_ "GenSigType" SG_ 2483290116 BATT_inhDriveEntry_4 1;
BA_ "GenSigType" SG_ 2483290116 BATT_inhDrive_4 1;
BA_ "GenSigType" SG_ 2483290116 BATT_inhContPower_4 1;
BA_ "GenSigType" SG_ 2483290116 BATT_inhChargeEntry_4 1;
BA_ "GenSigType" SG_ 2483290116 BATT_inhCharge_4 1;
BA_ "GenSigType" SG_ 2483290116 BATT_modPackState_4 0;
BA_ "GenSigType" SG_ 2483290116 BATT_modChildState_4 0;
BA_ "GenSigType" SG_ 2483290116 BATT_modParentState_4 0;
BA_ "GenSigType" SG_ 2483290117 BATT_ArbitrationComplete_5 1;
BA_ "GenSigType" SG_ 2483290117 BATT_modStateRequested_5 0;
BA_ "GenSigType" SG_ 2483290117 BATT_prechargeState_5 0;
BA_ "GenSigType" SG_ 2483290117 BATT_fetPchgCommand_5 0;
BA_ "GenSigType" SG_ 2483290117 BATT_fetDsgCommand_5 0;
BA_ "GenSigType" SG_ 2483290117 BATT_fetChgCommand_5 0;
BA_ "GenSigType" SG_ 2483290117 BATT_fetDsgStatus_5 0;
BA_ "GenSigType" SG_ 2483290117 BATT_fetChgStatus_5 0;
BA_ "GenSigType" SG_ 2483290117 BATT_inhRegen_5 1;
BA_ "GenSigType" SG_ 2483290117 BATT_inhFullPower_5 1;
BA_ "GenSigType" SG_ 2483290117 BATT_inhDriveEntry_5 1;
BA_ "GenSigType" SG_ 2483290117 BATT_inhDrive_5 1;
BA_ "GenSigType" SG_ 2483290117 BATT_inhContPower_5 1;
BA_ "GenSigType" SG_ 2483290117 BATT_inhChargeEntry_5 1;
BA_ "GenSigType" SG_ 2483290117 BATT_inhCharge_5 1;
BA_ "GenSigType" SG_ 2483290117 BATT_modPackState_5 0;
BA_ "GenSigType" SG_ 2483290117 BATT_modChildState_5 0;
BA_ "GenSigType" SG_ 2483290117 BATT_modParentState_5 0;
BA_ "GenSigType" SG_ 2483290118 BATT_ArbitrationComplete_6 1;
BA_ "GenSigType" SG_ 2483290118 BATT_modStateRequested_6 0;
BA_ "GenSigType" SG_ 2483290118 BATT_prechargeState_6 0;
BA_ "GenSigType" SG_ 2483290118 BATT_fetPchgCommand_6 0;
BA_ "GenSigType" SG_ 2483290118 BATT_fetDsgCommand_6 0;
BA_ "GenSigType" SG_ 2483290118 BATT_fetChgCommand_6 0;
BA_ "GenSigType" SG_ 2483290118 BATT_fetDsgStatus_6 0;
BA_ "GenSigType" SG_ 2483290118 BATT_fetChgStatus_6 0;
BA_ "GenSigType" SG_ 2483290118 BATT_inhRegen_6 1;
BA_ "GenSigType" SG_ 2483290118 BATT_inhFullPower_6 1;
BA_ "GenSigType" SG_ 2483290118 BATT_inhDriveEntry_6 1;
BA_ "GenSigType" SG_ 2483290118 BATT_inhDrive_6 1;
BA_ "GenSigType" SG_ 2483290118 BATT_inhContPower_6 1;
BA_ "GenSigType" SG_ 2483290118 BATT_inhChargeEntry_6 1;
BA_ "GenSigType" SG_ 2483290118 BATT_inhCharge_6 1;
BA_ "GenSigType" SG_ 2483290118 BATT_modPackState_6 0;
BA_ "GenSigType" SG_ 2483290118 BATT_modChildState_6 0;
BA_ "GenSigType" SG_ 2483290118 BATT_modParentState_6 0;
BA_ "GenSigType" SG_ 2483290119 BATT_ArbitrationComplete_7 1;
BA_ "GenSigType" SG_ 2483290119 BATT_modStateRequested_7 0;
BA_ "GenSigType" SG_ 2483290119 BATT_prechargeState_7 0;
BA_ "GenSigType" SG_ 2483290119 BATT_fetPchgCommand_7 0;
BA_ "GenSigType" SG_ 2483290119 BATT_fetDsgCommand_7 0;
BA_ "GenSigType" SG_ 2483290119 BATT_fetChgCommand_7 0;
BA_ "GenSigType" SG_ 2483290119 BATT_fetDsgStatus_7 0;
BA_ "GenSigType" SG_ 2483290119 BATT_fetChgStatus_7 0;
BA_ "GenSigType" SG_ 2483290119 BATT_inhRegen_7 1;
BA_ "GenSigType" SG_ 2483290119 BATT_inhFullPower_7 1;
BA_ "GenSigType" SG_ 2483290119 BATT_inhDriveEntry_7 1;
BA_ "GenSigType" SG_ 2483290119 BATT_inhDrive_7 1;
BA_ "GenSigType" SG_ 2483290119 BATT_inhContPower_7 1;
BA_ "GenSigType" SG_ 2483290119 BATT_inhChargeEntry_7 1;
BA_ "GenSigType" SG_ 2483290119 BATT_inhCharge_7 1;
BA_ "GenSigType" SG_ 2483290119 BATT_modPackState_7 0;
BA_ "GenSigType" SG_ 2483290119 BATT_modChildState_7 0;
BA_ "GenSigType" SG_ 2483290119 BATT_modParentState_7 0;
BA_ "GenSigType" SG_ 2508193792 BATT_bootloaderMinor_bootup_0 0;
BA_ "GenSigType" SG_ 2508193792 BATT_bootloaderMajor_bootup_0 0;
BA_ "GenSigType" SG_ 2508193792 BATT_bootloaderRevision_bootup_0 0;
BA_ "GenSigType" SG_ 2508193792 BATT_appMajor_bootup_0 0;
BA_ "GenSigType" SG_ 2508193792 BATT_appMinor_bootup_0 0;
BA_ "GenSigType" SG_ 2508193792 BATT_appRevision_bootup_0 0;
BA_ "GenSigType" SG_ 2508193793 BATT_bootloaderMinor_bootup_1 0;
BA_ "GenSigType" SG_ 2508193793 BATT_bootloaderRevision_bootup_1 0;
BA_ "GenSigType" SG_ 2508193793 BATT_bootloaderMajor_bootup_1 0;
BA_ "GenSigType" SG_ 2508193793 BATT_appMinor_bootup_1 0;
BA_ "GenSigType" SG_ 2508193793 BATT_appMajor_bootup_1 0;
BA_ "GenSigType" SG_ 2508193793 BATT_appRevision_bootup_1 0;
BA_ "GenSigType" SG_ 2508193794 BATT_appMinor_bootup_2 0;
BA_ "GenSigType" SG_ 2508193794 BATT_appRevision_bootup_2 0;
BA_ "GenSigType" SG_ 2508193794 BATT_bootloaderMajor_bootup_2 0;
BA_ "GenSigType" SG_ 2508193794 BATT_bootloaderRevision_bootup_2 0;
BA_ "GenSigType" SG_ 2508193794 BATT_bootloaderMinor_bootup_2 0;
BA_ "GenSigType" SG_ 2508193794 BATT_appMajor_bootup_2 0;
BA_ "GenSigType" SG_ 2508193795 BATT_appMajor_bootup_3 0;
BA_ "GenSigType" SG_ 2508193795 BATT_appRevision_bootup_3 0;
BA_ "GenSigType" SG_ 2508193795 BATT_appMinor_bootup_3 0;
BA_ "GenSigType" SG_ 2508193795 BATT_bootloaderMinor_bootup_3 0;
BA_ "GenSigType" SG_ 2508193795 BATT_bootloaderMajor_bootup_3 0;
BA_ "GenSigType" SG_ 2508193795 BATT_bootloaderRevision_bootup_3 0;
BA_ "GenSigType" SG_ 2508193796 BATT_bootloaderMajor_bootup_4 0;
BA_ "GenSigType" SG_ 2508193796 BATT_appRevision_bootup_4 0;
BA_ "GenSigType" SG_ 2508193796 BATT_appMinor_bootup_4 0;
BA_ "GenSigType" SG_ 2508193796 BATT_bootloaderMinor_bootup_4 0;
BA_ "GenSigType" SG_ 2508193796 BATT_bootloaderRevision_bootup_4 0;
BA_ "GenSigType" SG_ 2508193796 BATT_appMajor_bootup_4 0;
BA_ "GenSigType" SG_ 2508193797 BATT_bootloaderMajor_bootup_5 0;
BA_ "GenSigType" SG_ 2508193797 BATT_appMinor_bootup_5 0;
BA_ "GenSigType" SG_ 2508193797 BATT_appMajor_bootup_5 0;
BA_ "GenSigType" SG_ 2508193797 BATT_bootloaderMinor_bootup_5 0;
BA_ "GenSigType" SG_ 2508193797 BATT_appRevision_bootup_5 0;
BA_ "GenSigType" SG_ 2508193797 BATT_bootloaderRevision_bootup_5 0;
BA_ "GenSigType" SG_ 2508193798 BATT_appRevision_bootup_6 0;
BA_ "GenSigType" SG_ 2508193798 BATT_bootloaderRevision_bootup_6 0;
BA_ "GenSigType" SG_ 2508193798 BATT_bootloaderMajor_bootup_6 0;
BA_ "GenSigType" SG_ 2508193798 BATT_bootloaderMinor_bootup_6 0;
BA_ "GenSigType" SG_ 2508193798 BATT_appMinor_bootup_6 0;
BA_ "GenSigType" SG_ 2508193798 BATT_appMajor_bootup_6 0;
BA_ "GenSigType" SG_ 2508193799 BATT_bootloaderMinor_bootup_7 0;
BA_ "GenSigType" SG_ 2508193799 BATT_bootloaderRevision_bootup_7 0;
BA_ "GenSigType" SG_ 2508193799 BATT_appMajor_bootup_7 0;
BA_ "GenSigType" SG_ 2508193799 BATT_appMinor_bootup_7 0;
BA_ "GenSigType" SG_ 2508193799 BATT_appRevision_bootup_7 0;
BA_ "GenSigType" SG_ 2508193799 BATT_bootloaderMajor_bootup_7 0;
BA_ "GenSigType" SG_ 2550661120 BATT_IGNLO_Status_0 1;
BA_ "GenSigType" SG_ 2550661121 BATT_IGNLO_Status_1 1;
BA_ "GenSigType" SG_ 2550661122 BATT_IGNLO_Status_2 1;
BA_ "GenSigType" SG_ 2550661123 BATT_IGNLO_Status_3 1;
BA_ "GenSigType" SG_ 2550661124 BATT_IGNLO_Status_4 1;
BA_ "GenSigType" SG_ 2550661125 BATT_IGNLO_Status_5 1;
BA_ "GenSigType" SG_ 2550661126 BATT_IGNLO_Status_6 1;
BA_ "GenSigType" SG_ 2550661127 BATT_IGNLO_Status_7 1;
BA_ "GenSigType" SG_ 2571108352 BATT_packModIdFault_0 1;
BA_ "GenSigType" SG_ 2571108352 BATT_packModExitedFromBus_0 1;
BA_ "GenSigType" SG_ 2571108352 BATT_packFetChgWelded_0 1;
BA_ "GenSigType" SG_ 2571108352 BATT_packFetDsgWelded_0 1;
BA_ "GenSigType" SG_ 2571108352 BATT_fetDsgShortedAux_0 1;
BA_ "GenSigType" SG_ 2571108352 BATT_fetChgShortedAux_0 1;
BA_ "GenSigType" SG_ 2571108352 BATT_prechargeFetFail_0 1;
BA_ "GenSigType" SG_ 2571108352 BATT_abnormalResetReason_0 1;
BA_ "GenSigType" SG_ 2571108352 BATT_prechargeTooSlow_0 1;
BA_ "GenSigType" SG_ 2571108352 BATT_prechargeTooFast_0 1;
BA_ "GenSigType" SG_ 2571108352 BATT_prechargeTimeout_0 1;
BA_ "GenSigType" SG_ 2571108352 BATT_fetChgShorted_0 1;
BA_ "GenSigType" SG_ 2571108352 BATT_fetChgFailToClose_0 1;
BA_ "GenSigType" SG_ 2571108352 BATT_packModSelectFault_0 1;
BA_ "GenSigType" SG_ 2571108352 BATT_packModConnectFault_0 1;
BA_ "GenSigType" SG_ 2571108352 BATT_packModMIA_0 1;
BA_ "GenSigType" SG_ 2571108352 BATT_packModImbalance_0 1;
BA_ "GenSigType" SG_ 2571108352 BATT_afeFault_0 1;
BA_ "GenSigType" SG_ 2571108352 BATT_chargerMIA_0 1;
BA_ "GenSigType" SG_ 2571108352 BATT_chargerError_0 1;
BA_ "GenSigType" SG_ 2571108352 BATT_vBrickUnderWar_0 1;
BA_ "GenSigType" SG_ 2571108352 BATT_vBrickUnderSev_0 1;
BA_ "GenSigType" SG_ 2571108352 BATT_vBrickUnderMod_0 1;
BA_ "GenSigType" SG_ 2571108352 BATT_vBrickOverWar_0 1;
BA_ "GenSigType" SG_ 2571108352 BATT_vBrickOverSev_0 1;
BA_ "GenSigType" SG_ 2571108352 BATT_vBrickOverMod_0 1;
BA_ "GenSigType" SG_ 2571108352 BATT_vBrickImbalance_0 1;
BA_ "GenSigType" SG_ 2571108352 BATT_loggerAlmostFull_0 1;
BA_ "GenSigType" SG_ 2571108352 BATT_tempModuleUnderWar_0 1;
BA_ "GenSigType" SG_ 2571108352 BATT_tempModuleUnderSev_0 1;
BA_ "GenSigType" SG_ 2571108352 BATT_tempModuleUnderMod_0 1;
BA_ "GenSigType" SG_ 2571108352 BATT_tempModuleOverWar_0 1;
BA_ "GenSigType" SG_ 2571108352 BATT_tempModuleOverSev_0 1;
BA_ "GenSigType" SG_ 2571108352 BATT_tempModuleOverMod_0 1;
BA_ "GenSigType" SG_ 2571108352 BATT_tempBrickImbalance_0 1;
BA_ "GenSigType" SG_ 2571108352 BATT_taskLockupError_0 1;
BA_ "GenSigType" SG_ 2571108352 BATT_tempAmbientOverWar_0 1;
BA_ "GenSigType" SG_ 2571108352 BATT_tempAmbientOverSev_0 1;
BA_ "GenSigType" SG_ 2571108352 BATT_tempAmbientOverMod_0 1;
BA_ "GenSigType" SG_ 2571108352 BATT_sensePackVoltError_0 1;
BA_ "GenSigType" SG_ 2571108352 BATT_senseLoadVoltError_0 1;
BA_ "GenSigType" SG_ 2571108352 BATT_loggerFull_0 1;
BA_ "GenSigType" SG_ 2571108352 BATT_senseCurrentError_0 1;
BA_ "GenSigType" SG_ 2571108352 BATT_senseBrickTempError_0 1;
BA_ "GenSigType" SG_ 2571108352 BATT_resPackHigh_0 1;
BA_ "GenSigType" SG_ 2571108352 BATT_ramOverUtilError_0 1;
BA_ "GenSigType" SG_ 2571108352 BATT_powerPackInsufficient_0 1;
BA_ "GenSigType" SG_ 2571108352 BATT_packCellSoftShort_0 1;
BA_ "GenSigType" SG_ 2571108352 BATT_iOverHardware_0 1;
BA_ "GenSigType" SG_ 2571108352 BATT_fetOverTemp_0 1;
BA_ "GenSigType" SG_ 2571108352 BATT_iOverDischarge_0 1;
BA_ "GenSigType" SG_ 2571108352 BATT_iOverCharge_0 1;
BA_ "GenSigType" SG_ 2571108352 BATT_inverterDriveMIA_0 1;
BA_ "GenSigType" SG_ 2571108352 BATT_iUnderCharge_0 1;
BA_ "GenSigType" SG_ 2571108352 BATT_hostMIA_0 1;
BA_ "GenSigType" SG_ 2571108352 BATT_fetDsgShorted_0 1;
BA_ "GenSigType" SG_ 2571108352 BATT_fetDsgFailToClose_0 1;
BA_ "GenSigType" SG_ 2571108352 BATT_capLow_0 1;
BA_ "GenSigType" SG_ 2571108352 BATT_brickOverDischarge_0 1;
BA_ "GenSigType" SG_ 2571108352 BATT_brickOverCharge_0 1;
BA_ "GenSigType" SG_ 2571108352 BATT_bmsProcessorError_0 1;
BA_ "GenSigType" SG_ 2571108352 BATT_bmsMemoryError_0 1;
BA_ "GenSigType" SG_ 2571108352 BATT_afeError_0 1;
BA_ "GenSigType" SG_ 2571108353 BATT_packModIdFault_1 1;
BA_ "GenSigType" SG_ 2571108353 BATT_packModExitedFromBus_1 1;
BA_ "GenSigType" SG_ 2571108353 BATT_packFetChgWelded_1 1;
BA_ "GenSigType" SG_ 2571108353 BATT_packFetDsgWelded_1 1;
BA_ "GenSigType" SG_ 2571108353 BATT_fetDsgShortedAux_1 1;
BA_ "GenSigType" SG_ 2571108353 BATT_fetChgShortedAux_1 1;
BA_ "GenSigType" SG_ 2571108353 BATT_prechargeFetFail_1 1;
BA_ "GenSigType" SG_ 2571108353 BATT_abnormalResetReason_1 1;
BA_ "GenSigType" SG_ 2571108353 BATT_prechargeTooSlow_1 1;
BA_ "GenSigType" SG_ 2571108353 BATT_prechargeTooFast_1 1;
BA_ "GenSigType" SG_ 2571108353 BATT_prechargeTimeout_1 1;
BA_ "GenSigType" SG_ 2571108353 BATT_fetChgShorted_1 1;
BA_ "GenSigType" SG_ 2571108353 BATT_fetChgFailToClose_1 1;
BA_ "GenSigType" SG_ 2571108353 BATT_packModSelectFault_1 1;
BA_ "GenSigType" SG_ 2571108353 BATT_packModConnectFault_1 1;
BA_ "GenSigType" SG_ 2571108353 BATT_packModMIA_1 1;
BA_ "GenSigType" SG_ 2571108353 BATT_packModImbalance_1 1;
BA_ "GenSigType" SG_ 2571108353 BATT_afeFault_1 1;
BA_ "GenSigType" SG_ 2571108353 BATT_chargerMIA_1 1;
BA_ "GenSigType" SG_ 2571108353 BATT_chargerError_1 1;
BA_ "GenSigType" SG_ 2571108353 BATT_vBrickUnderWar_1 1;
BA_ "GenSigType" SG_ 2571108353 BATT_vBrickUnderSev_1 1;
BA_ "GenSigType" SG_ 2571108353 BATT_vBrickUnderMod_1 1;
BA_ "GenSigType" SG_ 2571108353 BATT_vBrickOverWar_1 1;
BA_ "GenSigType" SG_ 2571108353 BATT_vBrickOverSev_1 1;
BA_ "GenSigType" SG_ 2571108353 BATT_vBrickOverMod_1 1;
BA_ "GenSigType" SG_ 2571108353 BATT_vBrickImbalance_1 1;
BA_ "GenSigType" SG_ 2571108353 BATT_loggerAlmostFull_1 1;
BA_ "GenSigType" SG_ 2571108353 BATT_tempModuleUnderWar_1 1;
BA_ "GenSigType" SG_ 2571108353 BATT_tempModuleUnderSev_1 1;
BA_ "GenSigType" SG_ 2571108353 BATT_tempModuleUnderMod_1 1;
BA_ "GenSigType" SG_ 2571108353 BATT_tempModuleOverWar_1 1;
BA_ "GenSigType" SG_ 2571108353 BATT_tempModuleOverSev_1 1;
BA_ "GenSigType" SG_ 2571108353 BATT_tempModuleOverMod_1 1;
BA_ "GenSigType" SG_ 2571108353 BATT_tempBrickImbalance_1 1;
BA_ "GenSigType" SG_ 2571108353 BATT_taskLockupError_1 1;
BA_ "GenSigType" SG_ 2571108353 BATT_tempAmbientOverWar_1 1;
BA_ "GenSigType" SG_ 2571108353 BATT_tempAmbientOverSev_1 1;
BA_ "GenSigType" SG_ 2571108353 BATT_tempAmbientOverMod_1 1;
BA_ "GenSigType" SG_ 2571108353 BATT_sensePackVoltError_1 1;
BA_ "GenSigType" SG_ 2571108353 BATT_senseLoadVoltError_1 1;
BA_ "GenSigType" SG_ 2571108353 BATT_loggerFull_1 1;
BA_ "GenSigType" SG_ 2571108353 BATT_senseCurrentError_1 1;
BA_ "GenSigType" SG_ 2571108353 BATT_senseBrickTempError_1 1;
BA_ "GenSigType" SG_ 2571108353 BATT_resPackHigh_1 1;
BA_ "GenSigType" SG_ 2571108353 BATT_ramOverUtilError_1 1;
BA_ "GenSigType" SG_ 2571108353 BATT_powerPackInsufficient_1 1;
BA_ "GenSigType" SG_ 2571108353 BATT_packCellSoftShort_1 1;
BA_ "GenSigType" SG_ 2571108353 BATT_iOverHardware_1 1;
BA_ "GenSigType" SG_ 2571108353 BATT_fetOverTemp_1 1;
BA_ "GenSigType" SG_ 2571108353 BATT_iOverDischarge_1 1;
BA_ "GenSigType" SG_ 2571108353 BATT_iOverCharge_1 1;
BA_ "GenSigType" SG_ 2571108353 BATT_inverterDriveMIA_1 1;
BA_ "GenSigType" SG_ 2571108353 BATT_iUnderCharge_1 1;
BA_ "GenSigType" SG_ 2571108353 BATT_hostMIA_1 1;
BA_ "GenSigType" SG_ 2571108353 BATT_fetDsgShorted_1 1;
BA_ "GenSigType" SG_ 2571108353 BATT_fetDsgFailToClose_1 1;
BA_ "GenSigType" SG_ 2571108353 BATT_capLow_1 1;
BA_ "GenSigType" SG_ 2571108353 BATT_brickOverDischarge_1 1;
BA_ "GenSigType" SG_ 2571108353 BATT_brickOverCharge_1 1;
BA_ "GenSigType" SG_ 2571108353 BATT_bmsProcessorError_1 1;
BA_ "GenSigType" SG_ 2571108353 BATT_bmsMemoryError_1 1;
BA_ "GenSigType" SG_ 2571108353 BATT_afeError_1 1;
BA_ "GenSigType" SG_ 2571108354 BATT_packModIdFault_2 1;
BA_ "GenSigType" SG_ 2571108354 BATT_packModExitedFromBus_2 1;
BA_ "GenSigType" SG_ 2571108354 BATT_packFetChgWelded_2 1;
BA_ "GenSigType" SG_ 2571108354 BATT_packFetDsgWelded_2 1;
BA_ "GenSigType" SG_ 2571108354 BATT_fetDsgShortedAux_2 1;
BA_ "GenSigType" SG_ 2571108354 BATT_fetChgShortedAux_2 1;
BA_ "GenSigType" SG_ 2571108354 BATT_prechargeFetFail_2 1;
BA_ "GenSigType" SG_ 2571108354 BATT_abnormalResetReason_2 1;
BA_ "GenSigType" SG_ 2571108354 BATT_prechargeTooSlow_2 1;
BA_ "GenSigType" SG_ 2571108354 BATT_prechargeTooFast_2 1;
BA_ "GenSigType" SG_ 2571108354 BATT_prechargeTimeout_2 1;
BA_ "GenSigType" SG_ 2571108354 BATT_fetChgShorted_2 1;
BA_ "GenSigType" SG_ 2571108354 BATT_fetChgFailToClose_2 1;
BA_ "GenSigType" SG_ 2571108354 BATT_packModSelectFault_2 1;
BA_ "GenSigType" SG_ 2571108354 BATT_packModConnectFault_2 1;
BA_ "GenSigType" SG_ 2571108354 BATT_packModMIA_2 1;
BA_ "GenSigType" SG_ 2571108354 BATT_packModImbalance_2 1;
BA_ "GenSigType" SG_ 2571108354 BATT_afeFault_2 1;
BA_ "GenSigType" SG_ 2571108354 BATT_chargerMIA_2 1;
BA_ "GenSigType" SG_ 2571108354 BATT_chargerError_2 1;
BA_ "GenSigType" SG_ 2571108354 BATT_vBrickUnderWar_2 1;
BA_ "GenSigType" SG_ 2571108354 BATT_vBrickUnderSev_2 1;
BA_ "GenSigType" SG_ 2571108354 BATT_vBrickUnderMod_2 1;
BA_ "GenSigType" SG_ 2571108354 BATT_vBrickOverWar_2 1;
BA_ "GenSigType" SG_ 2571108354 BATT_vBrickOverSev_2 1;
BA_ "GenSigType" SG_ 2571108354 BATT_vBrickOverMod_2 1;
BA_ "GenSigType" SG_ 2571108354 BATT_vBrickImbalance_2 1;
BA_ "GenSigType" SG_ 2571108354 BATT_loggerAlmostFull_2 1;
BA_ "GenSigType" SG_ 2571108354 BATT_tempModuleUnderWar_2 1;
BA_ "GenSigType" SG_ 2571108354 BATT_tempModuleUnderSev_2 1;
BA_ "GenSigType" SG_ 2571108354 BATT_tempModuleUnderMod_2 1;
BA_ "GenSigType" SG_ 2571108354 BATT_tempModuleOverWar_2 1;
BA_ "GenSigType" SG_ 2571108354 BATT_tempModuleOverSev_2 1;
BA_ "GenSigType" SG_ 2571108354 BATT_tempModuleOverMod_2 1;
BA_ "GenSigType" SG_ 2571108354 BATT_tempBrickImbalance_2 1;
BA_ "GenSigType" SG_ 2571108354 BATT_taskLockupError_2 1;
BA_ "GenSigType" SG_ 2571108354 BATT_tempAmbientOverWar_2 1;
BA_ "GenSigType" SG_ 2571108354 BATT_tempAmbientOverSev_2 1;
BA_ "GenSigType" SG_ 2571108354 BATT_tempAmbientOverMod_2 1;
BA_ "GenSigType" SG_ 2571108354 BATT_sensePackVoltError_2 1;
BA_ "GenSigType" SG_ 2571108354 BATT_senseLoadVoltError_2 1;
BA_ "GenSigType" SG_ 2571108354 BATT_loggerFull_2 1;
BA_ "GenSigType" SG_ 2571108354 BATT_senseCurrentError_2 1;
BA_ "GenSigType" SG_ 2571108354 BATT_senseBrickTempError_2 1;
BA_ "GenSigType" SG_ 2571108354 BATT_resPackHigh_2 1;
BA_ "GenSigType" SG_ 2571108354 BATT_ramOverUtilError_2 1;
BA_ "GenSigType" SG_ 2571108354 BATT_powerPackInsufficient_2 1;
BA_ "GenSigType" SG_ 2571108354 BATT_packCellSoftShort_2 1;
BA_ "GenSigType" SG_ 2571108354 BATT_iOverHardware_2 1;
BA_ "GenSigType" SG_ 2571108354 BATT_fetOverTemp_2 1;
BA_ "GenSigType" SG_ 2571108354 BATT_iOverDischarge_2 1;
BA_ "GenSigType" SG_ 2571108354 BATT_iOverCharge_2 1;
BA_ "GenSigType" SG_ 2571108354 BATT_inverterDriveMIA_2 1;
BA_ "GenSigType" SG_ 2571108354 BATT_iUnderCharge_2 1;
BA_ "GenSigType" SG_ 2571108354 BATT_hostMIA_2 1;
BA_ "GenSigType" SG_ 2571108354 BATT_fetDsgShorted_2 1;
BA_ "GenSigType" SG_ 2571108354 BATT_fetDsgFailToClose_2 1;
BA_ "GenSigType" SG_ 2571108354 BATT_capLow_2 1;
BA_ "GenSigType" SG_ 2571108354 BATT_brickOverDischarge_2 1;
BA_ "GenSigType" SG_ 2571108354 BATT_brickOverCharge_2 1;
BA_ "GenSigType" SG_ 2571108354 BATT_bmsProcessorError_2 1;
BA_ "GenSigType" SG_ 2571108354 BATT_bmsMemoryError_2 1;
BA_ "GenSigType" SG_ 2571108354 BATT_afeError_2 1;
BA_ "GenSigType" SG_ 2571108355 BATT_packModIdFault_3 1;
BA_ "GenSigType" SG_ 2571108355 BATT_packModExitedFromBus_3 1;
BA_ "GenSigType" SG_ 2571108355 BATT_packFetChgWelded_3 1;
BA_ "GenSigType" SG_ 2571108355 BATT_packFetDsgWelded_3 1;
BA_ "GenSigType" SG_ 2571108355 BATT_fetDsgShortedAux_3 1;
BA_ "GenSigType" SG_ 2571108355 BATT_fetChgShortedAux_3 1;
BA_ "GenSigType" SG_ 2571108355 BATT_prechargeFetFail_3 1;
BA_ "GenSigType" SG_ 2571108355 BATT_abnormalResetReason_3 1;
BA_ "GenSigType" SG_ 2571108355 BATT_prechargeTooSlow_3 1;
BA_ "GenSigType" SG_ 2571108355 BATT_prechargeTooFast_3 1;
BA_ "GenSigType" SG_ 2571108355 BATT_prechargeTimeout_3 1;
BA_ "GenSigType" SG_ 2571108355 BATT_fetChgShorted_3 1;
BA_ "GenSigType" SG_ 2571108355 BATT_fetChgFailToClose_3 1;
BA_ "GenSigType" SG_ 2571108355 BATT_packModSelectFault_3 1;
BA_ "GenSigType" SG_ 2571108355 BATT_packModConnectFault_3 1;
BA_ "GenSigType" SG_ 2571108355 BATT_packModMIA_3 1;
BA_ "GenSigType" SG_ 2571108355 BATT_packModImbalance_3 1;
BA_ "GenSigType" SG_ 2571108355 BATT_afeFault_3 1;
BA_ "GenSigType" SG_ 2571108355 BATT_chargerMIA_3 1;
BA_ "GenSigType" SG_ 2571108355 BATT_chargerError_3 1;
BA_ "GenSigType" SG_ 2571108355 BATT_vBrickUnderWar_3 1;
BA_ "GenSigType" SG_ 2571108355 BATT_vBrickUnderSev_3 1;
BA_ "GenSigType" SG_ 2571108355 BATT_vBrickUnderMod_3 1;
BA_ "GenSigType" SG_ 2571108355 BATT_vBrickOverWar_3 1;
BA_ "GenSigType" SG_ 2571108355 BATT_vBrickOverSev_3 1;
BA_ "GenSigType" SG_ 2571108355 BATT_vBrickOverMod_3 1;
BA_ "GenSigType" SG_ 2571108355 BATT_vBrickImbalance_3 1;
BA_ "GenSigType" SG_ 2571108355 BATT_loggerAlmostFull_3 1;
BA_ "GenSigType" SG_ 2571108355 BATT_tempModuleUnderWar_3 1;
BA_ "GenSigType" SG_ 2571108355 BATT_tempModuleUnderSev_3 1;
BA_ "GenSigType" SG_ 2571108355 BATT_tempModuleUnderMod_3 1;
BA_ "GenSigType" SG_ 2571108355 BATT_tempModuleOverWar_3 1;
BA_ "GenSigType" SG_ 2571108355 BATT_tempModuleOverSev_3 1;
BA_ "GenSigType" SG_ 2571108355 BATT_tempModuleOverMod_3 1;
BA_ "GenSigType" SG_ 2571108355 BATT_tempBrickImbalance_3 1;
BA_ "GenSigType" SG_ 2571108355 BATT_taskLockupError_3 1;
BA_ "GenSigType" SG_ 2571108355 BATT_tempAmbientOverWar_3 1;
BA_ "GenSigType" SG_ 2571108355 BATT_tempAmbientOverSev_3 1;
BA_ "GenSigType" SG_ 2571108355 BATT_tempAmbientOverMod_3 1;
BA_ "GenSigType" SG_ 2571108355 BATT_sensePackVoltError_3 1;
BA_ "GenSigType" SG_ 2571108355 BATT_senseLoadVoltError_3 1;
BA_ "GenSigType" SG_ 2571108355 BATT_loggerFull_3 1;
BA_ "GenSigType" SG_ 2571108355 BATT_senseCurrentError_3 1;
BA_ "GenSigType" SG_ 2571108355 BATT_senseBrickTempError_3 1;
BA_ "GenSigType" SG_ 2571108355 BATT_resPackHigh_3 1;
BA_ "GenSigType" SG_ 2571108355 BATT_ramOverUtilError_3 1;
BA_ "GenSigType" SG_ 2571108355 BATT_powerPackInsufficient_3 1;
BA_ "GenSigType" SG_ 2571108355 BATT_packCellSoftShort_3 1;
BA_ "GenSigType" SG_ 2571108355 BATT_iOverHardware_3 1;
BA_ "GenSigType" SG_ 2571108355 BATT_fetOverTemp_3 1;
BA_ "GenSigType" SG_ 2571108355 BATT_iOverDischarge_3 1;
BA_ "GenSigType" SG_ 2571108355 BATT_iOverCharge_3 1;
BA_ "GenSigType" SG_ 2571108355 BATT_inverterDriveMIA_3 1;
BA_ "GenSigType" SG_ 2571108355 BATT_iUnderCharge_3 1;
BA_ "GenSigType" SG_ 2571108355 BATT_hostMIA_3 1;
BA_ "GenSigType" SG_ 2571108355 BATT_fetDsgShorted_3 1;
BA_ "GenSigType" SG_ 2571108355 BATT_fetDsgFailToClose_3 1;
BA_ "GenSigType" SG_ 2571108355 BATT_capLow_3 1;
BA_ "GenSigType" SG_ 2571108355 BATT_brickOverDischarge_3 1;
BA_ "GenSigType" SG_ 2571108355 BATT_brickOverCharge_3 1;
BA_ "GenSigType" SG_ 2571108355 BATT_bmsProcessorError_3 1;
BA_ "GenSigType" SG_ 2571108355 BATT_bmsMemoryError_3 1;
BA_ "GenSigType" SG_ 2571108355 BATT_afeError_3 1;
BA_ "GenSigType" SG_ 2571108356 BATT_packModIdFault_4 1;
BA_ "GenSigType" SG_ 2571108356 BATT_packModExitedFromBus_4 1;
BA_ "GenSigType" SG_ 2571108356 BATT_packFetChgWelded_4 1;
BA_ "GenSigType" SG_ 2571108356 BATT_packFetDsgWelded_4 1;
BA_ "GenSigType" SG_ 2571108356 BATT_fetDsgShortedAux_4 1;
BA_ "GenSigType" SG_ 2571108356 BATT_fetChgShortedAux_4 1;
BA_ "GenSigType" SG_ 2571108356 BATT_prechargeFetFail_4 1;
BA_ "GenSigType" SG_ 2571108356 BATT_abnormalResetReason_4 1;
BA_ "GenSigType" SG_ 2571108356 BATT_prechargeTooSlow_4 1;
BA_ "GenSigType" SG_ 2571108356 BATT_prechargeTooFast_4 1;
BA_ "GenSigType" SG_ 2571108356 BATT_prechargeTimeout_4 1;
BA_ "GenSigType" SG_ 2571108356 BATT_fetChgShorted_4 1;
BA_ "GenSigType" SG_ 2571108356 BATT_fetChgFailToClose_4 1;
BA_ "GenSigType" SG_ 2571108356 BATT_packModSelectFault_4 1;
BA_ "GenSigType" SG_ 2571108356 BATT_packModConnectFault_4 1;
BA_ "GenSigType" SG_ 2571108356 BATT_packModMIA_4 1;
BA_ "GenSigType" SG_ 2571108356 BATT_packModImbalance_4 1;
BA_ "GenSigType" SG_ 2571108356 BATT_afeFault_4 1;
BA_ "GenSigType" SG_ 2571108356 BATT_chargerMIA_4 1;
BA_ "GenSigType" SG_ 2571108356 BATT_chargerError_4 1;
BA_ "GenSigType" SG_ 2571108356 BATT_vBrickUnderWar_4 1;
BA_ "GenSigType" SG_ 2571108356 BATT_vBrickUnderSev_4 1;
BA_ "GenSigType" SG_ 2571108356 BATT_vBrickUnderMod_4 1;
BA_ "GenSigType" SG_ 2571108356 BATT_vBrickOverWar_4 1;
BA_ "GenSigType" SG_ 2571108356 BATT_vBrickOverSev_4 1;
BA_ "GenSigType" SG_ 2571108356 BATT_vBrickOverMod_4 1;
BA_ "GenSigType" SG_ 2571108356 BATT_vBrickImbalance_4 1;
BA_ "GenSigType" SG_ 2571108356 BATT_loggerAlmostFull_4 1;
BA_ "GenSigType" SG_ 2571108356 BATT_tempModuleUnderWar_4 1;
BA_ "GenSigType" SG_ 2571108356 BATT_tempModuleUnderSev_4 1;
BA_ "GenSigType" SG_ 2571108356 BATT_tempModuleUnderMod_4 1;
BA_ "GenSigType" SG_ 2571108356 BATT_tempModuleOverWar_4 1;
BA_ "GenSigType" SG_ 2571108356 BATT_tempModuleOverSev_4 1;
BA_ "GenSigType" SG_ 2571108356 BATT_tempModuleOverMod_4 1;
BA_ "GenSigType" SG_ 2571108356 BATT_tempBrickImbalance_4 1;
BA_ "GenSigType" SG_ 2571108356 BATT_taskLockupError_4 1;
BA_ "GenSigType" SG_ 2571108356 BATT_tempAmbientOverWar_4 1;
BA_ "GenSigType" SG_ 2571108356 BATT_tempAmbientOverSev_4 1;
BA_ "GenSigType" SG_ 2571108356 BATT_tempAmbientOverMod_4 1;
BA_ "GenSigType" SG_ 2571108356 BATT_sensePackVoltError_4 1;
BA_ "GenSigType" SG_ 2571108356 BATT_senseLoadVoltError_4 1;
BA_ "GenSigType" SG_ 2571108356 BATT_loggerFull_4 1;
BA_ "GenSigType" SG_ 2571108356 BATT_senseCurrentError_4 1;
BA_ "GenSigType" SG_ 2571108356 BATT_senseBrickTempError_4 1;
BA_ "GenSigType" SG_ 2571108356 BATT_resPackHigh_4 1;
BA_ "GenSigType" SG_ 2571108356 BATT_ramOverUtilError_4 1;
BA_ "GenSigType" SG_ 2571108356 BATT_powerPackInsufficient_4 1;
BA_ "GenSigType" SG_ 2571108356 BATT_packCellSoftShort_4 1;
BA_ "GenSigType" SG_ 2571108356 BATT_iOverHardware_4 1;
BA_ "GenSigType" SG_ 2571108356 BATT_fetOverTemp_4 1;
BA_ "GenSigType" SG_ 2571108356 BATT_iOverDischarge_4 1;
BA_ "GenSigType" SG_ 2571108356 BATT_iOverCharge_4 1;
BA_ "GenSigType" SG_ 2571108356 BATT_inverterDriveMIA_4 1;
BA_ "GenSigType" SG_ 2571108356 BATT_iUnderCharge_4 1;
BA_ "GenSigType" SG_ 2571108356 BATT_hostMIA_4 1;
BA_ "GenSigType" SG_ 2571108356 BATT_fetDsgShorted_4 1;
BA_ "GenSigType" SG_ 2571108356 BATT_fetDsgFailToClose_4 1;
BA_ "GenSigType" SG_ 2571108356 BATT_capLow_4 1;
BA_ "GenSigType" SG_ 2571108356 BATT_brickOverDischarge_4 1;
BA_ "GenSigType" SG_ 2571108356 BATT_brickOverCharge_4 1;
BA_ "GenSigType" SG_ 2571108356 BATT_bmsProcessorError_4 1;
BA_ "GenSigType" SG_ 2571108356 BATT_bmsMemoryError_4 1;
BA_ "GenSigType" SG_ 2571108356 BATT_afeError_4 1;
BA_ "GenSigType" SG_ 2571108357 BATT_packModIdFault_5 1;
BA_ "GenSigType" SG_ 2571108357 BATT_packModExitedFromBus_5 1;
BA_ "GenSigType" SG_ 2571108357 BATT_packFetChgWelded_5 1;
BA_ "GenSigType" SG_ 2571108357 BATT_packFetDsgWelded_5 1;
BA_ "GenSigType" SG_ 2571108357 BATT_fetDsgShortedAux_5 1;
BA_ "GenSigType" SG_ 2571108357 BATT_fetChgShortedAux_5 1;
BA_ "GenSigType" SG_ 2571108357 BATT_prechargeFetFail_5 1;
BA_ "GenSigType" SG_ 2571108357 BATT_abnormalResetReason_5 1;
BA_ "GenSigType" SG_ 2571108357 BATT_prechargeTooSlow_5 1;
BA_ "GenSigType" SG_ 2571108357 BATT_prechargeTooFast_5 1;
BA_ "GenSigType" SG_ 2571108357 BATT_prechargeTimeout_5 1;
BA_ "GenSigType" SG_ 2571108357 BATT_fetChgShorted_5 1;
BA_ "GenSigType" SG_ 2571108357 BATT_fetChgFailToClose_5 1;
BA_ "GenSigType" SG_ 2571108357 BATT_packModSelectFault_5 1;
BA_ "GenSigType" SG_ 2571108357 BATT_packModConnectFault_5 1;
BA_ "GenSigType" SG_ 2571108357 BATT_packModMIA_5 1;
BA_ "GenSigType" SG_ 2571108357 BATT_packModImbalance_5 1;
BA_ "GenSigType" SG_ 2571108357 BATT_afeFault_5 1;
BA_ "GenSigType" SG_ 2571108357 BATT_chargerMIA_5 1;
BA_ "GenSigType" SG_ 2571108357 BATT_chargerError_5 1;
BA_ "GenSigType" SG_ 2571108357 BATT_vBrickUnderWar_5 1;
BA_ "GenSigType" SG_ 2571108357 BATT_vBrickUnderSev_5 1;
BA_ "GenSigType" SG_ 2571108357 BATT_vBrickUnderMod_5 1;
BA_ "GenSigType" SG_ 2571108357 BATT_vBrickOverWar_5 1;
BA_ "GenSigType" SG_ 2571108357 BATT_vBrickOverSev_5 1;
BA_ "GenSigType" SG_ 2571108357 BATT_vBrickOverMod_5 1;
BA_ "GenSigType" SG_ 2571108357 BATT_vBrickImbalance_5 1;
BA_ "GenSigType" SG_ 2571108357 BATT_loggerAlmostFull_5 1;
BA_ "GenSigType" SG_ 2571108357 BATT_tempModuleUnderWar_5 1;
BA_ "GenSigType" SG_ 2571108357 BATT_tempModuleUnderSev_5 1;
BA_ "GenSigType" SG_ 2571108357 BATT_tempModuleUnderMod_5 1;
BA_ "GenSigType" SG_ 2571108357 BATT_tempModuleOverWar_5 1;
BA_ "GenSigType" SG_ 2571108357 BATT_tempModuleOverSev_5 1;
BA_ "GenSigType" SG_ 2571108357 BATT_tempModuleOverMod_5 1;
BA_ "GenSigType" SG_ 2571108357 BATT_tempBrickImbalance_5 1;
BA_ "GenSigType" SG_ 2571108357 BATT_taskLockupError_5 1;
BA_ "GenSigType" SG_ 2571108357 BATT_tempAmbientOverWar_5 1;
BA_ "GenSigType" SG_ 2571108357 BATT_tempAmbientOverSev_5 1;
BA_ "GenSigType" SG_ 2571108357 BATT_tempAmbientOverMod_5 1;
BA_ "GenSigType" SG_ 2571108357 BATT_sensePackVoltError_5 1;
BA_ "GenSigType" SG_ 2571108357 BATT_senseLoadVoltError_5 1;
BA_ "GenSigType" SG_ 2571108357 BATT_loggerFull_5 1;
BA_ "GenSigType" SG_ 2571108357 BATT_senseCurrentError_5 1;
BA_ "GenSigType" SG_ 2571108357 BATT_senseBrickTempError_5 1;
BA_ "GenSigType" SG_ 2571108357 BATT_resPackHigh_5 1;
BA_ "GenSigType" SG_ 2571108357 BATT_ramOverUtilError_5 1;
BA_ "GenSigType" SG_ 2571108357 BATT_powerPackInsufficient_5 1;
BA_ "GenSigType" SG_ 2571108357 BATT_packCellSoftShort_5 1;
BA_ "GenSigType" SG_ 2571108357 BATT_iOverHardware_5 1;
BA_ "GenSigType" SG_ 2571108357 BATT_fetOverTemp_5 1;
BA_ "GenSigType" SG_ 2571108357 BATT_iOverDischarge_5 1;
BA_ "GenSigType" SG_ 2571108357 BATT_iOverCharge_5 1;
BA_ "GenSigType" SG_ 2571108357 BATT_inverterDriveMIA_5 1;
BA_ "GenSigType" SG_ 2571108357 BATT_iUnderCharge_5 1;
BA_ "GenSigType" SG_ 2571108357 BATT_hostMIA_5 1;
BA_ "GenSigType" SG_ 2571108357 BATT_fetDsgShorted_5 1;
BA_ "GenSigType" SG_ 2571108357 BATT_fetDsgFailToClose_5 1;
BA_ "GenSigType" SG_ 2571108357 BATT_capLow_5 1;
BA_ "GenSigType" SG_ 2571108357 BATT_brickOverDischarge_5 1;
BA_ "GenSigType" SG_ 2571108357 BATT_brickOverCharge_5 1;
BA_ "GenSigType" SG_ 2571108357 BATT_bmsProcessorError_5 1;
BA_ "GenSigType" SG_ 2571108357 BATT_bmsMemoryError_5 1;
BA_ "GenSigType" SG_ 2571108357 BATT_afeError_5 1;
BA_ "GenSigType" SG_ 2571108358 BATT_packModIdFault_6 1;
BA_ "GenSigType" SG_ 2571108358 BATT_packModExitedFromBus_6 1;
BA_ "GenSigType" SG_ 2571108358 BATT_packFetChgWelded_6 1;
BA_ "GenSigType" SG_ 2571108358 BATT_packFetDsgWelded_6 1;
BA_ "GenSigType" SG_ 2571108358 BATT_fetDsgShortedAux_6 1;
BA_ "GenSigType" SG_ 2571108358 BATT_fetChgShortedAux_6 1;
BA_ "GenSigType" SG_ 2571108358 BATT_prechargeFetFail_6 1;
BA_ "GenSigType" SG_ 2571108358 BATT_abnormalResetReason_6 1;
BA_ "GenSigType" SG_ 2571108358 BATT_prechargeTooSlow_6 1;
BA_ "GenSigType" SG_ 2571108358 BATT_prechargeTooFast_6 1;
BA_ "GenSigType" SG_ 2571108358 BATT_prechargeTimeout_6 1;
BA_ "GenSigType" SG_ 2571108358 BATT_fetChgShorted_6 1;
BA_ "GenSigType" SG_ 2571108358 BATT_fetChgFailToClose_6 1;
BA_ "GenSigType" SG_ 2571108358 BATT_packModSelectFault_6 1;
BA_ "GenSigType" SG_ 2571108358 BATT_packModConnectFault_6 1;
BA_ "GenSigType" SG_ 2571108358 BATT_packModMIA_6 1;
BA_ "GenSigType" SG_ 2571108358 BATT_packModImbalance_6 1;
BA_ "GenSigType" SG_ 2571108358 BATT_afeFault_6 1;
BA_ "GenSigType" SG_ 2571108358 BATT_chargerMIA_6 1;
BA_ "GenSigType" SG_ 2571108358 BATT_chargerError_6 1;
BA_ "GenSigType" SG_ 2571108358 BATT_vBrickUnderWar_6 1;
BA_ "GenSigType" SG_ 2571108358 BATT_vBrickUnderSev_6 1;
BA_ "GenSigType" SG_ 2571108358 BATT_vBrickUnderMod_6 1;
BA_ "GenSigType" SG_ 2571108358 BATT_vBrickOverWar_6 1;
BA_ "GenSigType" SG_ 2571108358 BATT_vBrickOverSev_6 1;
BA_ "GenSigType" SG_ 2571108358 BATT_vBrickOverMod_6 1;
BA_ "GenSigType" SG_ 2571108358 BATT_vBrickImbalance_6 1;
BA_ "GenSigType" SG_ 2571108358 BATT_loggerAlmostFull_6 1;
BA_ "GenSigType" SG_ 2571108358 BATT_tempModuleUnderWar_6 1;
BA_ "GenSigType" SG_ 2571108358 BATT_tempModuleUnderSev_6 1;
BA_ "GenSigType" SG_ 2571108358 BATT_tempModuleUnderMod_6 1;
BA_ "GenSigType" SG_ 2571108358 BATT_tempModuleOverWar_6 1;
BA_ "GenSigType" SG_ 2571108358 BATT_tempModuleOverSev_6 1;
BA_ "GenSigType" SG_ 2571108358 BATT_tempModuleOverMod_6 1;
BA_ "GenSigType" SG_ 2571108358 BATT_tempBrickImbalance_6 1;
BA_ "GenSigType" SG_ 2571108358 BATT_taskLockupError_6 1;
BA_ "GenSigType" SG_ 2571108358 BATT_tempAmbientOverWar_6 1;
BA_ "GenSigType" SG_ 2571108358 BATT_tempAmbientOverSev_6 1;
BA_ "GenSigType" SG_ 2571108358 BATT_tempAmbientOverMod_6 1;
BA_ "GenSigType" SG_ 2571108358 BATT_sensePackVoltError_6 1;
BA_ "GenSigType" SG_ 2571108358 BATT_senseLoadVoltError_6 1;
BA_ "GenSigType" SG_ 2571108358 BATT_loggerFull_6 1;
BA_ "GenSigType" SG_ 2571108358 BATT_senseCurrentError_6 1;
BA_ "GenSigType" SG_ 2571108358 BATT_senseBrickTempError_6 1;
BA_ "GenSigType" SG_ 2571108358 BATT_resPackHigh_6 1;
BA_ "GenSigType" SG_ 2571108358 BATT_ramOverUtilError_6 1;
BA_ "GenSigType" SG_ 2571108358 BATT_powerPackInsufficient_6 1;
BA_ "GenSigType" SG_ 2571108358 BATT_packCellSoftShort_6 1;
BA_ "GenSigType" SG_ 2571108358 BATT_iOverHardware_6 1;
BA_ "GenSigType" SG_ 2571108358 BATT_fetOverTemp_6 1;
BA_ "GenSigType" SG_ 2571108358 BATT_iOverDischarge_6 1;
BA_ "GenSigType" SG_ 2571108358 BATT_iOverCharge_6 1;
BA_ "GenSigType" SG_ 2571108358 BATT_inverterDriveMIA_6 1;
BA_ "GenSigType" SG_ 2571108358 BATT_iUnderCharge_6 1;
BA_ "GenSigType" SG_ 2571108358 BATT_hostMIA_6 1;
BA_ "GenSigType" SG_ 2571108358 BATT_fetDsgShorted_6 1;
BA_ "GenSigType" SG_ 2571108358 BATT_fetDsgFailToClose_6 1;
BA_ "GenSigType" SG_ 2571108358 BATT_capLow_6 1;
BA_ "GenSigType" SG_ 2571108358 BATT_brickOverDischarge_6 1;
BA_ "GenSigType" SG_ 2571108358 BATT_brickOverCharge_6 1;
BA_ "GenSigType" SG_ 2571108358 BATT_bmsProcessorError_6 1;
BA_ "GenSigType" SG_ 2571108358 BATT_bmsMemoryError_6 1;
BA_ "GenSigType" SG_ 2571108358 BATT_afeError_6 1;
BA_ "Access" SG_ 2550398976 BATT_manufacturerAccess_0 1;
BA_ "Access" SG_ 2550398977 BATT_manufacturerAccess_1 1;
BA_ "Access" SG_ 2550398978 BATT_manufacturerAccess_2 1;
BA_ "Access" SG_ 2550398979 BATT_manufacturerAccess_3 1;
BA_ "Access" SG_ 2550398980 BATT_manufacturerAccess_4 1;
BA_ "Access" SG_ 2550398981 BATT_manufacturerAccess_5 1;
BA_ "Access" SG_ 2550398982 BATT_manufacturerAccess_6 1;
BA_ "Access" SG_ 2550398983 BATT_manufacturerAccess_7 1;
BA_ "Access" SG_ 2550661120 BATT_serialNumber_0 1;
BA_ "Access" SG_ 2550661121 BATT_serialNumber_1 1;
BA_ "Access" SG_ 2550661122 BATT_serialNumber_2 1;
BA_ "Access" SG_ 2550661123 BATT_serialNumber_3 1;
BA_ "Access" SG_ 2550661124 BATT_serialNumber_4 1;
BA_ "Access" SG_ 2550661125 BATT_serialNumber_5 1;
BA_ "Access" SG_ 2550661126 BATT_serialNumber_6 1;
BA_ "Access" SG_ 2550661127 BATT_serialNumber_7 1;
VAL_ 2483290116 BATT_modStateRequested_4  4 "Connect"  3 "Disconnect"  2 "Charge"  1 "Drive"  0 "Standby"  ;
VAL_ 2483290116 BATT_modDataValid_4  1 "Valid"  0 "Not Valid"  ;
VAL_ 2483290116 BATT_prechargeState_4  6 "Fault"  5 "Complete"  4 "Idle"  3 "P0F1"  2 "P1F1"  1 "P1F0"  0 "P0F0"  ;
VAL_ 2483290116 BATT_fetPchgCommand_4  1 "Close"  0 "Open"  ;
VAL_ 2483290116 BATT_fetDsgCommand_4  1 "Close"  0 "Open"  ;
VAL_ 2483290116 BATT_fetChgCommand_4  1 "Close"  0 "Open"  ;
VAL_ 2483290116 BATT_fetDsgStatus_4  8 "Welded"  7 "OpenPending"  6 "FailToClose"  5 "FailToOpen"  4 "Closing"  3 "Opening"  2 "Closed"  1 "Open"  0 "Unknown"  ;
VAL_ 2483290116 BATT_fetChgStatus_4  8 "Welded"  7 "OpenPending"  6 "FailToClose"  5 "FailToOpen"  4 "Closing"  3 "Opening"  2 "Closed"  1 "Open"  0 "Unknown"  ;
VAL_ 2483290116 BATT_modPackState_4  10 "Disconnect"  9 "ConnectCharge"  8 "ConnectDrive"  7 "SelectCharge"  6 "SelectDrive"  5 "ChargeStandbyConnect"  4 "Reserved"  3 "Charge"  2 "Drive"  1 "StandbyReady"  0 "StandbyNotReady"  ;
VAL_ 2483290116 BATT_modChildState_4  12 "connectbusjoin"  11 "connectbusprecharge"  10 "softdisconnectbus"  9 "disconnectbus"  8 "chargenormal"  7 "drivenormal"  6 "driverampdown"  5 "drivelimp"  4 "standbyready"  3 "standbyfault"  2 "standbynotready"  1 "standbysleeping"  0 "standbysleep"  ;
VAL_ 2483290116 BATT_modParentState_4  4 "Connect"  3 "Disconnect"  2 "Charge"  1 "Drive"  0 "Standby"  ;
VAL_ 2483290117 BATT_modStateRequested_5  4 "Connect"  3 "Disconnect"  2 "Charge"  1 "Drive"  0 "Standby"  ;
VAL_ 2483290117 BATT_modDataValid_5  1 "Valid"  0 "Not Valid"  ;
VAL_ 2483290117 BATT_prechargeState_5  6 "Fault"  5 "Complete"  4 "Idle"  3 "P0F1"  2 "P1F1"  1 "P1F0"  0 "P0F0"  ;
VAL_ 2483290117 BATT_fetPchgCommand_5  1 "Close"  0 "Open"  ;
VAL_ 2483290117 BATT_fetDsgCommand_5  1 "Close"  0 "Open"  ;
VAL_ 2483290117 BATT_fetChgCommand_5  1 "Close"  0 "Open"  ;
VAL_ 2483290117 BATT_fetDsgStatus_5  8 "Welded"  7 "OpenPending"  6 "FailToClose"  5 "FailToOpen"  4 "Closing"  3 "Opening"  2 "Closed"  1 "Open"  0 "Unknown"  ;
VAL_ 2483290117 BATT_fetChgStatus_5  8 "Welded"  7 "OpenPending"  6 "FailToClose"  5 "FailToOpen"  4 "Closing"  3 "Opening"  2 "Closed"  1 "Open"  0 "Unknown"  ;
VAL_ 2483290117 BATT_modPackState_5  10 "Disconnect"  9 "ConnectCharge"  8 "ConnectDrive"  7 "SelectCharge"  6 "SelectDrive"  5 "ChargeStandbyConnect"  4 "Reserved"  3 "Charge"  2 "Drive"  1 "StandbyReady"  0 "StandbyNotReady"  ;
VAL_ 2483290117 BATT_modChildState_5  12 "connectbusjoin"  11 "connectbusprecharge"  10 "softdisconnectbus"  9 "disconnectbus"  8 "chargenormal"  7 "drivenormal"  6 "driverampdown"  5 "drivelimp"  4 "standbyready"  3 "standbyfault"  2 "standbynotready"  1 "standbysleeping"  0 "standbysleep"  ;
VAL_ 2483290117 BATT_modParentState_5  4 "Connect"  3 "Disconnect"  2 "Charge"  1 "Drive"  0 "Standby"  ;
VAL_ 2483290118 BATT_modStateRequested_6  4 "Connect"  3 "Disconnect"  2 "Charge"  1 "Drive"  0 "Standby"  ;
VAL_ 2483290118 BATT_modDataValid_6  1 "Valid"  0 "Not Valid"  ;
VAL_ 2483290118 BATT_prechargeState_6  6 "Fault"  5 "Complete"  4 "Idle"  3 "P0F1"  2 "P1F1"  1 "P1F0"  0 "P0F0"  ;
VAL_ 2483290118 BATT_fetPchgCommand_6  1 "Close"  0 "Open"  ;
VAL_ 2483290118 BATT_fetDsgCommand_6  1 "Close"  0 "Open"  ;
VAL_ 2483290118 BATT_fetChgCommand_6  1 "Close"  0 "Open"  ;
VAL_ 2483290118 BATT_fetDsgStatus_6  8 "Welded"  7 "OpenPending"  6 "FailToClose"  5 "FailToOpen"  4 "Closing"  3 "Opening"  2 "Closed"  1 "Open"  0 "Unknown"  ;
VAL_ 2483290118 BATT_fetChgStatus_6  8 "Welded"  7 "OpenPending"  6 "FailToClose"  5 "FailToOpen"  4 "Closing"  3 "Opening"  2 "Closed"  1 "Open"  0 "Unknown"  ;
VAL_ 2483290118 BATT_modPackState_6  10 "Disconnect"  9 "ConnectCharge"  8 "ConnectDrive"  7 "SelectCharge"  6 "SelectDrive"  5 "ChargeStandbyConnect"  4 "Reserved"  3 "Charge"  2 "Drive"  1 "StandbyReady"  0 "StandbyNotReady"  ;
VAL_ 2483290118 BATT_modChildState_6  12 "connectbusjoin"  11 "connectbusprecharge"  10 "softdisconnectbus"  9 "disconnectbus"  8 "chargenormal"  7 "drivenormal"  6 "driverampdown"  5 "drivelimp"  4 "standbyready"  3 "standbyfault"  2 "standbynotready"  1 "standbysleeping"  0 "standbysleep"  ;
VAL_ 2483290118 BATT_modParentState_6  4 "Connect"  3 "Disconnect"  2 "Charge"  1 "Drive"  0 "Standby"  ;
VAL_ 2483290119 BATT_modStateRequested_7  4 "Connect"  3 "Disconnect"  2 "Charge"  1 "Drive"  0 "Standby"  ;
VAL_ 2483290119 BATT_modDataValid_7  1 "Valid"  0 "Not Valid"  ;
VAL_ 2483290119 BATT_prechargeState_7  6 "Fault"  5 "Complete"  4 "Idle"  3 "P0F1"  2 "P1F1"  1 "P1F0"  0 "P0F0"  ;
VAL_ 2483290119 BATT_fetPchgCommand_7  1 "Close"  0 "Open"  ;
VAL_ 2483290119 BATT_fetDsgCommand_7  1 "Close"  0 "Open"  ;
VAL_ 2483290119 BATT_fetChgCommand_7  1 "Close"  0 "Open"  ;
VAL_ 2483290119 BATT_fetDsgStatus_7  8 "Welded"  7 "OpenPending"  6 "FailToClose"  5 "FailToOpen"  4 "Closing"  3 "Opening"  2 "Closed"  1 "Open"  0 "Unknown"  ;
VAL_ 2483290119 BATT_fetChgStatus_7  8 "Welded"  7 "OpenPending"  6 "FailToClose"  5 "FailToOpen"  4 "Closing"  3 "Opening"  2 "Closed"  1 "Open"  0 "Unknown"  ;
VAL_ 2483290119 BATT_modPackState_7  10 "Disconnect"  9 "ConnectCharge"  8 "ConnectDrive"  7 "SelectCharge"  6 "SelectDrive"  5 "ChargeStandbyConnect"  4 "Reserved"  3 "Charge"  2 "Drive"  1 "StandbyReady"  0 "StandbyNotReady"  ;
VAL_ 2483290119 BATT_modChildState_7  12 "connectbusjoin"  11 "connectbusprecharge"  10 "softdisconnectbus"  9 "disconnectbus"  8 "chargenormal"  7 "drivenormal"  6 "driverampdown"  5 "drivelimp"  4 "standbyready"  3 "standbyfault"  2 "standbynotready"  1 "standbysleeping"  0 "standbysleep"  ;
VAL_ 2483290119 BATT_modParentState_7  4 "Connect"  3 "Disconnect"  2 "Charge"  1 "Drive"  0 "Standby"  ;
VAL_ 2550661120 BATT_deviceChemistry_0  7 "LiP"  6 "ZnAr"  5 "RAM"  4 "NiZn"  3 "NiMH"  2 "NiCd"  1 "LION"  0 "PbAc"  ;
VAL_ 2550661121 BATT_deviceChemistry_1  7 "LiP"  6 "ZnAr"  5 "RAM"  4 "NiZn"  3 "NiMH"  2 "NiCd"  1 "LION"  0 "PbAc"  ;
VAL_ 2550661122 BATT_deviceChemistry_2  7 "LiP"  6 "ZnAr"  5 "RAM"  4 "NiZn"  3 "NiMH"  2 "NiCd"  1 "LION"  0 "PbAc"  ;
VAL_ 2550661123 BATT_deviceChemistry_3  7 "LiP"  6 "ZnAr"  5 "RAM"  4 "NiZn"  3 "NiMH"  2 "NiCd"  1 "LION"  0 "PbAc"  ;
VAL_ 2550661124 BATT_deviceChemistry_4  7 "LiP"  6 "ZnAr"  5 "RAM"  4 "NiZn"  3 "NiMH"  2 "NiCd"  1 "LION"  0 "PbAc"  ;
VAL_ 2550661125 BATT_deviceChemistry_5  7 "LiP"  6 "ZnAr"  5 "RAM"  4 "NiZn"  3 "NiMH"  2 "NiCd"  1 "LION"  0 "PbAc"  ;
VAL_ 2550661126 BATT_deviceChemistry_6  7 "LiP"  6 "ZnAr"  5 "RAM"  4 "NiZn"  3 "NiMH"  2 "NiCd"  1 "LION"  0 "PbAc"  ;
VAL_ 2550661127 BATT_deviceChemistry_7  7 "LiP"  6 "ZnAr"  5 "RAM"  4 "NiZn"  3 "NiMH"  2 "NiCd"  1 "LION"  0 "PbAc"  ;
